VERSION ""

NS_ :

BS_:

BU_: Sound_A Ladegeraet_PAG_PF Motor_EDC17_Pirol PSM_Ant_Derivate GW_Routing_Derivate GW_Applikation_Derivate BMS_Hybrid Getriebe_Derivate LEH_Hybrid Motor_MED17_Hybrid Sound_I Tool Airbag Waehlhebel

BO_ 157 Motor_Hybrid_01: 8 Motor_MED17_Hybrid
 SG_ MO_HYB_EMode_Info : 14|2@1+ (1,0) [0|3] ""  Getriebe_Derivate
 SG_ Motor_Hybrid_01_CHK : 0|8@1+ (1,0) [0|255] ""  Getriebe_Derivate
 SG_ Motor_Hybrid_01_BZ : 8|4@1+ (1,0) [0|15] ""  BMS_Hybrid,Getriebe_Derivate
 SG_ MO_HYB_IstStatusK0 : 12|2@1+ (1,0) [0|3] ""  Getriebe_Derivate
 SG_ MO_HYB_max_ind_VM_Mom : 16|10@1+ (1,0) [0|1021] "Unit_NewtoMeter"  Getriebe_Derivate
 SG_ MO_HYB_Zielzustand : 26|3@1+ (1,0) [0|7] ""  BMS_Hybrid,Getriebe_Derivate
 SG_ MO_HYB_Startmodus : 29|3@1+ (1,0) [0|7] ""  Getriebe_Derivate
 SG_ MO_HYB_Startmodus_PQ3x : 32|1@1+ (1,0) [0|1] "" Vector__XXX
 SG_ MO_HYB_Stoppmodus : 33|1@1+ (1,0) [0|1] "" Vector__XXX
 SG_ MO_HYB_VM_Mom_oE : 40|10@1+ (1,-100) [-100|922] "Unit_NewtoMeter"  Getriebe_Derivate
 SG_ MO_HYB_VM_aktiv : 50|1@1+ (1,0) [0|1] ""  BMS_Hybrid,Getriebe_Derivate,GW_Routing_Derivate
 SG_ MO_HYB_Schaltverhinderung : 51|1@1+ (1,0) [0|1] ""  Getriebe_Derivate
 SG_ MO_HYB_Selektor_Momverlauf_EM M : 53|3@1+ (1,0) [0|7] ""  Getriebe_Derivate
 SG_ MO_HYB_Momverlauf_Rek m1 : 56|8@1+ (2,0) [0|510] "Unit_NewtoMeter"  Getriebe_Derivate
 SG_ MO_HYB_KnickDZ_Rek m2 : 56|8@1+ (12.5,0) [0|3150] "Unit_MinutInver"  Getriebe_Derivate
 SG_ MO_HYB_Momverlauf_EM m3 : 56|8@1+ (2,0) [0|510] "Unit_NewtoMeter"  Getriebe_Derivate
 SG_ MO_HYB_KnickDZ_EM m4 : 56|8@1+ (12.5,0) [0|3150] "Unit_MinutInver"  Getriebe_Derivate

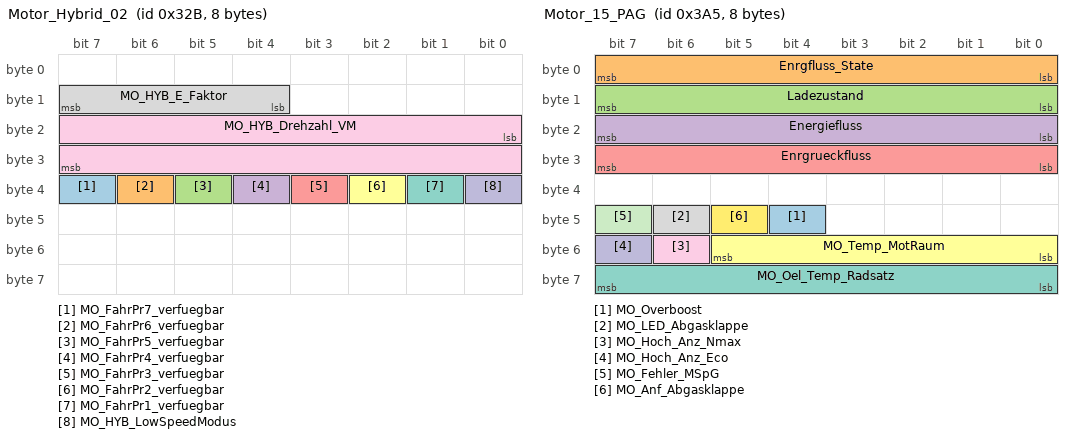
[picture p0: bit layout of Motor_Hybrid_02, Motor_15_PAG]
BO_ 811 Motor_Hybrid_02: 8 Motor_MED17_Hybrid
 SG_ MO_FahrPr7_verfuegbar : 39|1@1+ (1,0) [0|1] ""  GW_Routing_Derivate
 SG_ MO_FahrPr6_verfuegbar : 38|1@1+ (1,0) [0|1] ""  GW_Routing_Derivate
 SG_ MO_FahrPr5_verfuegbar : 37|1@1+ (1,0) [0|1] ""  GW_Routing_Derivate
 SG_ MO_FahrPr4_verfuegbar : 36|1@1+ (1,0) [0|1] ""  GW_Routing_Derivate
 SG_ MO_FahrPr3_verfuegbar : 35|1@1+ (1,0) [0|1] ""  GW_Routing_Derivate
 SG_ MO_FahrPr2_verfuegbar : 34|1@1+ (1,0) [0|1] ""  GW_Routing_Derivate
 SG_ MO_FahrPr1_verfuegbar : 33|1@1+ (1,0) [0|1] ""  GW_Routing_Derivate
 SG_ MO_HYB_E_Faktor : 12|4@1+ (1,0) [0|15] ""  Getriebe_Derivate,GW_Routing_Derivate
 SG_ MO_HYB_Drehzahl_VM : 16|16@1+ (0.25,0) [0|16256] "Unit_MinutInver"  Getriebe_Derivate,GW_Routing_Derivate,BMS_Hybrid
 SG_ MO_HYB_LowSpeedModus : 32|1@1+ (1,0) [0|1] ""  Getriebe_Derivate,GW_Routing_Derivate

BO_ 933 Motor_15_PAG: 8 Motor_MED17_Hybrid
 SG_ MO_Overboost : 44|1@1+ (1,0) [0|1] ""  GW_Routing_Derivate
 SG_ Enrgfluss_State : 0|8@1+ (1,0) [0|255] ""  GW_Routing_Derivate
 SG_ Ladezustand : 8|8@1+ (1,0) [0|100] "Unit_PerCent"  GW_Routing_Derivate
 SG_ Energiefluss : 16|8@1+ (1,-128) [-100|100] "Unit_PerCent"  GW_Routing_Derivate
 SG_ Enrgrueckfluss : 24|8@1+ (0.2,0) [0|50.8] ""  GW_Routing_Derivate
 SG_ MO_Temp_MotRaum : 48|6@1+ (3,-48) [-48|141] "Unit_DegreCelsi"  GW_Routing_Derivate
 SG_ MO_Oel_Temp_Radsatz : 56|8@1+ (1,-60) [-60|193] "Unit_DegreCelsi"  GW_Routing_Derivate
 SG_ MO_LED_Abgasklappe : 46|1@1+ (1,0) [0|1] ""  GW_Routing_Derivate
 SG_ MO_Hoch_Anz_Nmax : 54|1@1+ (1,0) [0|1] ""  GW_Routing_Derivate
 SG_ MO_Hoch_Anz_Eco : 55|1@1+ (1,0) [0|1] ""  GW_Routing_Derivate
 SG_ MO_Fehler_MSpG : 47|1@1+ (1,0) [0|1] ""  GW_Routing_Derivate
 SG_ MO_Anf_Abgasklappe : 45|1@1+ (1,0) [0|1] ""  GW_Routing_Derivate

BO_ 1730 NMH_Getriebe: 7 Getriebe_Derivate
 SG_ NMH_GE_N_Haltephase : 19|1@1+ (1,0) [0|1] "" Vector__XXX
 SG_ NMH_GE_Start_1 : 0|1@1+ (1,0) [0|1] ""  Motor_EDC17_Pirol,BMS_Hybrid,LEH_Hybrid,Ladegeraet_PAG_PF,GW_Applikation_Derivate,Motor_MED17_Hybrid
 SG_ NMH_GE_Start_2 : 1|1@1+ (1,0) [0|1] ""  GW_Applikation_Derivate
 SG_ NMH_GE_Normal_Mode_1 : 2|1@1+ (1,0) [0|1] ""  GW_Applikation_Derivate
 SG_ NMH_GE_Normal_Mode_2 : 3|1@1+ (1,0) [0|1] ""  GW_Applikation_Derivate
 SG_ NMH_GE_Car_WakeUp : 6|1@1+ (1,0) [0|1] "" Vector__XXX
 SG_ NMH_GE_Per_WakeUp : 8|5@1+ (1,0) [0|31] "" Vector__XXX
 SG_ NMH_GE_Fkt_WakeUp : 13|3@1+ (1,0) [0|7] "" Vector__XXX
 SG_ NMH_GE_NM_aktiv_Klemme_15 : 16|1@1+ (1,0) [0|1] "" Vector__XXX
 SG_ NMH_GE_NM_aktiv_Diagnose : 17|1@1+ (1,0) [0|1] "" Vector__XXX
 SG_ NMH_GE_NM_aktiv_Start : 18|1@1+ (1,0) [0|1] "" Vector__XXX
 SG_ NMH_GE_kein_NL : 24|1@1+ (1,0) [0|1] "" Vector__XXX
 SG_ NMH_GE_NL_Daten_EEPROM : 25|1@1+ (1,0) [0|1] "" Vector__XXX
 SG_ NMH_GE_NL_Drucksens : 26|1@1+ (1,0) [0|1] "" Vector__XXX
 SG_ NMH_GE_NL_Abtrieb : 27|1@1+ (1,0) [0|1] "" Vector__XXX
 SG_ NMH_GE_NL_Waehlhebel : 28|1@1+ (1,0) [0|1] "" Vector__XXX
 SG_ NMH_GE_NL_Wegfahrsperre : 29|1@1+ (1,0) [0|1] "" Vector__XXX
 SG_ NM_GE_Signalfehler : 32|1@1+ (1,0) [0|1] "" Vector__XXX
 SG_ NMH_GE_TimeOut_Fehler : 33|1@1+ (1,0) [0|1] "" Vector__XXX
 SG_ NMH_GE_CAN_Diag_deaktiv : 34|1@1+ (1,0) [0|1] "" Vector__XXX
 SG_ NMH_GE_KompSchutz : 35|1@1+ (1,0) [0|1] "" Vector__XXX
 SG_ NMH_GE_Mute_Mode : 36|1@1+ (1,0) [0|1] "" Vector__XXX
 SG_ NMH_GE_Transport_Mode : 37|1@1+ (1,0) [0|1] "" Vector__XXX
 SG_ NMH_GE_Abschaltstufe_aktiv : 38|1@1+ (1,0) [0|1] "" Vector__XXX
 SG_ NMH_GE_Eindraht_Fehler : 39|1@1+ (1,0) [0|1] "" Vector__XXX
 SG_ NMH_GE_Lokalaktiv : 48|1@1+ (1,0) [0|1] "" Vector__XXX
 SG_ NMH_GE_Subsystemaktiv : 49|1@1+ (1,0) [0|1] "" Vector__XXX
 SG_ NMH_GSG_Subbusaktiv : 50|1@1+ (1,0) [0|1] "" Vector__XXX

BO_ 1729 NMH_Motor: 7 Motor_MED17_Hybrid
 SG_ NMH_MO_Start_1 : 0|1@1+ (1,0) [0|1] ""  BMS_Hybrid,LEH_Hybrid,Ladegeraet_PAG_PF,GW_Applikation_Derivate,Getriebe_Derivate
 SG_ NMH_MO_Start_2 : 1|1@1+ (1,0) [0|1] ""  GW_Applikation_Derivate
 SG_ NMH_MO_Normal_Mode_1 : 2|1@1+ (1,0) [0|1] ""  GW_Applikation_Derivate
 SG_ NMH_MO_NM_aktiv_HV_Abschaltung : 21|1@1+ (1,0) [0|1] "" Vector__XXX
 SG_ NMH_MO_Normal_Mode_2 : 3|1@1+ (1,0) [0|1] ""  GW_Applikation_Derivate
 SG_ NMH_MO_Car_WakeUp : 6|1@1+ (1,0) [0|1] "" Vector__XXX
 SG_ NMH_MO_Per_WakeUp : 8|5@1+ (1,0) [0|31] "" Vector__XXX
 SG_ NMH_MO_Fkt_WakeUp : 13|3@1+ (1,0) [0|7] "" Vector__XXX
 SG_ NMH_MO_NM_aktiv_Klemme_15 : 16|1@1+ (1,0) [0|1] "" Vector__XXX
 SG_ NMH_MO_NM_aktiv_Diagnose : 17|1@1+ (1,0) [0|1] "" Vector__XXX
 SG_ NMH_MO_NM_aktiv_Start : 18|1@1+ (1,0) [0|1] "" Vector__XXX
 SG_ NMH_MO_NM_aktiv_EKP_Vorlauf : 19|1@1+ (1,0) [0|1] "" Vector__XXX
 SG_ NMH_MO_NM_aktiv_STH_Betrieb : 20|1@1+ (1,0) [0|1] "" Vector__XXX
 SG_ NMH_MO_kein_NL : 24|1@1+ (1,0) [0|1] "" Vector__XXX
 SG_ NMH_MO_NL_Kuehlerluefter : 25|1@1+ (1,0) [0|1] "" Vector__XXX
 SG_ NMH_MO_NL_Diagnose : 26|1@1+ (1,0) [0|1] "" Vector__XXX
 SG_ NMH_MO_NL_WFS : 27|1@1+ (1,0) [0|1] "" Vector__XXX
 SG_ NMH_MO_NL_EEPROM : 28|1@1+ (1,0) [0|1] "" Vector__XXX
 SG_ NMH_MO_NL_Sonstige : 29|1@1+ (1,0) [0|1] "" Vector__XXX
 SG_ NM_MO_Signalfehler : 32|1@1+ (1,0) [0|1] "" Vector__XXX
 SG_ NMH_MO_TimeOut_Fehler : 33|1@1+ (1,0) [0|1] "" Vector__XXX
 SG_ NMH_MO_CAN_Diag_deaktiv : 34|1@1+ (1,0) [0|1] "" Vector__XXX
 SG_ NMH_MO_KompSchutz : 35|1@1+ (1,0) [0|1] "" Vector__XXX
 SG_ NMH_MO_Mute_Mode : 36|1@1+ (1,0) [0|1] "" Vector__XXX
 SG_ NMH_MO_Transport_Mode : 37|1@1+ (1,0) [0|1] "" Vector__XXX
 SG_ NMH_MO_Abschaltstufe_aktiv : 38|1@1+ (1,0) [0|1] "" Vector__XXX
 SG_ NMH_MO_Eindraht_Fehler : 39|1@1+ (1,0) [0|1] "" Vector__XXX
 SG_ NMH_MO_Lokalaktiv : 48|1@1+ (1,0) [0|1] "" Vector__XXX
 SG_ NMH_MO_Subsystemaktiv : 49|1@1+ (1,0) [0|1] "" Vector__XXX

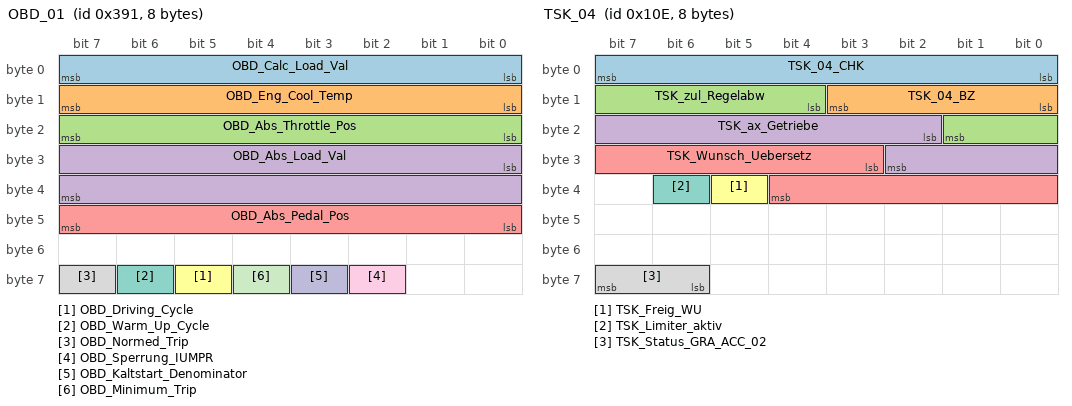
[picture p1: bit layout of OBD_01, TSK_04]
BO_ 913 OBD_01: 8 Motor_MED17_Hybrid
 SG_ OBD_Calc_Load_Val : 0|8@1+ (0.39215686275,0) [0|100] "Unit_PerCent"  BMS_Hybrid,Getriebe_Derivate,LEH_Hybrid
 SG_ OBD_Eng_Cool_Temp : 8|8@1+ (1,-40) [-40|215] "Unit_DegreCelsi"  BMS_Hybrid,Getriebe_Derivate,LEH_Hybrid
 SG_ OBD_Abs_Throttle_Pos : 16|8@1+ (0.39215686275,0) [0|100] "Unit_PerCent"  BMS_Hybrid,Getriebe_Derivate,LEH_Hybrid
 SG_ OBD_Abs_Load_Val : 24|16@1+ (0.39215686275,0) [0|25700] "Unit_PerCent"  BMS_Hybrid,Getriebe_Derivate,LEH_Hybrid
 SG_ OBD_Abs_Pedal_Pos : 40|8@1+ (0.39215686275,0) [0|100] "Unit_PerCent"  BMS_Hybrid,Getriebe_Derivate,LEH_Hybrid
 SG_ OBD_Driving_Cycle : 61|1@1+ (1,0) [0|1] ""  BMS_Hybrid,Getriebe_Derivate,LEH_Hybrid
 SG_ OBD_Warm_Up_Cycle : 62|1@1+ (1,0) [0|1] ""  BMS_Hybrid,Getriebe_Derivate,LEH_Hybrid,GW_Applikation_Derivate
 SG_ OBD_Normed_Trip : 63|1@1+ (1,0) [0|1] ""  LEH_Hybrid,BMS_Hybrid,Getriebe_Derivate
 SG_ OBD_Sperrung_IUMPR : 58|1@1+ (1,0) [0|1] ""  BMS_Hybrid
 SG_ OBD_Kaltstart_Denominator : 59|1@1+ (1,0) [0|1] ""  LEH_Hybrid,BMS_Hybrid
 SG_ OBD_Minimum_Trip : 60|1@1+ (1,0) [0|1] ""  LEH_Hybrid,Getriebe_Derivate,BMS_Hybrid

BO_ 270 TSK_04: 8 Motor_MED17_Hybrid
 SG_ TSK_04_CHK : 0|8@1+ (1,0) [0|255] ""  Getriebe_Derivate
 SG_ TSK_04_BZ : 8|4@1+ (1,0) [0|15] ""  Getriebe_Derivate
 SG_ TSK_zul_Regelabw : 12|6@1+ (0.024,0) [0|1.512] "Unit_MeterPerSeconSquar"  Getriebe_Derivate
 SG_ TSK_ax_Getriebe : 18|9@1+ (0.024,-2.016) [-2.016|10.224] "Unit_MeterPerSeconSquar"  Getriebe_Derivate
 SG_ TSK_Wunsch_Uebersetz : 27|10@1+ (0.0245,0) [0.0245|25.0635] "" Vector__XXX
 SG_ TSK_Freig_WU : 37|1@1+ (1,0) [0|1] "" Vector__XXX
 SG_ TSK_Limiter_aktiv : 38|1@1+ (1,0) [0|1] ""  Getriebe_Derivate
 SG_ TSK_Status_GRA_ACC_02 : 62|2@1+ (1,0) [0|3] ""  Getriebe_Derivate

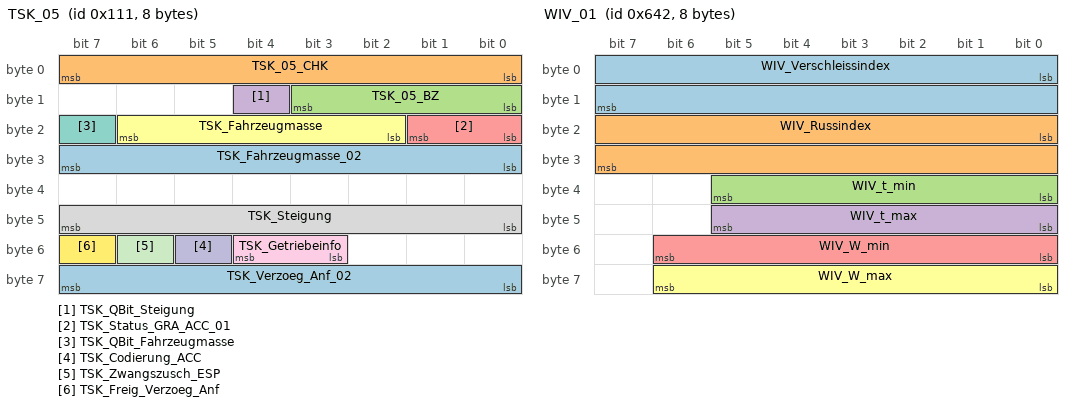
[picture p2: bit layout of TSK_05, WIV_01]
BO_ 273 TSK_05: 8 Motor_MED17_Hybrid
 SG_ TSK_Fahrzeugmasse_02 : 24|8@1+ (32,0) [0|8128] "Unit_KiloGram"  GW_Routing_Derivate
 SG_ TSK_05_CHK : 0|8@1+ (1,0) [0|255] ""  PSM_Ant_Derivate,GW_Routing_Derivate,Getriebe_Derivate
 SG_ TSK_05_BZ : 8|4@1+ (1,0) [0|15] ""  PSM_Ant_Derivate,GW_Routing_Derivate,Getriebe_Derivate
 SG_ TSK_QBit_Steigung : 12|1@1+ (1,0) [0|1] ""  GW_Routing_Derivate
 SG_ TSK_Status_GRA_ACC_01 : 16|2@1+ (1,0) [0|3] ""  PSM_Ant_Derivate,GW_Routing_Derivate
 SG_ TSK_Fahrzeugmasse : 18|5@1+ (200,500) [500|6500] "Unit_KiloGram"  Getriebe_Derivate,GW_Routing_Derivate
 SG_ TSK_QBit_Fahrzeugmasse : 23|1@1+ (1,0) [0|1] ""  GW_Routing_Derivate
 SG_ TSK_Steigung : 40|8@1+ (0.8,-101.6) [-101.6|101.6] "Unit_PerCent"  GW_Routing_Derivate
 SG_ TSK_Getriebeinfo : 51|2@1+ (1,0) [0|3] ""  GW_Routing_Derivate
 SG_ TSK_Codierung_ACC : 53|1@1+ (1,0) [0|1] ""  GW_Routing_Derivate
 SG_ TSK_Zwangszusch_ESP : 54|1@1+ (1,0) [0|1] ""  GW_Routing_Derivate
 SG_ TSK_Freig_Verzoeg_Anf : 55|1@1+ (1,0) [0|1] ""  GW_Routing_Derivate
 SG_ TSK_Verzoeg_Anf_02 : 56|8@1+ (0.024,-3.984) [-3.984|2.136] "Unit_MeterPerSeconSquar"  GW_Routing_Derivate

BO_ 915 WBA_02: 8 Getriebe_Derivate
 SG_ GE_Tipschaltempf_verfuegbar m0 : 43|1@1+ (1,0) [0|1] ""  GW_Routing_Derivate
 SG_ GE_Sollgang m0 : 44|4@1+ (1,0) [0|15] ""  GW_Routing_Derivate
 SG_ WBA_GE_Zusatzwarnungen m0 : 39|3@1+ (1,0) [0|7] ""  GW_Routing_Derivate
 SG_ WBA_Effizienzmodus : 14|1@1+ (1,0) [0|1] ""  GW_Routing_Derivate
 SG_ WBA_Sollgang m1 : 28|4@1+ (1,0) [0|15] ""  GW_Routing_Derivate
 SG_ WBA_02_BZ : 8|4@1+ (1,0) [0|15] ""  GW_Routing_Derivate
 SG_ WBA_Senderkennung M : 12|1@1+ (1,0) [0|1] ""  GW_Routing_Derivate
 SG_ WBA_Lampe_Shift_Lock m0 : 13|1@1+ (1,0) [0|1] ""  GW_Routing_Derivate
 SG_ WBA_Blinken m0 : 16|1@1+ (1,0) [0|1] ""  GW_Routing_Derivate
 SG_ WBA_Getriebevariante m0 : 17|4@1+ (1,0) [0|15] ""  GW_Routing_Derivate
 SG_ WBA_GE_Warnung : 21|3@1+ (1,0) [0|7] ""  GW_Routing_Derivate
 SG_ WBA_Fahrstufe m0 : 24|4@1+ (1,0) [0|15] ""  GW_Routing_Derivate
 SG_ WBA_Schaltempf_verfbar m1 : 13|1@1+ (1,0) [0|1] ""  GW_Routing_Derivate
 SG_ WBA_eing_Gang m0 : 28|4@1+ (1,0) [0|15] ""  GW_Routing_Derivate
 SG_ WBA_Istgang m1 : 24|4@1+ (1,0) [0|15] ""  GW_Routing_Derivate
 SG_ WBA_GE_Texte m0 : 32|3@1+ (1,0) [0|7] ""  GW_Routing_Derivate
 SG_ WBA_Schaltschema_Aktiv m0 : 35|1@1+ (1,0) [0|1] ""  GW_Routing_Derivate
 SG_ WH_Warnung m0 : 36|3@1+ (1,0) [0|7] ""  GW_Routing_Derivate
 SG_ WBA_02_CHK : 0|8@1+ (1,0) [0|255] ""  GW_Routing_Derivate

BO_ 1602 WIV_01: 8 Motor_MED17_Hybrid
 SG_ WIV_Verschleissindex : 0|16@1+ (2E-008,0) [0|0.00131068] ""  GW_Routing_Derivate
 SG_ WIV_Russindex : 16|16@1+ (2E-008,0) [0|0.00131068] ""  GW_Routing_Derivate
 SG_ WIV_t_min : 32|6@1+ (1,0) [0|63] "Unit_Month"  GW_Routing_Derivate
 SG_ WIV_t_max : 40|6@1+ (1,0) [0|63] "Unit_Month"  GW_Routing_Derivate
 SG_ WIV_W_min : 48|7@1+ (1000,0) [0|127000] "Unit_KiloMeter"  GW_Routing_Derivate
 SG_ WIV_W_max : 56|7@1+ (1000,0) [0|127000] "Unit_KiloMeter"  GW_Routing_Derivate

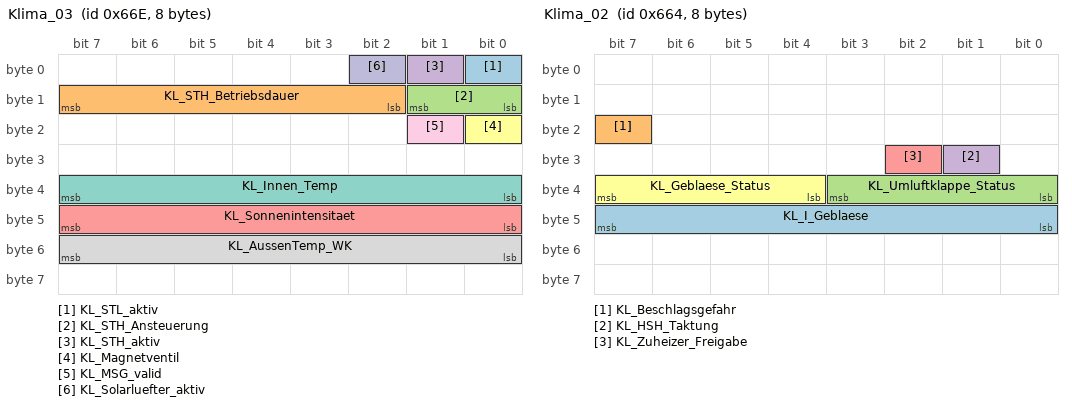
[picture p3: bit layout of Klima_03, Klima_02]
BO_ 1646 Klima_03: 8 GW_Routing_Derivate
 SG_ KL_STL_aktiv : 0|1@1+ (1,0) [0|1] "" Vector__XXX
 SG_ KL_STH_Betriebsdauer : 10|6@1+ (1,0) [0|60] "min" Vector__XXX
 SG_ KL_STH_Ansteuerung : 8|2@1+ (1,0) [0|3] "" Vector__XXX
 SG_ KL_STH_aktiv : 1|1@1+ (1,0) [0|1] "" Vector__XXX
 SG_ KL_Sonnenintensitaet : 40|8@1+ (10,0) [0|1000] "W/qm" Vector__XXX
 SG_ KL_Magnetventil : 16|1@1+ (1,0) [0|1] "" Vector__XXX
 SG_ KL_Innen_Temp : 32|8@1+ (0.5,-50) [-50|77.5] "°C"  BMS_Hybrid
 SG_ KL_AussenTemp_WK : 48|8@1+ (0.5,-50) [-50|76] "°C"  BMS_Hybrid
 SG_ KL_MSG_valid : 17|1@1+ (1,0) [0|1] "" Vector__XXX
 SG_ KL_Solarluefter_aktiv : 2|1@1+ (1,0) [0|1] "" Vector__XXX

BO_ 1636 Klima_02: 8 GW_Routing_Derivate
 SG_ KL_I_Geblaese : 40|8@1+ (0.25,0) [0|63.5] "Unit_Amper" Vector__XXX
 SG_ KL_Beschlagsgefahr : 23|1@1+ (1,0) [0|1] "" Vector__XXX
 SG_ KL_Umluftklappe_Status : 32|4@1+ (1,0) [0|15] ""  BMS_Hybrid
 SG_ KL_HSH_Taktung : 25|1@1+ (1,0) [0|1] "" Vector__XXX
 SG_ KL_Zuheizer_Freigabe : 26|1@1+ (1,0) [0|1] "" Vector__XXX
 SG_ KL_Geblaese_Status : 36|4@1+ (1,0) [0|15] ""  BMS_Hybrid

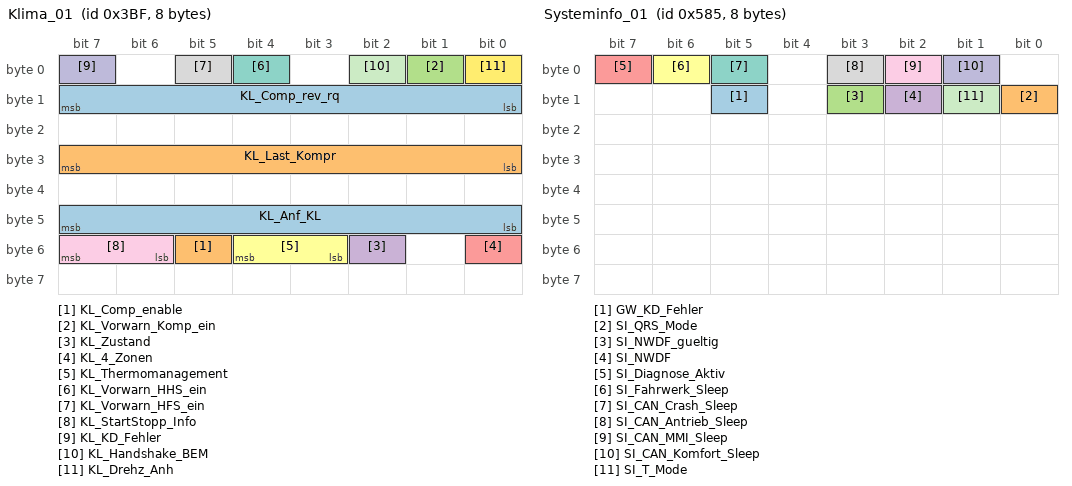
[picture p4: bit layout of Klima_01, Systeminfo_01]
BO_ 959 Klima_01: 8 GW_Routing_Derivate
 SG_ KL_Comp_rev_rq : 8|8@1+ (50,0) [0|8600] "Unit_MinutInver" Vector__XXX
 SG_ KL_Comp_enable : 53|1@1+ (1,0) [0|1] "" Vector__XXX
 SG_ KL_Vorwarn_Komp_ein : 1|1@1+ (1,0) [0|1] ""  Motor_EDC17_Pirol,Motor_MED17_Hybrid
 SG_ KL_Zustand : 50|1@1+ (1,0) [0|1] ""  BMS_Hybrid,Motor_EDC17_Pirol,Motor_MED17_Hybrid
 SG_ KL_4_Zonen : 48|1@1+ (1,0) [0|1] ""  Motor_EDC17_Pirol,Motor_MED17_Hybrid
 SG_ KL_Thermomanagement : 51|2@1+ (1,0) [0|3] ""  Motor_EDC17_Pirol,Motor_MED17_Hybrid
 SG_ KL_Vorwarn_HHS_ein : 4|1@1+ (1,0) [0|1] ""  Motor_EDC17_Pirol,Motor_MED17_Hybrid
 SG_ KL_Vorwarn_HFS_ein : 5|1@1+ (1,0) [0|1] ""  Motor_EDC17_Pirol,Motor_MED17_Hybrid
 SG_ KL_StartStopp_Info : 54|2@1+ (1,0) [0|3] ""  Motor_EDC17_Pirol,Motor_MED17_Hybrid
 SG_ KL_KD_Fehler : 7|1@1+ (1,0) [0|1] "" Vector__XXX
 SG_ KL_Handshake_BEM : 2|1@1+ (1,0) [0|1] "" Vector__XXX
 SG_ KL_Drehz_Anh : 0|1@1+ (1,0) [0|1] ""  Motor_EDC17_Pirol,Motor_MED17_Hybrid
 SG_ KL_Anf_KL : 40|8@1+ (0.4,0) [0|100] "%"  Motor_EDC17_Pirol,Motor_MED17_Hybrid
 SG_ KL_Last_Kompr : 24|8@1+ (0.25,0) [0|63.5] "Nm"  Motor_EDC17_Pirol

BO_ 2041 Response_Airbag_Deployment: 8 Airbag
 SG_ Response_Airbag_Deployment : 0|64@1+ (1,0) [0|4294967295] ""  GW_Routing_Derivate

BO_ 2033 Request_Airbag_Deployment: 8 GW_Routing_Derivate
 SG_ Request_Airbag_Deployment : 0|64@1+ (1,0) [0|4294967295] ""  Airbag

BO_ 1413 Systeminfo_01: 8 GW_Applikation_Derivate
 SG_ GW_KD_Fehler : 13|1@1+ (1,0) [0|1] "" Vector__XXX
 SG_ SI_QRS_Mode : 8|1@1+ (1,0) [0|1] ""  Motor_MED17_Hybrid,Motor_EDC17_Pirol
 SG_ SI_NWDF_gueltig : 11|1@1+ (1,0) [0|1] "" Vector__XXX
 SG_ SI_NWDF : 10|1@1+ (1,0) [0|1] "" Vector__XXX
 SG_ SI_Diagnose_Aktiv : 7|1@1+ (1,0) [0|1] "" Vector__XXX
 SG_ SI_Fahrwerk_Sleep : 6|1@1+ (1,0) [0|1] "" Vector__XXX
 SG_ SI_CAN_Crash_Sleep : 5|1@1+ (1,0) [0|1] "" Vector__XXX
 SG_ SI_CAN_Antrieb_Sleep : 3|1@1+ (1,0) [0|1] "" Vector__XXX
 SG_ SI_CAN_MMI_Sleep : 2|1@1+ (1,0) [0|1] "" Vector__XXX
 SG_ SI_CAN_Komfort_Sleep : 1|1@1+ (1,0) [0|1] "" Vector__XXX
 SG_ SI_T_Mode : 9|1@1+ (1,0) [0|1] ""  Motor_EDC17_Pirol,Motor_MED17_Hybrid,Airbag

BO_ 2616986624 CCP_MO_CRO_02: 8 Tool
 SG_ CCP_MO_CRO_02_Data : 0|64@1+ (1,0) [0|1] ""  Motor_MED17_Hybrid,Motor_EDC17_Pirol

BO_ 480 CCP_MO_CRO_01: 8 Tool
 SG_ CCP_MO_CRO_01_Data : 0|64@1+ (1,0) [0|1] ""  Motor_MED17_Hybrid,Motor_EDC17_Pirol

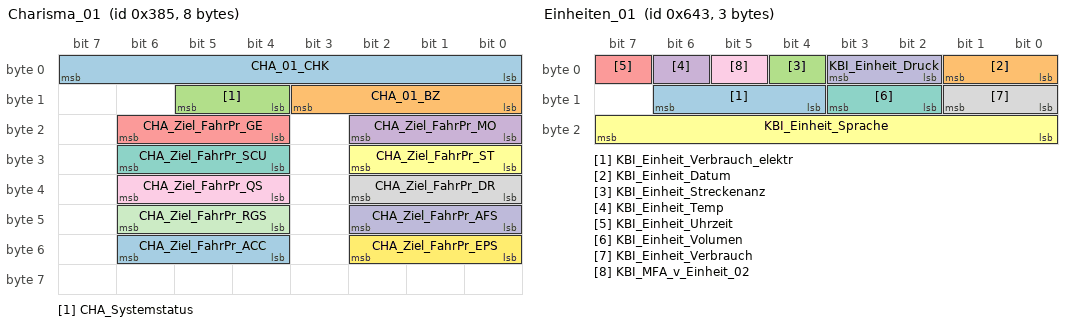
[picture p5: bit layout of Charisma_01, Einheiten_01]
BO_ 901 Charisma_01: 8 GW_Routing_Derivate
 SG_ CHA_01_CHK : 0|8@1+ (1,0) [0|255] ""  Motor_EDC17_Pirol,Motor_MED17_Hybrid
 SG_ CHA_01_BZ : 8|4@1+ (1,0) [0|15] ""  Motor_EDC17_Pirol,Motor_MED17_Hybrid
 SG_ CHA_Systemstatus : 12|2@1+ (1,0) [0|3] ""  Motor_EDC17_Pirol,Motor_MED17_Hybrid
 SG_ CHA_Ziel_FahrPr_MO : 16|3@1+ (1,0) [0|7] ""  Motor_EDC17_Pirol,Motor_MED17_Hybrid
 SG_ CHA_Ziel_FahrPr_GE : 20|3@1+ (1,0) [0|7] ""  Getriebe_Derivate
 SG_ CHA_Ziel_FahrPr_ST : 24|3@1+ (1,0) [0|7] "" Vector__XXX
 SG_ CHA_Ziel_FahrPr_SCU : 28|3@1+ (1,0) [0|7] "" Vector__XXX
 SG_ CHA_Ziel_FahrPr_DR : 32|3@1+ (1,0) [0|7] "" Vector__XXX
 SG_ CHA_Ziel_FahrPr_QS : 36|3@1+ (1,0) [0|7] "" Vector__XXX
 SG_ CHA_Ziel_FahrPr_AFS : 40|3@1+ (1,0) [0|7] "" Vector__XXX
 SG_ CHA_Ziel_FahrPr_RGS : 44|3@1+ (1,0) [0|7] "" Vector__XXX
 SG_ CHA_Ziel_FahrPr_EPS : 48|3@1+ (1,0) [0|7] "" Vector__XXX
 SG_ CHA_Ziel_FahrPr_ACC : 52|3@1+ (1,0) [0|7] "" Vector__XXX

BO_ 24 WFS_MSG4_IMS: 8 LEH_Hybrid
 SG_ WFS_MSG4_IMS : 0|64@1+ (1,0) [0|1.84467440737096E+019] ""  GW_Routing_Derivate

BO_ 25 WFS_IMS_MSG4: 8 GW_Routing_Derivate
 SG_ WFS_IMS_MSG4 : 0|64@1+ (1,0) [0|1.84467440737096E+019] ""  LEH_Hybrid

BO_ 1603 Einheiten_01: 3 GW_Routing_Derivate
 SG_ KBI_Einheit_Verbrauch_elektr : 12|3@1+ (1,0) [0|7] "" Vector__XXX
 SG_ KBI_Einheit_Datum : 0|2@1+ (1,0) [0|3] "" Vector__XXX
 SG_ KBI_Einheit_Streckenanz : 4|1@1+ (1,0) [0|1] ""  Motor_EDC17_Pirol
 SG_ KBI_Einheit_Temp : 6|1@1+ (1,0) [0|1] "" Vector__XXX
 SG_ KBI_Einheit_Uhrzeit : 7|1@1+ (1,0) [0|1] "" Vector__XXX
 SG_ KBI_Einheit_Sprache : 16|8@1+ (1,0) [0|255] "" Vector__XXX
 SG_ KBI_Einheit_Volumen : 10|2@1+ (1,0) [0|3] "" Vector__XXX
 SG_ KBI_Einheit_Verbrauch : 8|2@1+ (1,0) [0|3] "" Vector__XXX
 SG_ KBI_MFA_v_Einheit_02 : 5|1@1+ (1,0) [0|1] "" Vector__XXX
 SG_ KBI_Einheit_Druck : 2|2@1+ (1,0) [0|3] "" Vector__XXX

BO_ 267 LS_01_Derivate: 4 GW_Routing_Derivate
 SG_ MFL_Tip_Up : 23|1@1+ (1,0) [0|1] ""  Getriebe_Derivate
 SG_ MFL_Tip_Down : 22|1@1+ (1,0) [0|1] ""  Getriebe_Derivate
 SG_ LS_Verstellung_Zeitluecke : 20|2@1+ (1,0) [0|3] "" Vector__XXX
 SG_ LS_Typ_Hauptschalter : 14|1@1+ (1,0) [0|1] ""  Motor_EDC17_Pirol,Motor_MED17_Hybrid
 SG_ LS_Tiptronic_Fehler : 24|1@1+ (1,0) [0|1] ""  Getriebe_Derivate
 SG_ LS_Tip_Wiederaufnahme : 19|1@1+ (1,0) [0|1] ""  Motor_EDC17_Pirol,Motor_MED17_Hybrid
 SG_ LS_Tip_Setzen : 16|1@1+ (1,0) [0|1] ""  Motor_EDC17_Pirol,Motor_MED17_Hybrid
 SG_ LS_Tip_Runter : 18|1@1+ (1,0) [0|1] ""  Motor_EDC17_Pirol,Motor_MED17_Hybrid
 SG_ LS_Tip_Hoch : 17|1@1+ (1,0) [0|1] ""  Motor_EDC17_Pirol,Motor_MED17_Hybrid
 SG_ LS_Limiter : 15|1@1+ (1,0) [0|1] ""  Motor_EDC17_Pirol,Motor_MED17_Hybrid
 SG_ LS_Hauptschalter : 12|1@1+ (1,0) [0|1] ""  Motor_EDC17_Pirol,Motor_MED17_Hybrid
 SG_ LS_Fehler : 25|1@1+ (1,0) [0|1] ""  Motor_EDC17_Pirol,Motor_MED17_Hybrid
 SG_ LS_Codierung : 26|3@1+ (1,0) [0|7] ""  Motor_EDC17_Pirol,Motor_MED17_Hybrid
 SG_ LS_Abbrechen : 13|1@1+ (1,0) [0|1] ""  Motor_EDC17_Pirol,Motor_MED17_Hybrid
 SG_ LS_01_CHK : 0|8@1+ (1,0) [0|255] ""  Motor_EDC17_Pirol,Motor_MED17_Hybrid,Getriebe_Derivate
 SG_ LS_01_BZ : 8|4@1+ (1,0) [0|15] ""  Motor_EDC17_Pirol,Motor_MED17_Hybrid,Getriebe_Derivate
 SG_ MFL_M_Taste : 31|1@1+ (1,0) [0|1] ""  Getriebe_Derivate
 SG_ LS_Tip_Stufe_2 : 29|1@1+ (1,0) [0|1] ""  Motor_EDC17_Pirol,Motor_MED17_Hybrid
 SG_ LS_GRA_ACC_2stufig : 30|1@1+ (1,0) [0|1] ""  Motor_EDC17_Pirol,Motor_MED17_Hybrid

BO_ 260 EPB_01: 8 GW_Routing_Derivate
 SG_ EPB_Konsistenz_ACC : 55|1@1+ (1,0) [0|1] "" Vector__XXX
 SG_ EPB_Anfahrwunsch_erkannt : 48|1@1+ (1,0) [0|1] "" Vector__XXX
 SG_ EPB_Pedalweg_Kuppl : 32|8@1+ (0.4,0) [8|92] "%"  Motor_EDC17_Pirol,Motor_MED17_Hybrid
 SG_ EPB_Fehlerstatus : 50|2@1+ (1,0) [0|3] ""  Motor_MED17_Hybrid
 SG_ EPB_Schalterposition : 52|2@1+ (1,0) [0|3] ""  Motor_EDC17_Pirol,Motor_MED17_Hybrid
 SG_ EPB_QBit_Schalterpos : 54|1@1+ (1,0) [0|1] ""  Motor_EDC17_Pirol,Motor_MED17_Hybrid
 SG_ EPB_Spannkraft : 56|5@1+ (1,0) [0|29] "kN" Vector__XXX
 SG_ EPB_Status : 61|2@1+ (1,0) [0|3] ""  Motor_EDC17_Pirol,Getriebe_Derivate,Motor_MED17_Hybrid
 SG_ EPB_KD_Fehler : 63|1@1+ (1,0) [0|1] "" Vector__XXX
 SG_ EPB_01_CHK : 0|8@1+ (1,0) [0|255] ""  Getriebe_Derivate,Motor_EDC17_Pirol,Motor_MED17_Hybrid
 SG_ EPB_01_BZ : 8|4@1+ (1,0) [0|15] ""  Getriebe_Derivate,Motor_EDC17_Pirol,Motor_MED17_Hybrid
 SG_ EPB_QBit_Laengsbeschleunigung : 12|1@1+ (1,0) [0|1] "" Vector__XXX
 SG_ EPB_QBit_Pedalweg_Kuppl : 13|1@1+ (1,0) [0|1] ""  Motor_EDC17_Pirol,Motor_MED17_Hybrid
 SG_ EPB_BCM2_Motor_Wakeup : 14|1@1+ (1,0) [0|1] "" Vector__XXX
 SG_ EPB_Freig_Verzoeg_Anf : 15|1@1+ (1,0) [0|1] ""  Motor_EDC17_Pirol,Motor_MED17_Hybrid
 SG_ EPB_Verzoeg_Anf : 16|8@1+ (0.048,-7.968) [-7.968|4.224] "m/s2" Vector__XXX
 SG_ EPB_Laengsbeschleunigung : 24|8@1+ (1,-128) [-128|126] "%g" Vector__XXX

BO_ 64 Airbag_01: 8 Airbag
 SG_ AB_Deaktivierung_HV : 42|3@1+ (1,0) [0|7] ""  GW_Routing_Derivate
 SG_ AB_RGS_Anst : 12|4@1+ (1,0) [0|15] ""  GW_Routing_Derivate
 SG_ AB_Texte_AKS : 36|2@1+ (1,0) [0|3] ""  GW_Routing_Derivate
 SG_ Airbag_01_CHK : 0|8@1+ (1,0) [0|255] ""  GW_Routing_Derivate,Motor_EDC17_Pirol,Getriebe_Derivate,Motor_MED17_Hybrid,LEH_Hybrid,BMS_Hybrid
 SG_ Airbag_01_BZ : 8|4@1+ (1,0) [0|15] ""  GW_Routing_Derivate,Motor_EDC17_Pirol,Getriebe_Derivate,Motor_MED17_Hybrid,LEH_Hybrid,BMS_Hybrid
 SG_ AB_Front_Crash : 16|1@1+ (1,0) [0|1] ""  GW_Routing_Derivate,GW_Applikation_Derivate
 SG_ AB_Heck_Crash : 17|1@1+ (1,0) [0|1] ""  GW_Routing_Derivate,GW_Applikation_Derivate
 SG_ AB_SF_Crash : 18|1@1+ (1,0) [0|1] ""  GW_Routing_Derivate,GW_Applikation_Derivate
 SG_ AB_SB_Crash : 19|1@1+ (1,0) [0|1] ""  GW_Routing_Derivate,GW_Applikation_Derivate
 SG_ AB_Rollover_Crash : 20|1@1+ (1,0) [0|1] ""  GW_Routing_Derivate,GW_Applikation_Derivate
 SG_ AB_Crash_Int : 21|3@1+ (1,0) [0|7] ""  GW_Routing_Derivate,Motor_EDC17_Pirol,Getriebe_Derivate,Motor_MED17_Hybrid,LEH_Hybrid,BMS_Hybrid
 SG_ AB_Lampe : 24|1@1+ (1,0) [0|1] ""  GW_Routing_Derivate
 SG_ AB_Deaktiviert : 25|1@1+ (1,0) [0|1] ""  GW_Routing_Derivate
 SG_ AB_VB_deaktiviert : 26|1@1+ (1,0) [0|1] ""  GW_Routing_Derivate
 SG_ AB_Systemfehler : 27|1@1+ (1,0) [0|1] ""  GW_Routing_Derivate,LEH_Hybrid,BMS_Hybrid
 SG_ AB_Diagnose : 28|1@1+ (1,0) [0|1] ""  GW_Routing_Derivate
 SG_ AB_Stellgliedtest : 29|1@1+ (1,0) [0|1] ""  LEH_Hybrid,GW_Routing_Derivate,Motor_EDC17_Pirol,BMS_Hybrid,Motor_MED17_Hybrid
 SG_ AB_Erh_Auf_VB : 30|2@1+ (1,0) [0|3] ""  GW_Routing_Derivate
 SG_ AB_Gurtwarn_VF : 32|1@1+ (1,0) [0|1] ""  GW_Routing_Derivate
 SG_ AB_Gurtwarn_VB : 33|1@1+ (1,0) [0|1] ""  GW_Routing_Derivate
 SG_ AB_Anzeige_Fussg : 34|2@1+ (1,0) [0|3] ""  GW_Routing_Derivate
 SG_ AB_PAO_Leuchte_Anf : 38|1@1+ (1,0) [0|1] ""  GW_Routing_Derivate
 SG_ void_Byte_02 : 48|8@1+ (1,0) [0|255] ""  GW_Routing_Derivate
 SG_ void_Byte_03 : 56|7@1+ (1,0) [0|127] ""  GW_Routing_Derivate
 SG_ AB_KD_Fehler : 63|1@1+ (1,0) [0|1] ""  GW_Routing_Derivate,GW_Applikation_Derivate

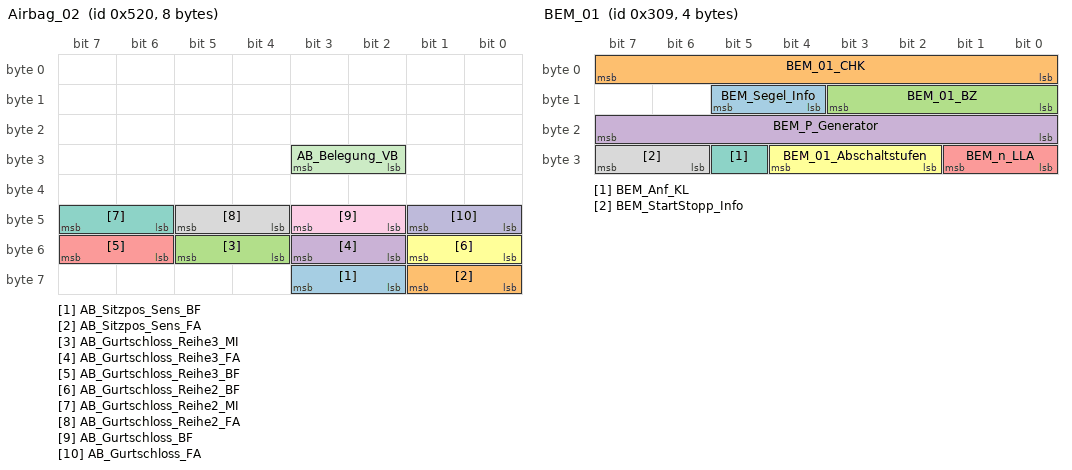
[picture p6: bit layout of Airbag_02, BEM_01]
BO_ 1312 Airbag_02: 8 Airbag
 SG_ AB_Sitzpos_Sens_BF : 58|2@1+ (1,0) [0|3] "" Vector__XXX
 SG_ AB_Sitzpos_Sens_FA : 56|2@1+ (1,0) [0|3] "" Vector__XXX
 SG_ AB_Gurtschloss_Reihe3_MI : 52|2@1+ (1,0) [0|3] "" Vector__XXX
 SG_ AB_Gurtschloss_Reihe3_FA : 50|2@1+ (1,0) [0|3] "" Vector__XXX
 SG_ AB_Gurtschloss_Reihe3_BF : 54|2@1+ (1,0) [0|3] "" Vector__XXX
 SG_ AB_Gurtschloss_Reihe2_BF : 48|2@1+ (1,0) [0|3] "" Vector__XXX
 SG_ AB_Gurtschloss_Reihe2_MI : 46|2@1+ (1,0) [0|3] "" Vector__XXX
 SG_ AB_Gurtschloss_Reihe2_FA : 44|2@1+ (1,0) [0|3] "" Vector__XXX
 SG_ AB_Gurtschloss_BF : 42|2@1+ (1,0) [0|3] "" Vector__XXX
 SG_ AB_Gurtschloss_FA : 40|2@1+ (1,0) [0|3] ""  GW_Routing_Derivate,Motor_EDC17_Pirol,Motor_MED17_Hybrid
 SG_ AB_Belegung_VB : 26|2@1+ (1,0) [0|3] "" Vector__XXX

BO_ 777 BEM_01: 4 GW_Applikation_Derivate
 SG_ BEM_Segel_Info : 12|2@1+ (1,0) [0|3] "" Vector__XXX
 SG_ BEM_01_CHK : 0|8@1+ (1,0) [0|255] ""  Motor_EDC17_Pirol,Motor_MED17_Hybrid
 SG_ BEM_01_BZ : 8|4@1+ (1,0) [0|15] ""  Motor_EDC17_Pirol,Motor_MED17_Hybrid
 SG_ BEM_P_Generator : 16|8@1+ (50,0) [0|12750] "W"  Motor_EDC17_Pirol
 SG_ BEM_n_LLA : 24|2@1+ (1,0) [0|3] ""  Motor_EDC17_Pirol
 SG_ BEM_01_Abschaltstufen : 26|3@1+ (1,0) [0|7] "" Vector__XXX
 SG_ BEM_Anf_KL : 29|1@1+ (1,0) [0|1] ""  Motor_EDC17_Pirol,Motor_MED17_Hybrid
 SG_ BEM_StartStopp_Info : 30|2@1+ (1,0) [0|3] ""  Motor_EDC17_Pirol,Motor_MED17_Hybrid

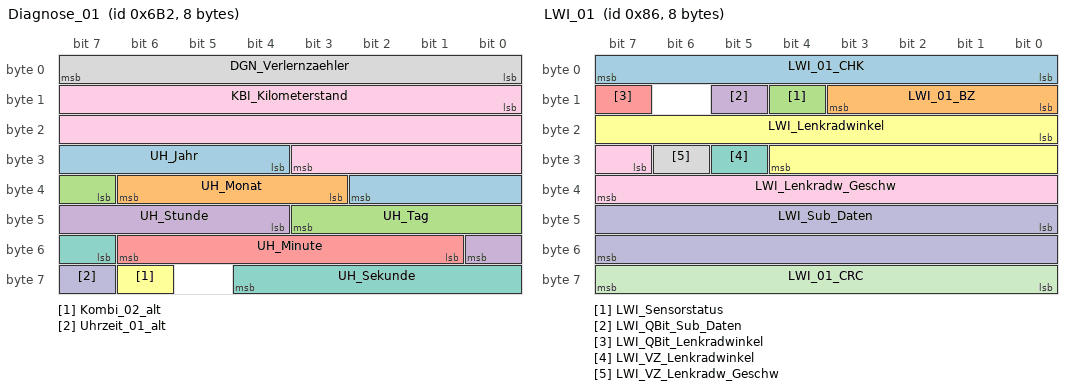
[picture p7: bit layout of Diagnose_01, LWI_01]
BO_ 1714 Diagnose_01: 8 GW_Applikation_Derivate
 SG_ UH_Jahr : 28|7@1+ (1,2000) [2000|2127] "Jahr"  Ladegeraet_PAG_PF,Motor_EDC17_Pirol,PSM_Ant_Derivate,Waehlhebel,Motor_MED17_Hybrid,LEH_Hybrid,Getriebe_Derivate,BMS_Hybrid,Airbag
 SG_ UH_Monat : 35|4@1+ (1,0) [1|12] "Monat"  Ladegeraet_PAG_PF,Motor_EDC17_Pirol,PSM_Ant_Derivate,Waehlhebel,Getriebe_Derivate,Motor_MED17_Hybrid,LEH_Hybrid,BMS_Hybrid,Airbag
 SG_ UH_Tag : 39|5@1+ (1,0) [1|31] "Tag"  Ladegeraet_PAG_PF,Motor_EDC17_Pirol,PSM_Ant_Derivate,Waehlhebel,Getriebe_Derivate,Motor_MED17_Hybrid,LEH_Hybrid,BMS_Hybrid,Airbag
 SG_ UH_Stunde : 44|5@1+ (1,0) [0|23] "h"  Ladegeraet_PAG_PF,Motor_EDC17_Pirol,PSM_Ant_Derivate,Waehlhebel,Getriebe_Derivate,Motor_MED17_Hybrid,LEH_Hybrid,BMS_Hybrid,Airbag
 SG_ UH_Minute : 49|6@1+ (1,0) [0|59] "min"  Ladegeraet_PAG_PF,Motor_EDC17_Pirol,PSM_Ant_Derivate,Waehlhebel,Getriebe_Derivate,Motor_MED17_Hybrid,LEH_Hybrid,BMS_Hybrid,Airbag
 SG_ Kombi_02_alt : 62|1@1+ (1,0) [0|1] ""  Airbag,BMS_Hybrid,LEH_Hybrid,Waehlhebel
 SG_ UH_Sekunde : 55|6@1+ (1,0) [0|59] "s"  Ladegeraet_PAG_PF,Motor_EDC17_Pirol,PSM_Ant_Derivate,Waehlhebel,Getriebe_Derivate,Motor_MED17_Hybrid,LEH_Hybrid,BMS_Hybrid,Airbag
 SG_ DGN_Verlernzaehler : 0|8@1+ (1,0) [0|254] ""  Ladegeraet_PAG_PF,Waehlhebel,LEH_Hybrid,BMS_Hybrid,Airbag
 SG_ KBI_Kilometerstand : 8|20@1+ (1,0) [0|1048573] "km"  Ladegeraet_PAG_PF,Motor_EDC17_Pirol,PSM_Ant_Derivate,Waehlhebel,Motor_MED17_Hybrid,LEH_Hybrid,BMS_Hybrid,Getriebe_Derivate,Airbag
 SG_ Uhrzeit_01_alt : 63|1@1+ (1,0) [0|1] ""  PSM_Ant_Derivate,Airbag,BMS_Hybrid,LEH_Hybrid,Waehlhebel,Ladegeraet_PAG_PF

BO_ 1313 STH_01: 8 GW_Routing_Derivate
 SG_ STH_Funk_ein : 0|1@1+ (1,0) [0|1] "" Vector__XXX
 SG_ STH_Funk_aus : 1|1@1+ (1,0) [0|1] "" Vector__XXX
 SG_ STH_Zusatzheizung : 2|1@1+ (1,0) [0|1] "" Vector__XXX
 SG_ STH_LED : 3|1@1+ (1,0) [0|1] ""  Motor_EDC17_Pirol
 SG_ STH_Pumpe_ein : 4|1@1+ (1,0) [0|1] "" Vector__XXX
 SG_ STH_Geblaese : 5|1@1+ (1,0) [0|1] "" Vector__XXX
 SG_ STH_EKP_Anst : 6|1@1+ (1,0) [0|1] ""  Motor_EDC17_Pirol
 SG_ STH_Ventiloeffnungszeit : 8|6@1+ (1,0) [0|63] "min" Vector__XXX
 SG_ STH_Waermeeintrag : 16|6@1+ (1,0) [0|63] "" Vector__XXX
 SG_ STH_KVS : 24|13@1+ (1,0) [0|8191] "ml" Vector__XXX
 SG_ STH_Fehlerstatus : 37|3@1+ (1,0) [0|7] "" Vector__XXX
 SG_ STH_Heizleistung : 40|8@1+ (1,0) [0|255] "" Vector__XXX
 SG_ STH_Wassertemp : 48|8@1+ (0.75,-40) [-40|142.5] "°C" Vector__XXX
 SG_ STH_Motorvorwaermung : 59|1@1+ (1,0) [0|1] ""  Motor_EDC17_Pirol
 SG_ STH_Servicemode : 60|1@1+ (1,0) [0|1] "" Vector__XXX
 SG_ STH_war_aktiv : 61|1@1+ (1,0) [0|1] ""  Motor_EDC17_Pirol
 SG_ STH_KVS_Ueberlauf : 62|1@1+ (1,0) [0|1] "" Vector__XXX
 SG_ STH_Start_folgt : 7|1@1+ (1,0) [0|1] "" Vector__XXX
 SG_ STH_KD_Fehler : 63|1@1+ (1,0) [0|1] "" Vector__XXX

BO_ 134 LWI_01: 8 GW_Routing_Derivate
 SG_ LWI_01_CHK : 0|8@1+ (1,0) [0|255] ""  Motor_EDC17_Pirol,Motor_MED17_Hybrid
 SG_ LWI_01_BZ : 8|4@1+ (1,0) [0|15] ""  Motor_EDC17_Pirol,Motor_MED17_Hybrid
 SG_ LWI_Sensorstatus : 12|1@1+ (1,0) [0|1] ""  Motor_EDC17_Pirol,Motor_MED17_Hybrid
 SG_ LWI_QBit_Sub_Daten : 13|1@1+ (1,0) [0|1] "" Vector__XXX
 SG_ LWI_QBit_Lenkradwinkel : 15|1@1+ (1,0) [0|1] ""  Motor_EDC17_Pirol,Motor_MED17_Hybrid
 SG_ LWI_Lenkradwinkel : 16|13@1+ (0.1,0) [0|818.8] "Grad"  Motor_EDC17_Pirol,Motor_MED17_Hybrid
 SG_ LWI_VZ_Lenkradwinkel : 29|1@1+ (1,0) [0|1] ""  Motor_EDC17_Pirol,Motor_MED17_Hybrid
 SG_ LWI_VZ_Lenkradw_Geschw : 30|1@1+ (1,0) [0|1] "" Vector__XXX
 SG_ LWI_Lenkradw_Geschw : 31|9@1+ (5,0) [0|2555] "Grad/s" Vector__XXX
 SG_ LWI_Sub_Daten : 40|16@1+ (1,0) [0|65535] "" Vector__XXX
 SG_ LWI_01_CRC : 56|8@1+ (1,0) [0|255] "" Vector__XXX

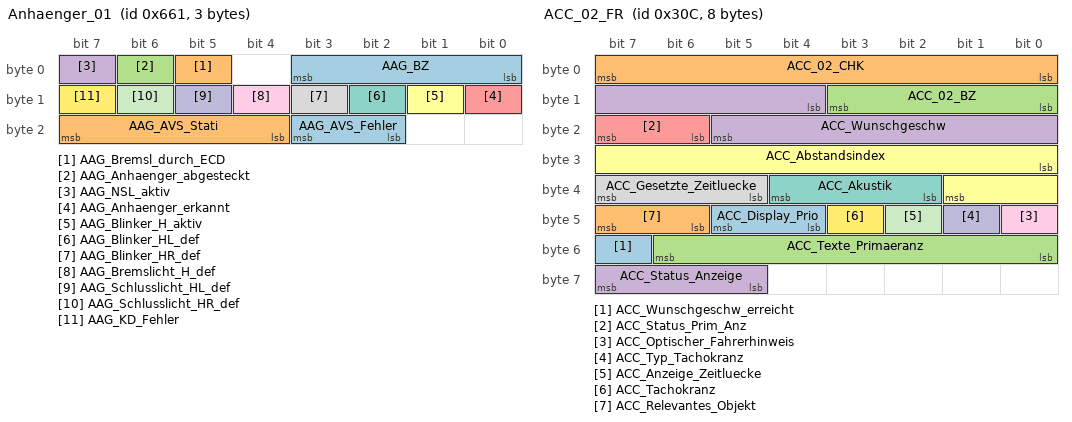
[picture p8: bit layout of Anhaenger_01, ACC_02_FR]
BO_ 1633 Anhaenger_01: 3 GW_Routing_Derivate
 SG_ AAG_BZ : 0|4@1+ (1,0) [0|15] ""  Motor_EDC17_Pirol,Motor_MED17_Hybrid
 SG_ AAG_Bremsl_durch_ECD : 5|1@1+ (1,0) [0|1] ""  Motor_EDC17_Pirol,Motor_MED17_Hybrid
 SG_ AAG_Anhaenger_abgesteckt : 6|1@1+ (1,0) [0|1] "" Vector__XXX
 SG_ AAG_NSL_aktiv : 7|1@1+ (1,0) [0|1] "" Vector__XXX
 SG_ AAG_Anhaenger_erkannt : 8|1@1+ (1,0) [0|1] ""  Motor_EDC17_Pirol,Motor_MED17_Hybrid
 SG_ AAG_Blinker_H_aktiv : 9|1@1+ (1,0) [0|1] "" Vector__XXX
 SG_ AAG_Blinker_HL_def : 10|1@1+ (1,0) [0|1] "" Vector__XXX
 SG_ AAG_Blinker_HR_def : 11|1@1+ (1,0) [0|1] "" Vector__XXX
 SG_ AAG_Bremslicht_H_def : 12|1@1+ (1,0) [0|1] ""  Motor_EDC17_Pirol,Motor_MED17_Hybrid
 SG_ AAG_Schlusslicht_HL_def : 13|1@1+ (1,0) [0|1] "" Vector__XXX
 SG_ AAG_Schlusslicht_HR_def : 14|1@1+ (1,0) [0|1] "" Vector__XXX
 SG_ AAG_KD_Fehler : 15|1@1+ (1,0) [0|1] "" Vector__XXX
 SG_ AAG_AVS_Fehler : 18|2@1+ (1,0) [0|3] "" Vector__XXX
 SG_ AAG_AVS_Stati : 20|4@1+ (1,0) [0|15] "" Vector__XXX

BO_ 780 ACC_02_FR: 8 GW_Routing_Derivate
 SG_ ACC_Wunschgeschw_erreicht : 55|1@1+ (1,0) [0|1] "" Vector__XXX
 SG_ ACC_02_CHK : 0|8@1+ (1,0) [0|255] ""  Getriebe_Derivate
 SG_ ACC_02_BZ : 8|4@1+ (1,0) [0|15] ""  Getriebe_Derivate
 SG_ ACC_Wunschgeschw : 12|10@1+ (0.32,0) [0|326.72] "km/h"  Getriebe_Derivate
 SG_ ACC_Status_Prim_Anz : 22|2@1+ (1,0) [0|3] "" Vector__XXX
 SG_ ACC_Abstandsindex : 24|10@1+ (1,0) [1|1021] "" Vector__XXX
 SG_ ACC_Akustik : 34|3@1+ (1,0) [0|7] "" Vector__XXX
 SG_ ACC_Gesetzte_Zeitluecke : 37|3@1+ (1,0) [0|7] "" Vector__XXX
 SG_ ACC_Optischer_Fahrerhinweis : 40|1@1+ (1,0) [0|1] "" Vector__XXX
 SG_ ACC_Typ_Tachokranz : 41|1@1+ (1,0) [0|1] "" Vector__XXX
 SG_ ACC_Anzeige_Zeitluecke : 42|1@1+ (1,0) [0|1] "" Vector__XXX
 SG_ ACC_Tachokranz : 43|1@1+ (1,0) [0|1] "" Vector__XXX
 SG_ ACC_Display_Prio : 44|2@1+ (1,0) [0|3] "" Vector__XXX
 SG_ ACC_Relevantes_Objekt : 46|2@1+ (1,0) [0|3] "" Vector__XXX
 SG_ ACC_Texte_Primaeranz : 48|7@1+ (1,0) [0|127] "" Vector__XXX
 SG_ ACC_Status_Anzeige : 61|3@1+ (1,0) [0|7] "" Vector__XXX

BO_ 1743 NMH_EM: 7 LEH_Hybrid
 SG_ NMH_EM_keine_HV_Entl : 19|1@1+ (1,0) [0|1] "" Vector__XXX
 SG_ NMH_EM_Start_1 : 0|1@1+ (1,0) [0|1] ""  Getriebe_Derivate,BMS_Hybrid,Motor_MED17_Hybrid,Ladegeraet_PAG_PF
 SG_ NMH_EM_Start_2 : 1|1@1+ (1,0) [0|1] "" Vector__XXX
 SG_ NMH_EM_Normal_Mode_1 : 2|1@1+ (1,0) [0|1] "" Vector__XXX
 SG_ NMH_EM_Normal_Mode_2 : 3|1@1+ (1,0) [0|1] "" Vector__XXX
 SG_ NMH_EM_Car_WakeUp : 6|1@1+ (1,0) [0|1] "" Vector__XXX
 SG_ NMH_EM_Per_WakeUp : 8|5@1+ (1,0) [0|31] "" Vector__XXX
 SG_ NMH_EM_Fkt_WakeUp : 13|3@1+ (1,0) [0|7] "" Vector__XXX
 SG_ NMH_EM_Klemme_15 : 16|1@1+ (1,0) [0|1] "" Vector__XXX
 SG_ NMH_EM_Diagnose : 17|1@1+ (1,0) [0|1] "" Vector__XXX
 SG_ NMH_EM_MindestAktivZeit : 18|1@1+ (1,0) [0|1] "" Vector__XXX
 SG_ NMH_EM_NL_Datem_EEPROM : 24|1@1+ (1,0) [0|1] "" Vector__XXX
 SG_ NMH_EM_Signalfehler : 32|1@1+ (1,0) [0|1] "" Vector__XXX
 SG_ NMH_EM_TimeOut_Fehler : 33|1@1+ (1,0) [0|1] "" Vector__XXX
 SG_ NMH_EM_CAN_Diag_deaktiv : 34|1@1+ (1,0) [0|1] "" Vector__XXX
 SG_ NMH_EM_KompSchutz : 35|1@1+ (1,0) [0|1] "" Vector__XXX
 SG_ NMH_EM_Mute_Mode : 36|1@1+ (1,0) [0|1] "" Vector__XXX
 SG_ NMH_EM_Transport_Mode : 37|1@1+ (1,0) [0|1] "" Vector__XXX
 SG_ NMH_EM_Abschaltstufe_aktiv : 38|1@1+ (1,0) [0|1] "" Vector__XXX
 SG_ NMH_EM_Busfehler : 39|1@1+ (1,0) [0|1] "" Vector__XXX
 SG_ NMH_EM_Lokalaktiv : 48|1@1+ (1,0) [0|1] "" Vector__XXX
 SG_ NMH_EM_Subsystemaktiv : 49|1@1+ (1,0) [0|1] "" Vector__XXX

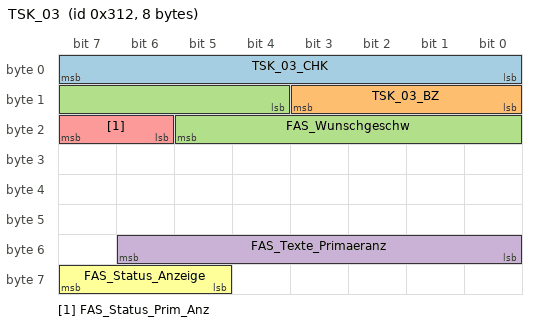
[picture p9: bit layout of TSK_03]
BO_ 786 TSK_03: 8 Motor_MED17_Hybrid
 SG_ TSK_03_CHK : 0|8@1+ (1,0) [0|255] ""  GW_Routing_Derivate,Getriebe_Derivate
 SG_ TSK_03_BZ : 8|4@1+ (1,0) [0|15] ""  GW_Routing_Derivate,Getriebe_Derivate
 SG_ FAS_Wunschgeschw : 12|10@1+ (0.32,0) [0|326.72] "Unit_KiloMeterPerHour"  GW_Routing_Derivate,Getriebe_Derivate
 SG_ FAS_Texte_Primaeranz : 48|7@1+ (1,0) [0|127] ""  GW_Routing_Derivate
 SG_ FAS_Status_Prim_Anz : 22|2@1+ (1,0) [0|3] ""  GW_Routing_Derivate
 SG_ FAS_Status_Anzeige : 61|3@1+ (1,0) [0|7] ""  GW_Routing_Derivate

BO_ 16 WFS_MSG1_IMS: 8 Motor_MED17_Hybrid
 SG_ WFS_MSG1_IMS : 0|64@1+ (1,0) [0|1.84467440737096E+019] ""  GW_Routing_Derivate

BO_ 17 WFS_IMS_MSG1: 8 GW_Routing_Derivate
 SG_ WFS_IMS_MSG1 : 0|64@1+ (1,0) [0|1.84467440737096E+019] ""  Motor_EDC17_Pirol,Motor_MED17_Hybrid

BO_TX_BU_ 933 : Motor_EDC17_Pirol,Motor_MED17_Hybrid;
BO_TX_BU_ 1729 : Motor_EDC17_Pirol,Motor_MED17_Hybrid;
BO_TX_BU_ 913 : Motor_EDC17_Pirol,Motor_MED17_Hybrid;
BO_TX_BU_ 270 : Motor_EDC17_Pirol,Motor_MED17_Hybrid;
BO_TX_BU_ 273 : Motor_EDC17_Pirol,Motor_MED17_Hybrid;
BO_TX_BU_ 1602 : Motor_EDC17_Pirol,Motor_MED17_Hybrid;
BO_TX_BU_ 786 : Motor_EDC17_Pirol,Motor_MED17_Hybrid;
BO_TX_BU_ 16 : Motor_EDC17_Pirol,Motor_MED17_Hybrid;
CM_ BO_ 157 "Motor - Getriebe - Schnittstelle auf CAN-Antrieb (PL72H)";
CM_ SG_ 157 MO_HYB_EMode_Info "Hybrid-Mode der Motorsteuerung zur Beeinflussung der Schaltkennfelder im Getriebe. Nicht-Hybridfahrzeuge senden den Initwert.
Signal wird nur von Porsche genutzt.";
CM_ SG_ 157 Motor_Hybrid_01_CHK "Berechnung siehe Lastenheft 'Kommunikationsabsicherung für FlexRay und CAN'
Endwerte siehe 'Kommunikationsabsicherung für FlexRay und CAN / Anhang C: Tabelle S-PDU Kennungen'


";
CM_ SG_ 157 Motor_Hybrid_01_BZ "überlaufender 4bit Botschaftszaehler; wird in jeder Sendebotschaft inkrementiert";
CM_ SG_ 157 MO_HYB_IstStatusK0 "Status 'offen' muss eine voll geöffnete Kupplung sicherstellen.";
CM_ SG_ 157 MO_HYB_max_ind_VM_Mom "inneres maximal mögliches VM-Moment bei einer Drehzahl (z.B. Rauchbegrenzung oder Fehlerfall).";
CM_ SG_ 157 MO_HYB_Startmodus "Hybridsteuerung zeigt an, auf welche Weise gestartet werden soll.";
CM_ SG_ 157 MO_HYB_Startmodus_PQ3x "Hybridsteuerung (MSG) zeigt an, auf welche Weise gestartet werden soll. (Nur PQ3x Hybrid)";
CM_ SG_ 157 MO_HYB_Stoppmodus "Hybridsteuerung zeigt an, auf welche Weise gestoppt werden soll.";
CM_ SG_ 157 MO_HYB_VM_Mom_oE "Verbrenner-Fahrmoment abzüglich Verbrenner-Verlustmoment. Vorzeichenbehaftet. Für Benutzung in Getriebe-Schaltstrategie";
CM_ SG_ 157 MO_HYB_VM_aktiv "0 = VMotor wird nicht aktiv gehalten (nVM < n_min und keine LL-Regelung aktiv)
1 = VMotor aktiv (ab der ersten Einspritzung; gilt auch für Schubbetrieb, wenn VMotor spätestens durch LLRegelung befeuert würde)
Verwendet zur Bestimmung des Ist-Zustandes";
CM_ SG_ 157 MO_HYB_Schaltverhinderung "Schaltungen werden an den DZ-Grenzen (Nullgas-Schaltdrehzahl und Kickdown-Schaltdrehzahl) ausgeführt.";
CM_ SG_ 157 MO_HYB_Selektor_Momverlauf_EM "Selektor welche Größe des Momentenverlauf aktuell übertragen wird
000b = 0 :  keine Werte(GRA/ACC nicht aktiv)
001b = 1 : max. umsetzbares langfristiges Rekup.-Moment
010b = 2 : Knickdrehzahl d. langfr. Rekup-Kurve
011b = 3 : max. verfügbares langfr. ";
CM_ SG_ 157 MO_HYB_Momverlauf_Rek "Momentenverlaufs-information bei aktiver GRA/ACC
max. umsetzbares langfristiges Rekup.-Moment";
CM_ SG_ 157 MO_HYB_KnickDZ_Rek "Momentenverlaufs-information bei aktiver GRA/ACC
Knickdrehzahl d. langfr. Rekup-Kurve";
CM_ SG_ 157 MO_HYB_Momverlauf_EM "Momentenverlaufs-information bei aktiver GRA/ACC
max. umsetzbares langfristiges Rekup.-Moment";
CM_ SG_ 157 MO_HYB_KnickDZ_EM "Momentenverlaufs-information bei aktiver GRA/ACC
Knickdrehzahl d. langfr. pos. EM-Kurve";
CM_ BO_ 811 "Motor - Getriebe - Schnittstelle auf CAN-Antrieb (PL72H)";
CM_ SG_ 811 MO_FahrPr7_verfuegbar "Verfügbarkeitsanzeige des Fahrprogramm 7";
CM_ SG_ 811 MO_FahrPr6_verfuegbar "Verfügbarkeitsanzeige des Fahrprogramm 6";
CM_ SG_ 811 MO_FahrPr5_verfuegbar "Verfügbarkeitsanzeige des Fahrprogramm 5";
CM_ SG_ 811 MO_FahrPr4_verfuegbar "Verfügbarkeitsanzeige des Fahrprogramm 4";
CM_ SG_ 811 MO_FahrPr3_verfuegbar "Verfügbarkeitsanzeige des Fahrprogramm 3";
CM_ SG_ 811 MO_FahrPr2_verfuegbar "Verfügbarkeitsanzeige des Fahrprogramm 2";
CM_ SG_ 811 MO_FahrPr1_verfuegbar "Verfügbarkeitsanzeige des Fahrprogramm 1";
CM_ SG_ 811 MO_HYB_E_Faktor "Signed Nibble, verwendet vom GSG zur Interpolation zwischen VMKennfeld und dem Rekuperations-Grenzkennfeld (negative Werte des E-Faktors) bzw. dem Boost-Grenzkennfeld (positive Werte des E-Faktors).
0000 = VM-Kennfeld (keine Interpolation)
0001..0111 = ";
CM_ SG_ 811 MO_HYB_Drehzahl_VM "für OBD freeze frame";
CM_ SG_ 811 MO_HYB_LowSpeedModus "MSG legt fest:
0 = klassisches Ausrollen/Anfahren mit N_mot >= N_Leerlauf_VM
1 = elektr. Ausrollen/Anfahren mit geschl. Triebstrang mit N_mot < N_Leerlauf_VM";
CM_ SG_ 933 MO_Overboost "Nur Turbo. Anzeige eines Overboostpfeils im Kombi während Overboostzustand der Ladedruckregelung.";
CM_ SG_ 933 Enrgfluss_State "Energiefluss zwischen den Achsen, Batterie, Elektromotor und Verbrennungsmotor";
CM_ SG_ 933 Ladezustand "Ladezustand der Batterie
";
CM_ SG_ 933 Energiefluss "Die %-Werte ergeben sich aus dem momentanen Moment der E-Maschine bezogen auf das im aktuellen Arbeitspunkt maximal mögliche Moment der E-Maschine (generatorisch = negativ / motorisch = positiv )
(Signal wird nur im Panamera Hybrid bedient)";
CM_ SG_ 933 Enrgrueckfluss "Frei laufender Zähler für die rückgewonnene Energie
(Signal wird nur im Panamera Hybrid bedient)";
CM_ SG_ 933 MO_Temp_MotRaum "Der Motor sendet dem BCM2 die Temperatur im Motorraum in °C.
(Signal wird nicht im Panamera bedient)";
CM_ SG_ 933 MO_Oel_Temp_Radsatz "Öltemperatur in PDK Radsatz
(Signal wird im Panamera nicht bedient)";
CM_ SG_ 933 MO_LED_Abgasklappe "Status der Abgasklappe
Signal zur Ansteuerung der Funktionsleuchte im Abgasklappentaster in der BKE";
CM_ SG_ 933 MO_Hoch_Anz_Nmax "Hochschaltempfehlung der Motorsteuerung vor Erreichen der Abstellerdrehzahl, gangabhängig. Hochschaltpfeil im Kombi, oder Schaltblitz, auch mit Automat.
Keine Befüllung des Signals im G1";
CM_ SG_ 933 MO_Hoch_Anz_Eco "Hochschaltempfehlung der Motorsteuerung für günstigen Kraftstoffverbrauch. Hochschaltpfeil im Kombi. Auch mit Automat.
Keine Befüllung des Signals im G1";
CM_ SG_ 933 MO_Fehler_MSpG "Wenn das Motorraumspülgebläse defekt ist, oder die Motorraumtemperatur zu hoch sendet die DME Info ans Kombiinstrument. Dieses gibt Textmeldung aus. Und blinkende Heissleuchte.
(Signal wird im Panamera nicht bedient)";
CM_ SG_ 933 MO_Anf_Abgasklappe "Motorsteuergeraet sendet Anforderung zur Aktivierung der Abgasklappe";
CM_ BO_ 1730 "200ms ab D4";
CM_ SG_ 1730 NMH_GE_N_Haltephase "Falls Wefgahrsperre Nachlauf vor CAN-Wakeup aktiv (Nur AL-Getriebe)";
CM_ SG_ 1730 NMH_GE_Start_1 "Zustand Start (<--Sleep)";
CM_ SG_ 1730 NMH_GE_Start_2 "Zustand Start (<--Prepare to Sleep)";
CM_ SG_ 1730 NMH_GE_Normal_Mode_1 "Zustand Normal Mode (<-- Start)";
CM_ SG_ 1730 NMH_GE_Normal_Mode_2 "Zustand Normal Mode (<-- Ready to Sleep)";
CM_ SG_ 1730 NMH_GE_Car_WakeUp "Car WakeUp (optional), wird vom Getriebe nicht gesendet";
CM_ SG_ 1730 NMH_GE_Per_WakeUp "Weckurasche Peripherie
";
CM_ SG_ 1730 NMH_GE_Fkt_WakeUp "Weckursache Funktion

";
CM_ SG_ 1730 NMH_GE_NM_aktiv_Klemme_15 "Klemme 15 ein (NM-Nachlaufursache, nicht 'Ready To Sleep')
";
CM_ SG_ 1730 NMH_GE_NM_aktiv_Diagnose "Diagnose bei Kl 15 aus (Nachlaufursache, nicht 'Ready To Sleep')";
CM_ SG_ 1730 NMH_GE_NM_aktiv_Start "Mindestaktivzeit Zustand 'Start' (Nachlaufursache, nicht 'Ready To Sleep')";
CM_ SG_ 1730 NMH_GE_kein_NL "kein lokaler / SG interner Nachlauf vor Wakeup";
CM_ SG_ 1730 NMH_GE_NL_Daten_EEPROM "EEPROM Datenspeicherung (lokaler / SG interner Nachlauf vor Wakeup)";
CM_ SG_ 1730 NMH_GE_NL_Drucksens "lokaler / SG interner Nachlauf: Wird gesetzt falls Druck auf einer der beiden Drucksensoren über applizierbarer Schwelle (bedeutet Motor läuft) vor CAN-Wakeup - nur VL Getriebe";
CM_ SG_ 1730 NMH_GE_NL_Abtrieb "lokaler / SG interner Nachlauf: Wird gesetzt falls Abtriebsdrehzahl größer applizierbarer Schwelle (bedeutet Fahrzeug bewegt sich) vor CAN-Wakeup - nicht DL Getriebe";
CM_ SG_ 1730 NMH_GE_NL_Waehlhebel "lokaler / SG interner Nachlauf: Wird gesetzt falls Wählhebel nicht in P oder N vor CAN-Wakeup - nur AL Getriebe";
CM_ SG_ 1730 NMH_GE_NL_Wegfahrsperre "lokaler / SG interner Nachlauf: Wird gesetzt falls Wegfahrsperre Nachlauf vor CAN-Wakeup aktiv - nur AL Getriebe";
CM_ SG_ 1730 NM_GE_Signalfehler "Bei der Speicherung eines CAN-Signalfehlers muss dieser mindestens einmal in der NM-Botschaft angezeigt werden.";
CM_ SG_ 1730 NMH_GE_TimeOut_Fehler "Aktiver Timeout Fehlerspeichereintrag  ";
CM_ SG_ 1730 NMH_GE_CAN_Diag_deaktiv "CAN Bus bezogene Eigendiagnose deaktiviert (Überspannung, Unterspannung, Hochlaufphase, ...) ";
CM_ SG_ 1730 NMH_GE_KompSchutz "Funktionseinschränung aufgrund Komponentenschutz aktiv";
CM_ SG_ 1730 NMH_GE_Mute_Mode "Funktionseinschränung aufgrund Mute Mode aktiv, nur VW";
CM_ SG_ 1730 NMH_GE_Transport_Mode "Funktionseinschränung aufgrund Transport Mode aktiv";
CM_ SG_ 1730 NMH_GE_Abschaltstufe_aktiv "Funktionsabschaltung wegen Abschaltschaltstufe";
CM_ SG_ 1730 NMH_GE_Eindraht_Fehler "Erkennung Eindrahtfehler";
CM_ SG_ 1730 NMH_GE_Lokalaktiv "Zeigt an ob das SG nach Klemme15 AUS und nach entsprechender MAX Aktivzeit noch aktiv war";
CM_ SG_ 1730 NMH_GE_Subsystemaktiv "Zeigt an ob ein Subsystem des SGs nach Klemme15 AUS und nach entsprechender MAX Aktivzeit noch aktiv war";
CM_ SG_ 1730 NMH_GSG_Subbusaktiv "Zeigt an ob der Subbus aktiv oder inaktiv ist";
CM_ BO_ 1729 "200ms ab D4";
CM_ SG_ 1729 NMH_MO_Start_1 "Zustand Start (<--Sleep)";
CM_ SG_ 1729 NMH_MO_Start_2 "Zustand Start (<--Prepare to Sleep)";
CM_ SG_ 1729 NMH_MO_Normal_Mode_1 "Zustand Normal Mode (<-- Start)";
CM_ SG_ 1729 NMH_MO_NM_aktiv_HV_Abschaltung "Hybrid-Manager deaktiviert alle Hochvolt-Verbraucher für stromloses Öffnen der Batterieschütze
(Nachlaufursache, nicht 'Ready To Sleep')";
CM_ SG_ 1729 NMH_MO_Normal_Mode_2 "Zustand Normal Mode (<-- Ready to Sleep)";
CM_ SG_ 1729 NMH_MO_Car_WakeUp "Car WakeUp (optional), wird vom Motor nicht gesendet";
CM_ SG_ 1729 NMH_MO_Per_WakeUp "Weckursache Peripherie
";
CM_ SG_ 1729 NMH_MO_Fkt_WakeUp "Weckursache Funktion
";
CM_ SG_ 1729 NMH_MO_NM_aktiv_Klemme_15 "Klemme 15 ein (NM-Nachlaufursache, nicht 'Ready To Sleep')";
CM_ SG_ 1729 NMH_MO_NM_aktiv_Diagnose "Diagnose bei Kl 15 aus (NM-Nachlaufursache, nicht 'Ready To Sleep')
";
CM_ SG_ 1729 NMH_MO_NM_aktiv_Start "Mindestaktivzeit Zustand 'Start' (NM-Nachlaufursache, nicht 'Ready To Sleep')";
CM_ SG_ 1729 NMH_MO_NM_aktiv_EKP_Vorlauf "EKP-Vorlauf (z. Zt. nicht bei Diesel)
(NM-Nachlaufursache, nicht 'Ready To Sleep')
";
CM_ SG_ 1729 NMH_MO_NM_aktiv_STH_Betrieb "STH-Betrieb (NM-Nachlaufursache, nicht 'Ready To Sleep')
";
CM_ SG_ 1729 NMH_MO_kein_NL "kein lokaler / SG interner Nachlauf vor Wakeup";
CM_ SG_ 1729 NMH_MO_NL_Kuehlerluefter "Kühlerlüfter Steuerung / Zusatzwasserpumpe (lokaler / SG interner Nachlauf vor Wakeup)";
CM_ SG_ 1729 NMH_MO_NL_Diagnose "Diagnosefunktionen (lokaler / SG interner Nachlauf vor Wakeup)";
CM_ SG_ 1729 NMH_MO_NL_WFS "Wegfahrsperre (lokaler / SG interner Nachlauf vor Wakeup)";
CM_ SG_ 1729 NMH_MO_NL_EEPROM "EEPROM Zugriffe RAM/ROM Tests (lokaler / SG interner Nachlauf vor Wakeup)";
CM_ SG_ 1729 NMH_MO_NL_Sonstige "Sonstige lokale / SG interne Nachläufe vor Wakeup";
CM_ SG_ 1729 NM_MO_Signalfehler "Bei der Speicherung eines CAN-Signalfehlers muss dieser mindestens einmal in der NM-Botschaft angezeigt werden.";
CM_ SG_ 1729 NMH_MO_TimeOut_Fehler "Aktiver Timeout Fehlerspeichereintrag  ";
CM_ SG_ 1729 NMH_MO_CAN_Diag_deaktiv "CAN Bus bezogene Eigendiagnose deaktiviert (Überspannung, Unterspannung, Hochlaufphase, ...) ";
CM_ SG_ 1729 NMH_MO_KompSchutz "Funktionseinschränung aufgrund Komponentenschutz aktiv";
CM_ SG_ 1729 NMH_MO_Mute_Mode "Funktionseinschränung aufgrund Mute Mode aktiv, nur VW";
CM_ SG_ 1729 NMH_MO_Transport_Mode "1 = Funktionseinschränung aufgrund Transport Mode aktiv";
CM_ SG_ 1729 NMH_MO_Abschaltstufe_aktiv "Funktionsabschaltung wegen Abschaltschaltstufe";
CM_ SG_ 1729 NMH_MO_Eindraht_Fehler "Erkennung Eindrahtfehler";
CM_ SG_ 1729 NMH_MO_Lokalaktiv "Zeigt an ob das SG nach Klemme15 AUS und nach entsprechender MAX Aktivzeit noch aktiv war";
CM_ SG_ 1729 NMH_MO_Subsystemaktiv "Zeigt an ob ein Subsystem des SGs nach Klemme15 AUS und nach entsprechender MAX Aktivzeit noch aktiv war";
CM_ SG_ 913 OBD_Calc_Load_Val "Calculated Load Value

Übertragung von Meßgrößen an das Getriebesteuergerät für Freeze Frame Abspeicherung bei Getriebefehlern

PID $04 Calculated Load Value; 0 .. 100% mit 100/255 % per bit
";
CM_ SG_ 913 OBD_Eng_Cool_Temp "Engine Coolant Temperature

Übertragung von Meßgrößen an das Getriebesteuergerät für Freeze Frame Abspeicherung bei Getriebefehlern

PID $05 Engine Coolant Temperature; -40 .. +215°C mit 1°C/bit und 40°C Offset";
CM_ SG_ 913 OBD_Abs_Throttle_Pos "Absolute Throttle Position

Übertragung von Meßgrößen an das Getriebesteuergerät für Freeze Frame Abspeicherung bei Getriebefehlern

PID $11 Absolute Throttle Position; 0 .. 100% mit 100/255 %/bit";
CM_ SG_ 913 OBD_Abs_Load_Val "Absolute Load Value

Übertragung von Meßgrößen an das Getriebesteuergerät für Freeze Frame Abspeicherung bei Getriebefehlern

PID $43 Absolute Load Value; 0 .. 25700%  mit 100/255 %/bit";
CM_ SG_ 913 OBD_Abs_Pedal_Pos "Absolute Pedal Position

Übertragung von Meßgrößen an das Getriebesteuergerät für Freeze Frame Abspeicherung bei Getriebefehlern

PID $49 Accelerator Pedal Position D; 0 .. 100% mit 100/255 %/bit";
CM_ SG_ 913 OBD_Warm_Up_Cycle "Mit dem Warm-Up-Cycle wird der zentrale Verlernzähler vom Gateway inkrementiert";
CM_ SG_ 913 OBD_Normed_Trip "Gesetzlich definierte 'Normed Condition' erfüllt, 'General Denominator' darf erhöht werden";
CM_ SG_ 913 OBD_Sperrung_IUMPR "Wenn der General Denominator auf Grund eines Fehlers in den Eingangsgrößen gesperrt wird, wird diese Information über Bussystem als OBD-Statusinformation OBD_Sperrung_IUMPR für andere OBD-Steuergeräte bereitgestellt. 

Das MSG (MIL-Master) setzt dieses ";
CM_ SG_ 913 OBD_Kaltstart_Denominator "Bestimmte Diagnosen werden nur unter Kaltstartbedingungen durchgeführt, der entsprechende Denominator bei IUMPR-pflichtigen Systemen wird anhand dieses vom MSG gebildeten Signals inkr...
(Signal wird nur im Panamera Hybrid bedient)";
CM_ SG_ 913 OBD_Minimum_Trip "Grundlage OBD-Gesetz CCR 1968.2 (d)(4.3) Denominator Specifications
Bildung des General Denominator 'Normed Trip':
¿ 600 sec. (kumulativ) Zeit nach Motorstart
¿ 300 sec. (kumulativ) mit Fahrzeuggeschwindigkeit > 25 mph (40 km/h)
¿ 30 sec. (kontinuierl";
CM_ SG_ 270 TSK_04_CHK "Berechnung siehe Lastenheft 'Kommunikationsabsicherung für FlexRay und CAN'
Endwerte siehe 'Kommunikationsabsicherung für FlexRay und CAN / Anhang C: Tabelle S-PDU Kennungen'";
CM_ SG_ 270 TSK_zul_Regelabw "Anforderung der zulässigen Regelabweichung vom Triebstrangkoordinator. Zulässiger Betrag der Abweichung zwischen angeforderter 'TSK_Sollbeschleunigung_Getriebe' und umzusetzender Sollbeschleunigung  im Getriebe. Im TSK wird, abhängig vom Arbeitspunkt die ";
CM_ SG_ 270 TSK_ax_Getriebe "Beschleunigungsanforderung des Beschleunigungsreglers (u. a. für ACC, GRA, Speed Limiter). Das Signal wird vom Getriebe benutzt, um die von GRA/ACC geforderte Sollbeschleunigung in dem verbrauchsgünstigsten Gang einzustellen.";
CM_ SG_ 270 TSK_Wunsch_Uebersetz "Bei ACC/GRA Betrieb bergab teilt der TSK dem Getriebe mit, dass eine Drehzahlerhöhung erwünscht ist, um mehr Schleppmoment und damit verbunden die nötige Verzögerung zu erzeugen, um die Geschwindigkeit konstant zu halten. 

Nutzung im VL: das Getriebe v";
CM_ SG_ 270 TSK_Freig_WU "Freigabe des TSK_Übersetzungswunsches bei ACC/GRA Betrieb bergab für die Verstellung nach kurz bzw. Rückschaltung im Getriebe.";
CM_ SG_ 270 TSK_Limiter_aktiv "Information, ob der Höchstgeschwindigkeitsbegrenzer aktiv ist. Beim gesetzten Bit kann das Getriebe hochschalten, unabhängig vom Fahrpedal";
CM_ SG_ 270 TSK_Status_GRA_ACC_02 "Signal redundant zu 'TSK_Status_GRA_ACC_01' in TSK_02, um für das Getriebe die einzulesenden Botschaften zu definieren.  

Die Zustände 0x1 und 0x2 werden vom Motor auch bei ACC gesetzt, wegen Umsetzung des Triebsstrangkoordinators im Motor. ";
CM_ SG_ 273 TSK_Fahrzeugmasse_02 "Neue Definition ab D4
Fahrzeugmasse in kg. Das Signal dient der Anpassung der Sollbeschleunigung vom ACC";
CM_ SG_ 273 TSK_05_CHK "Berechnung siehe Lastenheft 'Kommunikationsabsicherung für FlexRay und CAN'
Endwerte siehe 'Kommunikationsabsicherung für FlexRay und CAN / Anhang C: Tabelle S-PDU Kennungen'";
CM_ SG_ 273 TSK_Status_GRA_ACC_01 "Die Zustände 0x1 und 0x2 werden vom Motor auch bei ACC gesetzt, wegen Umsetzung des Triebsstrangkoordinators im Motor. ";
CM_ SG_ 273 TSK_Fahrzeugmasse "Fahrzeugmasse in kg. Das Signal dient der Anpassung der Sollbeschleunigung vom ACC
Init (entspricht phys. 500kg)
(Signal wird im Panamera nicht bedient)
";
CM_ SG_ 273 TSK_Steigung "Steigung in % Berg. Das Signal dient der Anpassung der Sollbeschleunigung vom ACC

Positive Werte > bergauf; 
Negative Werte < bergab

Fehler: Die Steigung aufgrund eines Fehlers (mit KD-Fehlereintrag) nicht mehr berechnet werden";
CM_ SG_ 273 TSK_Codierung_ACC "Information über den plausibilisierten Codierungszustand des Triebstrangskoordinators auf ACC.
Nutzung im ESP: Aktivierung der Timeout Überwachung auf ACC_01-Botschaft und Überwachung der zusätzlichen Drucksensoren bei gesetztem Bit.";
CM_ SG_ 273 TSK_Zwangszusch_ESP "Mit diesem Bit wird das ESP/ASR zwangsweise aktiviert. Bei gesetztem Bit ist ein ausgetastetes ESP (oder ASR) wieder aktiviert bzw. wird die Austastung verhindert.";
CM_ SG_ 273 TSK_Freig_Verzoeg_Anf "Freigabe der Verzögerungsanforderung der ACC oder ggf. GRA+ Funktion für ECD Regelung im ESP";
CM_ SG_ 273 TSK_Verzoeg_Anf_02 "Verzögerungsanforderung der ACC oder ggf. GRA+ Funktion für ECD Regelung im ESP";
CM_ SG_ 915 GE_Tipschaltempf_verfuegbar "Signalisierung, ob eine Hochschaltempfehlung im Tipmodus verfügbar ist oder nicht.";
CM_ SG_ 915 GE_Sollgang "Signalisiert den Sollgang, in den getippt werden soll. Abhängig vom Signal 'WBA_eing_Gang_02' und dem Sollgang kann dann das Kombi die Hochschaltempfehlung in Tip darstellen.";
CM_ SG_ 915 WBA_GE_Zusatzwarnungen "Prioritaetswarnungen Getriebe an Kombi
aktuell nur im Audi MLB genutzt";
CM_ SG_ 915 WBA_Effizienzmodus "Bei Handschaltern wird  das Fahrprogramm Effizienz signalisiert. 
Bei Automatikgetrieben wird das Fahrprogramm 'D' durch 'E' ersetzt.";
CM_ SG_ 915 WBA_Sollgang "Motor sendet den Sollgang in den der Fahrer schalten soll. Wird im Kombi als Hochschaltempfehlung hervorgehoben. Nur falls WBA_Senderkennung = 01 (MSG)
(Signal wird im Panamera nicht bedient)";
CM_ SG_ 915 WBA_Senderkennung "Die Botschaft WBA_02 wird vom Automatgetriebe gesendet, bei Handschaltern alternativ vom Motor. Das Getriebe stellt damit die Wählbereichsanzeige dar, der Motor beim Handschalter die Hochschaltaufforderung für den Fahrer im Kombi. Zur Unterscheidung des S";
CM_ SG_ 915 WBA_Lampe_Shift_Lock "Im Kombi wird Anzeige im Mitteldisplay geschaltet: 'Zum Einlegen einer Fahrstufe bitte Bremse betätigen' - nur falls WBA_Senderkennung = 00 (GSG)

";
CM_ SG_ 915 WBA_Blinken "Dieses Bit steuert die Fehlerlampe an oder wird zum Blinken der WBA-Anzeige genutzt - nur falls WBA_Senderkennung = 00 (GSG)
";
CM_ SG_ 915 WBA_Getriebevariante "Verwendete Getriebe-Variante im Fahrzeug, Kombi stellt entsprechende WBA dar (bspw. PRNDS). Nur falls WBA_Senderkennung = 00 (GSG).
";
CM_ SG_ 915 WBA_GE_Warnung "Prioritaetswarnungen Getriebe mit Shift by wire";
CM_ SG_ 915 WBA_Fahrstufe "Bei Automatgetrieben wird in diesem Signal die aktuelle Fahrstufe (=Wählhebelposition) ausgegeben. Nur falls WBA_Senderkennung = 00 (GSG):

Im Automatik-Betrieb:

0x0 = Zwischenstellung, keine Position  (Normaldarstellung aller Fahrstufen)
0x1 = Getr";
CM_ SG_ 915 WBA_Schaltempf_verfbar "Info, ob Schaltempfehlung im Fzg. verfügbar. Statischer Wert, ändert sich für ein Fzg nicht - nur falls WBA_Senderkennung = 01 (MSG)";
CM_ SG_ 915 WBA_eing_Gang "Das Automatgetriebe gibt den aktuell eingelegten Gang aus. Nur falls WBA_Senderkennung = 00 (GSG)

0xB - 0xF = tbd.";
CM_ SG_ 915 WBA_Istgang "Wenn Motor die WBA-Botschaft sendet wird in diesem Signal der aktuelle Gang ausgegeben (= Istgang des Schaltgetriebes). Nur falls WBA_Senderkennung = 01 (MSG).
(Signal wird im Panamera nicht bedient)";
CM_ SG_ 915 WBA_GE_Texte "Fahrerhinweise für das Kombi";
CM_ SG_ 915 WBA_Schaltschema_Aktiv "Anforderung Getriebe zur Anzeige des Schaltschemas im Kombi";
CM_ SG_ 915 WH_Warnung "Warntexte vom Waehlhebel";
CM_ SG_ 915 WBA_02_CHK "Berechnung siehe Lastenheft 'Kommunikationsabsicherung für FlexRay und CAN'
Endwerte siehe 'Kommunikationsabsicherung für FlexRay und CAN / Anhang C: Tabelle S-PDU Kennungen'";
CM_ SG_ 1602 WIV_Verschleissindex "Bei Otto Verbrauch, bei Diesel Verschleiss";
CM_ SG_ 1602 WIV_Russindex "Nur für Diesel, Rußwert, bei Otto Wert = 0";
CM_ SG_ 1602 WIV_t_min "Minimales Wartungsintervall für WIV in Monaten";
CM_ SG_ 1602 WIV_t_max "Maximales Wartungsintervall für WIV in Monaten";
CM_ SG_ 1602 WIV_W_min "Minimales Wartungsintervall für WIV in km";
CM_ SG_ 1602 WIV_W_max "Maximales Wartungsintervall für WIV in km";
CM_ BO_ 1646 "Botschaft analog Konzernmatrix Audi/VW";
CM_ SG_ 1646 KL_STL_aktiv "Betriebsstatus Standlueftung";
CM_ SG_ 1646 KL_STH_Betriebsdauer "Signal aus B8: im D3 derzeit nur 15, 30, 45, 60 Min
";
CM_ SG_ 1646 KL_STH_Ansteuerung "Ansteuerung Standheizung";
CM_ SG_ 1646 KL_STH_aktiv "Standheizung aktiv";
CM_ SG_ 1646 KL_Sonnenintensitaet "Sonnenintensitaet Klimaanlage";
CM_ SG_ 1646 KL_Magnetventil "Wasserventil zum Waermetauscher geoeffnet/geschlossen";
CM_ SG_ 1646 KL_Innen_Temp "Innentemperatur
";
CM_ SG_ 1646 KL_AussenTemp_WK "Aussentemperatur";
CM_ SG_ 1646 KL_MSG_valid "Signal zeigt an, ob alle Daten in der Botschaft gültig und plausibilisiert sind";
CM_ SG_ 1646 KL_Solarluefter_aktiv "Betriebsstatus Solarluefter";
CM_ BO_ 1636 "Botschaft analog Konzernmatrix Audi/VW";
CM_ SG_ 1636 KL_I_Geblaese "Stromaufnahme Gebläse";
CM_ SG_ 1636 KL_Beschlagsgefahr "Beschlagsgefahr auf der Frontscheibe im Bereich des Spiegelfusses. Dient zur präventiven Ansteuerung der  Kamera-Scheibenheizung, um Kamera-Blindheit zu vermeiden
PHEV: volle Leistungsfreigabe HV Heizer und HV EKK bei Scheibenbeschlag ";
CM_ SG_ 1636 KL_Umluftklappe_Status "Status Umluftklappe

";
CM_ SG_ 1636 KL_HSH_Taktung "Status Heckscheibenheizung
alter Signalname in Matrix 3.0 vor Angleichung an Konzernmatrix VW/Audi:
KL_St_HsHzg";
CM_ SG_ 1636 KL_Zuheizer_Freigabe "Freigabe Zuheizer";
CM_ SG_ 1636 KL_Geblaese_Status "Status Geblaese
Hinweis: Zur Matrix 5 gibt es eine abgestimmte Änderung der Wertetabelle (von Stufen nach prozentual) sowie der Signallänge (3 Bit --> 4 Bit)";
CM_ BO_ 959 "Botschaft analog Konzernmatrix Audi/VW";
CM_ SG_ 959 KL_Comp_rev_rq "Requested compressor revolution
over 8600 rpm = compressor stop";
CM_ SG_ 959 KL_Comp_enable "Enable to start for compressor
After 1 second when High-voltage becomes available, turn on '1'";
CM_ SG_ 959 KL_Vorwarn_Komp_ein "Vorwarnung Kompressor ein; 140ms vorher; Information für Motor zum Aufbau Momentenreserve";
CM_ SG_ 959 KL_Zustand "Betrieb Klimaanlage
";
CM_ SG_ 959 KL_4_Zonen "Vorhalt für D4: Information, ob 4-Zonen-Klimaanlage verbaut
Gilt nicht für PAG Panamera. Wird konstant mit '0' gesendet.

";
CM_ SG_ 959 KL_Thermomanagement "Stufen des Thermomanagements";
CM_ SG_ 959 KL_Vorwarn_HHS_ein "Vorwarnung Heckscheibenheizung ein; Information für Motor zum Aufbau Momentenreserve";
CM_ SG_ 959 KL_Vorwarn_HFS_ein "Vorwarnung Frontscheibenheizung ein (Info für Motor zum Aufbau Momentenreserve), aktuell keine HFS für B8 geplant
";
CM_ SG_ 959 KL_StartStopp_Info "Start/Stop-Info, Veto";
CM_ SG_ 959 KL_KD_Fehler "Status Kundendienstfehlerspeichereinträge";
CM_ SG_ 959 KL_Handshake_BEM "Handshake Klima / BEM (Heizleistungsänderung)";
CM_ SG_ 959 KL_Drehz_Anh "Anhebung der Leerlaufdrehzahl
alter Signalname in Matrix 3.0 vor Angleichung an Konzernmatrix VW/Audi:
KL_N_Anheb
";
CM_ SG_ 959 KL_Anf_KL "Ansteuerung Kuehlerluefter";
CM_ SG_ 959 KL_Last_Kompr "Kompressorlast
alter Signalname in Matrix 3.0 vor Angleichung an Konzernmatrix VW/Audi:
KL_Komp_Last";
CM_ BO_ 2041 "Diagnosebotschaft Response zwischen Airbag SG und Entsorgungsgerät (Tool).";
CM_ SG_ 2041 Response_Airbag_Deployment "Response_Airbag_Deployment";
CM_ BO_ 2033 "Diagnosebotschaft Request zwischen Entsorgungsgerät (Tool) und Airbag SG.";
CM_ SG_ 2033 Request_Airbag_Deployment "Request_Airbag_Deployment";
CM_ SG_ 1413 GW_KD_Fehler "Status Kundendienstfehlerspeichereinträge";
CM_ SG_ 1413 SI_QRS_Mode "Quickruhestrom
(wird vom GW nur im G1 Hybrid / Pirol bedient)";
CM_ SG_ 1413 SI_NWDF_gueltig "Gültigkeitsbit für Netzwerkdiagnosefreigabe-Signal
(Signal wird im Panamera nicht bedient)";
CM_ SG_ 1413 SI_NWDF "Netzwerk-Diagnose Freigebe zur zentralen Aktivierung der Netzwerkdiagnose.
(Signal wird im Panamera nicht bedient)";
CM_ SG_ 1413 SI_Diagnose_Aktiv "Gibt an ob Diagnose-Botschaften empfangen werden und somit eine Diagnose aktiv ist
(Signal wir im Panamera nicht bedient)";
CM_ SG_ 1413 SI_Fahrwerk_Sleep "CAN Fahrwerk schläft (Status des NM)";
CM_ SG_ 1413 SI_CAN_Crash_Sleep "CAN Crash-Gefahren schläft (Status des NM)";
CM_ SG_ 1413 SI_CAN_Antrieb_Sleep "CAN Antrieb schläft (Status des NM)";
CM_ SG_ 1413 SI_CAN_MMI_Sleep "CAN MMI schläft (Status des NM)";
CM_ SG_ 1413 SI_CAN_Komfort_Sleep "CAN Komfort schläft (Status des NM)";
CM_ SG_ 1413 SI_T_Mode "Transportmodus";
CM_ BO_ 480 "CCP in Serie mit 11Bit - Empfangskanal";
CM_ SG_ 901 CHA_01_CHK "Berechnung siehe Lastenheft 'Kommunikationsabsicherung für FlexRay und CAN'
Endwerte siehe 'Kommunikationsabsicherung für FlexRay und CAN / Anhang C: Tabelle S-PDU Kennungen'";
CM_ SG_ 901 CHA_01_BZ "Botschaftszähler konstant zu senden mit 0x00
Die Auswertung dieses BZ der Botschaft Charisma_01 ist durch den Empfänger nicht zulässig.";
CM_ SG_ 901 CHA_Systemstatus "Konstant zu senden mit 0x00 für in Ordnung";
CM_ SG_ 901 CHA_Ziel_FahrPr_MO "Anforderung Ziel-Fahrprogramm Motor

Änderung der Beschriftung des 'Audi drive select'
   alt: 'SPORT'           ->     neu: 'DYNAMIC'
   alt: 'DYNAMIC'       ->     neu: 'AUTO'
";
CM_ SG_ 901 CHA_Ziel_FahrPr_GE "Anforderung Ziel-Fahrprogramm Getriebe

Änderung der Beschriftung des 'Audi drive select'
   alt: 'SPORT'           ->     neu: 'DYNAMIC'
   alt: 'DYNAMIC'       ->     neu: 'AUTO'";
CM_ SG_ 901 CHA_Ziel_FahrPr_ST "Anforderung Ziel-Fahrprogramm

Änderung der Beschriftung des 'Audi drive select'
   alt: 'SPORT'           ->     neu: 'DYNAMIC'
   alt: 'DYNAMIC'       ->     neu: 'AUTO'";
CM_ SG_ 901 CHA_Ziel_FahrPr_SCU "Anforderung Ziel-Fahrprogramm SCU

Änderung der Beschriftung des 'Audi drive select'
   alt: 'SPORT'           ->     neu: 'DYNAMIC'
   alt: 'DYNAMIC'       ->     neu: 'AUTO'";
CM_ SG_ 901 CHA_Ziel_FahrPr_DR "Anforderung Ziel-Fahrprogramm Dämpfer

Änderung der Beschriftung des 'Audi drive select'
   alt: 'SPORT'           ->     neu: 'DYNAMIC'
   alt: 'DYNAMIC'       ->     neu: 'AUTO'";
CM_ SG_ 901 CHA_Ziel_FahrPr_QS "Anforderung Ziel-Fahrprogramm Quattro Sport

Änderung der Beschriftung des 'Audi drive select'
   alt: 'SPORT'           ->     neu: 'DYNAMIC'
   alt: 'DYNAMIC'       ->     neu: 'AUTO'";
CM_ SG_ 901 CHA_Ziel_FahrPr_AFS "Anforderung Ziel-Fahrprogramm AFS

Änderung der Beschriftung des 'Audi drive select'
   alt: 'SPORT'           ->     neu: 'DYNAMIC'
   alt: 'DYNAMIC'       ->     neu: 'AUTO'";
CM_ SG_ 901 CHA_Ziel_FahrPr_RGS "Anforderung Ziel-Fahrprogramm Reversibler Gurtstraffer

Änderung der Beschriftung des 'Audi drive select'
   alt: 'SPORT'           ->     neu: 'DYNAMIC'
   alt: 'DYNAMIC'       ->     neu: 'AUTO'";
CM_ SG_ 901 CHA_Ziel_FahrPr_EPS "Anforderung Ziel-Fahrprogramm Elekronische Lenkung

Änderung der Beschriftung des 'Audi drive select'
   alt: 'SPORT'           ->     neu: 'DYNAMIC'
   alt: 'DYNAMIC'       ->     neu: 'AUTO'";
CM_ SG_ 901 CHA_Ziel_FahrPr_ACC "Anforderung Ziel-Fahrprogramm ACC";
CM_ BO_ 24 "Wegfahrsperrenbotschaft";
CM_ SG_ 24 WFS_MSG4_IMS "Wegfahrsperre";
CM_ BO_ 25 "Wegfahrsperrenbotschaft";
CM_ SG_ 25 WFS_IMS_MSG4 "Wegfahrsperre (Vorhalt Hybrid)";
CM_ BO_ 1603 "Einheitenbotschaft";
CM_ SG_ 1603 KBI_Einheit_Verbrauch_elektr "Einheit elektrischer Verbrauch";
CM_ SG_ 1603 KBI_Einheit_Datum "Anzeigevariante des Datums";
CM_ SG_ 1603 KBI_Einheit_Streckenanz "Einheit der Streckenanzeige";
CM_ SG_ 1603 KBI_Einheit_Temp "Einheit der Temperatur";
CM_ SG_ 1603 KBI_Einheit_Uhrzeit "Anzeigevariante der Uhrzeit
";
CM_ SG_ 1603 KBI_Einheit_Sprache "Einheit Sprache";
CM_ SG_ 1603 KBI_Einheit_Volumen "Einheit des Volumens";
CM_ SG_ 1603 KBI_Einheit_Verbrauch "Einheit der Verbrauchs";
CM_ SG_ 1603 KBI_MFA_v_Einheit_02 "Einheit der Geschwindigkeit, die vom Fahrer im Car-Menü gewählt wurde. Veränderliche Grösse, im Gegensatz zur Einheit des Tachokranzes.
Redundant in der Einheiten_01 Botschaft definiert, um Konsistenz zur BAP-Festlegung zu haben.";
CM_ SG_ 1603 KBI_Einheit_Druck "Einheit des Druckes";
CM_ BO_ 267 "Botschaft vom Lenkstockschalter, enthält Information zur Bedienung der GRA und ACC, sowie MFL-Tasten zum Getriebe für TipTronic.
Unterschied zu Ursprungs-Botschaft: Signalpos. 28+29 (LS_Tip_Stufe_2, LS_GRA_ACC_2stufig)";
CM_ SG_ 267 MFL_Tip_Up "Tiptronic Tasten vom MFL für Getriebe
    0x0 = kein Tip_Up
    0x1 = Tip_Up";
CM_ SG_ 267 MFL_Tip_Down "Tiptronic Tasten vom MFL für Getriebe
    0x0 = kein Tip_Down
    0x1 = Tip_Down";
CM_ SG_ 267 LS_Verstellung_Zeitluecke "Verstellung der Zeitlücke für ACC

0x0 = Taste nicht betaetigt
0x1 = Dist -1
0x2 = Dist +1
0x3 = nicht belegt

DIST -1 = Zeitluecke um 1 Stufe kleiner
DIST +1 = Zeitluecke um 1 Stufe groeßer";
CM_ SG_ 267 LS_Typ_Hauptschalter "Typ Hauptschalter";
CM_ SG_ 267 LS_Tiptronic_Fehler "Tiptronic Fehler";
CM_ SG_ 267 LS_Tip_Wiederaufnahme "ACC : Tippschalter Wiederaufnahme";
CM_ SG_ 267 LS_Tip_Setzen "ACC : Tippschalter Set";
CM_ SG_ 267 LS_Tip_Runter "GRA : Tip Down 
ACC : Tip Down";
CM_ SG_ 267 LS_Tip_Hoch "GRA : Tip Up 
ACC : Tip Up";
CM_ SG_ 267 LS_Limiter "Limiter setzen";
CM_ SG_ 267 LS_Hauptschalter "Tempomat aktiviert/deaktiviert";
CM_ SG_ 267 LS_Fehler "0 = in Ordnung
1 = Fehler Bedienteil";
CM_ SG_ 267 LS_Abbrechen "GRA : aus mit speichern
ACC : Soft aus";
CM_ SG_ 267 LS_01_CHK "Bildung der Checksumme
Checksumme = Byte2 XOR Byte 3 ... XOR Byte n  XOR CHK-Endwert
Wobei 'CHK-Endwert' abhängig ist vom CAN-ID: CHK-Endwert = MSB XOR LSB
MSB: High-Byte des Identifiers der CAN-Botschaft LSB: Low-Byte des Identifiers der CAN-Botschaft";
CM_ SG_ 267 LS_01_BZ "4bit Botschaftszähler, wird in jeder Sendebotschaft inkrementiert";
CM_ SG_ 267 MFL_M_Taste "Gilt nicht für PAG Panamera.
Taster für Umschaltung Automatik/manuelles Schalten (Tiptronic)

";
CM_ SG_ 267 LS_Tip_Stufe_2 "Signal zeigt an, dass der zweistufige GRA/ACC-Hebel in der 2. Tip-Stufe betätigt wird. Das Signal wird nur gleichzeitig mit dem Signal LS_Tip_Hoch oder LS_Tip_Runter gesetzt, wobei die Bits LS_Tip_Hoch bzw. LS_Tip_Runter die Richtung der Hebelbetätigung a";
CM_ SG_ 267 LS_GRA_ACC_2stufig "Verbau-Information zum zweistufigen GRA/ACC-Hebel; 
Übergangslösung für MLB1, soll ab MQB durch ein Signal ersetzt werden, dass weitere Bedienteilvarianten (z.B. 4-Positions-Hebel) kennzeichnen kann.";
CM_ BO_ 260 "EPB-Botschaft (Status, Beschl., Pedalweg, etc.) wie Audi B8";
CM_ SG_ 260 EPB_Konsistenz_ACC "Signal wird im Panamera nicht unterstützt. Es wird konstant '1' (Fehler erkannt) gesendet.
Signalanforderung aus ColNF.";
CM_ SG_ 260 EPB_Anfahrwunsch_erkannt "Anfahrwunsch erkannt
Aktuell kein Empfänger. Vorhalt für E2.";
CM_ SG_ 260 EPB_Pedalweg_Kuppl "Signal entspricht Tastverhältnis des PWM. Gesamtweg Kupplungspedal 10% bis 90%, damit zu erwartende Werte 25 bis 225. 25 bei Kupplungspedal nicht getreten, 225 bei Kupplungspedal voll durchgetreten.
2% Toleranz wird im Wertebereich ermöglicht (8%-92%).
";
CM_ SG_ 260 EPB_Fehlerstatus "EPB Fehlerstatus";
CM_ SG_ 260 EPB_Schalterposition "Spiegelt die Schalterstellung wieder.

";
CM_ SG_ 260 EPB_QBit_Schalterpos "QBit für Signal 'EPB_Schalterposition'";
CM_ SG_ 260 EPB_Spannkraft "Erzeugte Spannkraft. Bezieht sich auf die Aktuatoren.

0x1F = Fehler
0x1E = Init";
CM_ SG_ 260 EPB_Status "Gibt den Zustand der EPB-Aktuatoren an.";
CM_ SG_ 260 EPB_KD_Fehler "Kundedienstfehler";
CM_ SG_ 260 EPB_01_CHK "Bildung der Checksumme
Checksumme = Byte2 XOR Byte 3 ... XOR Byte n  XOR CHK-Endwert
Wobei 'CHK-Endwert' abhängig ist vom CAN-ID: CHK-Endwert = MSB XOR LSB
MSB: High-Byte des Identifiers der CAN-Botschaft LSB: Low-Byte des Identifiers der CAN-Botschaft";
CM_ SG_ 260 EPB_01_BZ "Überlaufender Botschaftszähler zur Erkennung von fehlenden oder alten Botschaften.";
CM_ SG_ 260 EPB_QBit_Laengsbeschleunigung "Mitteilung z.Zt. für ACC, um unter bestimmten Umständen mitzuteilen, daß Längsbeschleunigung temporär ungültig ist. Bsp.Selbsttest Längsbeschleunigungssensor.";
CM_ SG_ 260 EPB_QBit_Pedalweg_Kuppl "QBit für Signal 'EPB_Pedalweg_Kuppl'";
CM_ SG_ 260 EPB_BCM2_Motor_Wakeup "EPB setzt dieses Bit, wenn EPB ein Nachwecken des ACAN fordert.
Die Wakeup-Ursache des CAR-Wakeup wird im NMH von den SG nicht ausgewertet,
weswegen die Car-Wakeup-Information in einer konventionellen Applikationsbotschaft zum BCM2 gesendet werden.";
CM_ SG_ 260 EPB_Freig_Verzoeg_Anf "Freigabe Verzögerungsanforderung";
CM_ SG_ 260 EPB_Verzoeg_Anf "Steuerungsanforderung an andere Systeme (z.B. ESP), um während der Fahrt, durch den Handbremsschalter ausgelöst, zu bremsen (ECD-Funktion)";
CM_ SG_ 260 EPB_Laengsbeschleunigung "Längsbeschleunigungssignal.
Achtung! Misst auch die Erdbeschleunigung (steht am Hang Wert != 0)

Entspricht bei kleinen Winkeln dem Neigungswinkelsignal (<30%).

0x00 = Init
0xFF = Fehler";
CM_ BO_ 64 "Airbagbotschaft (CrashInt, Front-, Heck-, Rollovercrash, Gurte)";
CM_ SG_ 64 AB_Deaktivierung_HV "Deaktivierung der HV-Teilnehmer im Hybrid nach Crash
(Signal wird im Panamera nicht bedient!)";
CM_ SG_ 64 AB_RGS_Anst "PreCrash-Ansteuerung reversibler Gurtstraffer (Aktivierung und Kraftniveau)
Gilt nicht fuer PAG Panamera.";
CM_ SG_ 64 AB_Texte_AKS "Textanzeige für pyrotechnische Auslösung der aktiven Kopfstütze (AKS).
Gilt nicht für PAG Panamera.";
CM_ SG_ 64 Airbag_01_CHK "Bildung der Checksumme
Checksumme = Byte2 XOR Byte 3 ... XOR Byte n  XOR CHK-Endwert
Wobei 'CHK-Endwert' abhängig ist vom CAN-ID: CHK-Endwert = MSB XOR LSB
MSB: High-Byte des Identifiers der CAN-Botschaft LSB: Low-Byte des Identifiers der CAN-Botschaft";
CM_ SG_ 64 Airbag_01_BZ "Botschaftszähler";
CM_ SG_ 64 AB_Front_Crash "Bit wird bei Überschreitung der Gurtstraffer-, US- und RdW-Schwelle gesetzt";
CM_ SG_ 64 AB_Heck_Crash "Heck-Crash";
CM_ SG_ 64 AB_SF_Crash "Z.Zt. nur in Verbindung mit Crash-Intensität >= 100b (Kraftstoffpumpenabschaltung) verwendet.";
CM_ SG_ 64 AB_SB_Crash "Z.Zt. nur in Verbindung mit Crash-Intensität >= 100b (Kraftstoffpumpenabschaltung) verwendet.";
CM_ SG_ 64 AB_Rollover_Crash "Rollover Crash";
CM_ SG_ 64 AB_Crash_Int "Crash-Intensität";
CM_ SG_ 64 AB_Lampe "Sicherheitswarnlampe im Kombi wird vom Airbag-SG angesteuert; Zustand der Lampe wird auf dem CAN-Bus ausgegeben (auch Blinkinformation).";
CM_ SG_ 64 AB_Deaktiviert "Airbag oder Gurtstraffer wurden per Anpassung deaktiviert: Aktualisierung erst nach Selbsttest
Bei Porsche konstant '0'";
CM_ SG_ 64 AB_VB_deaktiviert "Als Option vorgehalten, Beifahrerairbag wurden per Schlüsselschalter oder Insassenerkennung deaktiviert
Auswertung bei Porsche:
0x0: Airbag BF aktiv, PAO-Leuchte aus
0x1: Airbag BF deaktiviert, PAO-Leuchte ein";
CM_ SG_ 64 AB_Systemfehler "Ggf. wird Warnlampe dauernd eingeschaltet.";
CM_ SG_ 64 AB_Diagnose "Airbag in Diagnose";
CM_ SG_ 64 AB_Stellgliedtest "Information, ob Airbag im Stellgliedtest ist, um eine Notrufauflösung beim Stellgliedtest zu verhindern";
CM_ SG_ 64 AB_Erh_Auf_VB "Der Fahrer soll bei einem Statuswechsel des Beifahrerairbags (ausgelöst durch die Beifahrerinsassenerk. oder den Schlüsselschloßschalter) aufmerksam gemacht werden durch eine Anz. im Kombi. 
Wird bei Porsche nicht genutzt.Es wird konstant 0x3 gesendet.";
CM_ SG_ 64 AB_Gurtwarn_VF "Fahrer hat Gurt nicht gesteckt, Anzeige im Kombi";
CM_ SG_ 64 AB_Gurtwarn_VB "Beifahrer hat Gurt nicht gesteckt, Anzeige im Kombi";
CM_ SG_ 64 AB_Anzeige_Fussg "Anzeige für den Kunden, ob Reversierung der Motorhaube erfolgt ist";
CM_ SG_ 64 AB_PAO_Leuchte_Anf "Anforderung an die PAO-Leuchte in der Dachkonsole an/aus";
CM_ SG_ 64 AB_KD_Fehler "Status Kundendienstfehlerspeichereinträge
";
CM_ BO_ 1312 "Airbagbotschaft (Belegungserkennung)";
CM_ SG_ 1312 AB_Sitzpos_Sens_BF "Ausgabe Sitzposition Beifahrer";
CM_ SG_ 1312 AB_Sitzpos_Sens_FA "Ausgabe Sitzposition Fahrer";
CM_ SG_ 1312 AB_Gurtschloss_Reihe3_MI "Gurtschlossstatus 3. Reihe Mitte";
CM_ SG_ 1312 AB_Gurtschloss_Reihe3_FA "Gurtschlossstatus 3. Reihe Fahrerseite";
CM_ SG_ 1312 AB_Gurtschloss_Reihe3_BF "Gurtschlossstatus 3. Reihe Beifahrerseite";
CM_ SG_ 1312 AB_Gurtschloss_Reihe2_BF "Gurtschlossstatus 2. Reihe Beifahrerseite";
CM_ SG_ 1312 AB_Gurtschloss_Reihe2_MI "Gurtschlossstatus 2. Reihe Mitte";
CM_ SG_ 1312 AB_Gurtschloss_Reihe2_FA "Gurtschlossstatus 2. Reihe Fahrerseite";
CM_ SG_ 1312 AB_Gurtschloss_BF "Gurtschlossstatus Beifahrerseite";
CM_ SG_ 1312 AB_Gurtschloss_FA "Gurtschlosstatatus Fahrerseite";
CM_ SG_ 1312 AB_Belegung_VB "AB Belegung VB
Wird bei Porsche nicht genutzt.Es wird konstant 0x0 gesendet.";
CM_ BO_ 777 "Batterie Energie Management";
CM_ SG_ 777 BEM_Segel_Info "0: keine Anforderung 
(Segeln ist ohne Einschänkung erlaubt)
1: Mindestdrehzahl 1 
(Segeln ist mit Einschänkung erlaubt)
2: Mindestdrehzahl 2
(Segeln ist mit Einschänkung erlaubt)
3: Segelveto
(Segeln ist nicht  erlaubt)";
CM_ SG_ 777 BEM_01_CHK "Bildung der CHK:

XOR Byte2 XOR Byte 3 ... XOR Byte n  XOR CHK-Endwert  = CHK

Ab B8 ist CHK-Endwert abhängig vom CAN-ID: CHK-Endwert = MSB XOR LSB
MSB: High-Byte des Identifiers der CAN-Botschaft
LSB: Low-Byte des Identifiers der CAN-Botschaft";
CM_ SG_ 777 BEM_P_Generator "Es gilt: Signalspec BEM_P_Generator v1.0

Mechanische Generatorleistung dient dem Motorsteuergerät zur Berechnung der Motorlast; Genauigkeit ca. +/- (500W + 20% vom Messwert)";
CM_ SG_ 777 BEM_n_LLA "Es gilt: Signalspec BEM_n_LLA v1.0

Anforderung einer Leerlaufdrehzahlanhebung in drei Stufen. Die Höhe der jeweiligen LL-Drehzahlstufe ist im Motorsteuergerät appliziert.";
CM_ SG_ 777 BEM_01_Abschaltstufen "Signal inhaltlich identisch mit BEM_02_Abschaltstufen. Namentliche Umbenennung wegen Standard-SW im Gateway-BEM im B8 (Handling gleicher Signalnamen im Source-Code).";
CM_ SG_ 777 BEM_Anf_KL "Es gilt: Signalspec BEM_Anf_KL v1.1

Das BEM fordert über das MSG den Kühlerlüfter-Betrieb an; hierzu wird ein minimaler Leistungswert im MSG appliziert. 
Szenario: bei erkannter abgetrennten Batterie soll durch Ansteuerung des Kühlerlüfters das Energi";
CM_ SG_ 777 BEM_StartStopp_Info "Start/Stop-Info, Veto";
CM_ BO_ 1714 "Zentrale GW-Botschaft für Datum, Uhrzeit, etc.";
CM_ SG_ 1714 UH_Jahr "Jahr
Hinweis: keine Überwachung auf CAN-Signalfehler notwendig";
CM_ SG_ 1714 UH_Monat "Monat; Wertebereich 1-12, alle anderen Werte ungültig
Hinweis: Es ist ein CAN-Signalfehler 'Kombi' (nicht Gateway) einzutragen.";
CM_ SG_ 1714 UH_Tag "Monat; Wertebereich 1-31, alle anderen Werte ungültig
Hinweis: Es ist ein CAN-Signalfehler 'Kombi' (nicht Gateway) einzutragen.";
CM_ SG_ 1714 UH_Stunde "Stunde; Wertebereich 0-23, alle anderen Werte ungültig
Hinweis: Es ist ein CAN-Signalfehler 'Kombi' (nicht Gateway) einzutragen.";
CM_ SG_ 1714 UH_Minute "Minute; Wertebereich 0-59, alle anderen Werte ungültig
Hinweis: Es ist ein CAN-Signalfehler 'Kombi' (nicht Gateway) einzutragen.";
CM_ SG_ 1714 Kombi_02_alt "Veraltet-Bit für die Signale: KBI_Kilometerstand
Hinweis: bei gesetztem Bit ist ein CAN-Timeoutfehler 'Kombi' einzutragen.";
CM_ SG_ 1714 UH_Sekunde "Sekunde; Wertebereich 0-59, alle anderen Werte ungültig
Hinweis: Es ist ein CAN-Signalfehler 'Kombi' (nicht Gateway) einzutragen.";
CM_ SG_ 1714 DGN_Verlernzaehler "Binär, wrap around";
CM_ SG_ 1714 KBI_Kilometerstand "Fehler wird ausgegeben, falls Kilometerstand nicht restaurierbar
Hinweis. Bei Fehlerwert muss ein CAN-Signalfehler 'Kombi' eingetragen werden.";
CM_ SG_ 1714 Uhrzeit_01_alt "Veraltet-Bit wird vom GW nach einem Klemme 30-Reset gesetzt.
Über Uhrzeit_01-Botschaft vom Kombi wird im GW die Zeit neu gesetzt und das Veraltet-Bit zurückgenommen.
Hinweis: bei gesetztem Bit ist ein CAN-Timeoutfehler 'Kombi' einzutragen.
";
CM_ BO_ 1313 "Standheizung";
CM_ SG_ 1313 STH_Funk_ein "0x1 = Funkbefehl zum Einschalten erhalten";
CM_ SG_ 1313 STH_Funk_aus "0x1 = Funkbefehl zum Ausschalten erhalten";
CM_ SG_ 1313 STH_Zusatzheizung "Zusatzheizung";
CM_ SG_ 1313 STH_LED "Funktionslampe";
CM_ SG_ 1313 STH_Geblaese "0=kein Befehl an die Klimanlage; 1 = Befehl an die an Klimaanlage: Gebläse ein";
CM_ SG_ 1313 STH_EKP_Anst "STH sendet die Anforderung zur Ansteuerung der EKP an den Motor, um Kraftstoffbehälter der STH zu befüllen.";
CM_ SG_ 1313 STH_Ventiloeffnungszeit "Die Standheizung sendet an den Motor die Information darüber wie lange das Magnetventil die Wasserkreisläufe von 'klein' aus 'gross' geschaltet hat. ";
CM_ SG_ 1313 STH_Waermeeintrag "Signal enthält die Brenndauer in 1min-Schritten, über welche die Standheizung gelaufen ist";
CM_ SG_ 1313 STH_KVS "Kraftstoffverbrauch";
CM_ SG_ 1313 STH_Fehlerstatus "0 = kein Fehler;
1 = Batterie Low;
2 = Fuel Low;
3 = Hardware defekt;
4 = Heizgerät verriegelt:
5...7 = nicht definiert";
CM_ SG_ 1313 STH_Heizleistung "Heizleistung in %";
CM_ SG_ 1313 STH_Wassertemp "0xFE = Init
0xFF  = Fehler";
CM_ SG_ 1313 STH_Motorvorwaermung "Info an der Motor, dass der Aufheizvorgang mit Motorvorwärmung erfolgt ist

0x0 = keine Motorvorwärmung erfolgt
0x1 = Aufheizung mit Motorvorwärmung erfolgt";
CM_ SG_ 1313 STH_war_aktiv "Bit beeinhaltet die Info, dass die Standheizung während der letzten halbe Stunde aktiv war.

0x0 = war inaktiv
0x1 = Standheizung war letzte halbe Stunde aktiv";
CM_ SG_ 1313 STH_KVS_Ueberlauf "1 = Kraftstoffverbrauchssignal, mindestens ein Überlauf hat stattgefunden";
CM_ SG_ 1313 STH_Start_folgt "Thema Start/Stop: Im Stop-Modus muß das KBT einen Wiederstart anfordern, da ein STH-Start notwendig ist.";
CM_ BO_ 134 "Lenkwinkelsensor-Botschaft";
CM_ SG_ 134 LWI_01_CHK "Bildung der Checksumme
Checksumme = Byte2 XOR Byte 3 ... XOR Byte n  XOR CHK-Endwert
Wobei 'CHK-Endwert' abhängig ist vom CAN-ID: CHK-Endwert = MSB XOR LSB
MSB: High-Byte des Identifiers der CAN-Botschaft LSB: Low-Byte des Identifiers der CAN-Botschaft";
CM_ SG_ 134 LWI_Sensorstatus "0x0 = iO
0x1 = nicht kalibriert";
CM_ SG_ 134 LWI_QBit_Sub_Daten "0x0 = LWS-Subinfo 'real' (Lenkradwinkelinformation ADS-tauglich) 

0x1 = LWS-Subinfo 'simuliert' (Lenkradwinkelinformation nicht ADS-tauglich )

Im B8 gilt die Signalspezifikation: LAH 8K0953B";
CM_ SG_ 134 LWI_QBit_Lenkradwinkel "Ab B8 wird es möglich sein ungenaue Werte des Lenkradwinkels zu detektieren, und dem Empfänger mitzuteilen. Das QBit wird auch bei nicht abgeglichenem Lenkradwinkelsensor gesetzt

0x0 = gültiger Wert
0x1 = ausserhalb der Spezifikation";
CM_ SG_ 134 LWI_Lenkradwinkel "Wertebereich = +/- 800 Grad
Auflösung = 0,1 Grad
ACHTUNG: spezifizierte Interne Auflösung des Sensors beträgt aber nur Schrittweite 0,5 Grad!";
CM_ SG_ 134 LWI_VZ_Lenkradwinkel "Vorzeichen Lenkradwinkel gemäss DIN70000; 
Nullstellung = +0";
CM_ SG_ 134 LWI_VZ_Lenkradw_Geschw "Vorzeichen Lenkradwinkelgeschwindigkeit gemäss DIN70000; 

0x0 = positiv (links von der Nullstellung)
0x1 = negativ";
CM_ SG_ 134 LWI_Lenkradw_Geschw "Wertebereich = +/- 2500 Grad/s
Auflösung = 5 Grad/s

0x1FF = Fehler
0x1FE = Init

Im B8 gilt die Signalspezifikation: LAH 8K0953B ";
CM_ SG_ 134 LWI_Sub_Daten "Verschlüsseltes Datenpaket vom Sub-Rechner des LWS, Verwendung nur durch SCU und ESP_ADS
Verwendung gemäß 'Sicherheitsanforderungen an Empfängersteuergeräte'

Im B8 gilt die Signalspezifikation: LAH 8K0953B";
CM_ SG_ 134 LWI_01_CRC "CRC8 nach Polynom C2";
CM_ SG_ 1633 AAG_BZ "4bit-Botschaftszaehler, wird in jeder Sendebotschaft inkrementiert
";
CM_ SG_ 1633 AAG_Bremsl_durch_ECD "Bremslicht durch ECD aktiv";
CM_ SG_ 1633 AAG_Anhaenger_abgesteckt "Anhaenger wurde bei Kl. 15 aus abgesteckt";
CM_ SG_ 1633 AAG_NSL_aktiv "Anhaenger Nebelschlusslicht aktiv";
CM_ SG_ 1633 AAG_Anhaenger_erkannt "Erkennung Anhaenger";
CM_ SG_ 1633 AAG_Blinker_H_aktiv "Anhaenger Blinker aktiv";
CM_ SG_ 1633 AAG_Blinker_HL_def "Anhaenger Blinker links defekt";
CM_ SG_ 1633 AAG_Blinker_HR_def "Anhaenger Blinker rechts defekt";
CM_ SG_ 1633 AAG_Bremslicht_H_def "Anhaenger Bremslicht defekt";
CM_ SG_ 1633 AAG_Schlusslicht_HL_def "Anhaenger Schlußlicht links defekt";
CM_ SG_ 1633 AAG_Schlusslicht_HR_def "Anhaenger Schlußlicht rechts defekt";
CM_ SG_ 1633 AAG_KD_Fehler "Status Kundendienstfehlerspeichereinträge";
CM_ SG_ 1633 AAG_AVS_Fehler "Fehler AVS";
CM_ SG_ 1633 AAG_AVS_Stati "Status AVS (bei abnehmbarer oder mech.schwenkbarer Anhängerkupplung ist der Status immer 0)";
CM_ BO_ 780 "ACC-Botschaft";
CM_ SG_ 780 ACC_Wunschgeschw_erreicht "Signal for Bentley BY83x: ACC_set_speed_achieved

Mit diesem Signal wird im Kombi eine Anzeige angesteuert, wenn das Fahrzeug die gesetzte Wunschgeschwindigkeit erreicht hat.

This signal illuminates the set speed icon a different colour  in the Kombi";
CM_ SG_ 780 ACC_02_CHK "Bildung der Checksumme
Checksumme = Byte2 XOR Byte 3 ... XOR Byte n  XOR CHK-Endwert
Wobei 'CHK-Endwert' abhängig ist vom CAN-ID: CHK-Endwert = MSB XOR LSB
MSB: High-Byte des Identifiers der CAN-Botschaft LSB: Low-Byte des Identifiers der CAN-Botschaft";
CM_ SG_ 780 ACC_Wunschgeschw "Zur Anzeige der Wunschgeschwindigkeit im Kombiinstrument

0x3FE = keine Anzeige
0x3FF = nicht definiert";
CM_ SG_ 780 ACC_Status_Prim_Anz "Ansteuerung einer primären Statusanzeige für ACC/GRA in verschiedenen Farben

0x0 = Symbol nicht beleuchtet
0x1 = Farbe 1 (typisch 'grün')
0x2 = Farbe 2 (typisch 'rot')
0x3 = Farbe 3 (typisch 'gelb')";
CM_ SG_ 780 ACC_Abstandsindex "Für die optionale Anzeige einer einheitenlosen Abstandsreserve oder einer gemessenen Zeitlücke in der Zusatzanzeige";
CM_ SG_ 780 ACC_Akustik "Im Audi-ACC-Projekt:

Ansteuerung der zugehörigen Gongvariante im Kombiinstrument, solange die entsprechende Bitkombination gesetzt ist.

0x0 = keine Gongansteuerung
0x1 = Gong 1 laut
0x2 = Gong 2 laut
0x3 = Gong 1 mittel
0x4 = Gong 2 mittel
0x5 ";
CM_ SG_ 780 ACC_Gesetzte_Zeitluecke "Nur in ADR/ACC-Fahrzeugen: ACC Zusatzanzeige: 0 = aus / ungleich 0 = ein; angezeigte ADR-Zeitlücke wird auf 3 Bits begrenzt

0x0 = keine Anzeige
0x1 = Zeitlücke 1
...
0x7 = Zeitlücke 7
";
CM_ SG_ 780 ACC_Optischer_Fahrerhinweis "Fahrerübernahmeaufforderung; z.B. bei Erreichen der Systemgrenzen oder beim Auftreten von Fehlern in kritischen Situationen (VW).

0x0 = optischer Fahrerhinweis AUS
0x1 = optischer Fahrerhinweis EIN
";
CM_ SG_ 780 ACC_Typ_Tachokranz "Abhängig von der ACC-Codierung ¿Land¿ ist der Bereich der einstellbaren Wunschgeschwindigkeit und damit die Länge des schwach beleuchteten Tachokranzes begrenzt. Das Bit steuert im Kombi die Ausleuchtung des Tachokranzes an.
Der auszuleuchtende Bereich i";
CM_ SG_ 780 ACC_Anzeige_Zeitluecke "Anforderung zur Umschaltung zwischen dem Anzeigemodus 'Keine Änderung Zeitlücke' und 'Änderung Zeitlücke' (z.B. Pfeildarstellung in Zusatzanzeige)

0x0 = Anzeige Zeitlücke nicht angefordert
0x1 = Anzeige Zeitlücke angefordert
";
CM_ SG_ 780 ACC_Tachokranz "Für zusätzliche Status- und Einstellbereichsanzeige im Tacho. (z.B. Tachokranz)

0x0 = Tachokranz nicht beleuchtet
0x1 = Tachokranz beleuchtet
";
CM_ SG_ 780 ACC_Display_Prio "Zur situationsabhängigen Prioritätensteuerung von ACC Anzeigen im nicht permanenten Anzeigebereich. Im Kombiinstrument ist jeder Prioritätsstufe eine adäquate Prio-Definition zugeordnet.

0x0 = höchste Priorität
0x1 = mittlere Priorität
0x2 = geringe ";
CM_ SG_ 780 ACC_Relevantes_Objekt "Ansteuerung einer primären Anzeige 'Relevantes Objekt' für ACC in verschiedenen Farben.
";
CM_ SG_ 780 ACC_Texte_Primaeranz "Textdefinitionen im DBC-File!";
CM_ SG_ 780 ACC_Status_Anzeige "Status nur zur Defintion von Anzeige im Kombi. Hinweis: Wird für die spez. VW-Anzeige (überlappende Anzeigebereiche) verwendet. Vom AUDI-ACC im Rahmen der Modulstrategie zu bedienen.

0x0 = ACC/GRA Hauptschalter aus
0x1 = ACC in Init (nicht bei GRA)
0";
CM_ BO_ 1743 "Elektrischer Motor";
CM_ SG_ 1743 NMH_EM_keine_HV_Entl "HV-Entladung nicht möglich (NM-Nachlaufursache, nicht 'Ready To Sleep')";
CM_ SG_ 1743 NMH_EM_Start_1 "Transition in NMH-Statemachine: 'Bus-Sleep' ==> 'Start'
Das Bit wird von der Standard-SW bedient.";
CM_ SG_ 1743 NMH_EM_Start_2 "Transition in NMH-Statemachine: 'Prepare To Sleep' ==> 'Start'
Das Bit wird von der Standard-SW bedient.";
CM_ SG_ 1743 NMH_EM_Normal_Mode_1 "Transition in NMH-Statemachine: 'Start' ==> 'Normal Mode'
Das Bit wird von der Standard-SW bedient.";
CM_ SG_ 1743 NMH_EM_Normal_Mode_2 "Transition in NMH-Statemachine: 'Ready To Sleep' ==> 'Normal'
Das Bit wird von der Standard-SW bedient.";
CM_ SG_ 1743 NMH_EM_Car_WakeUp "Das Bit wird vom SG nicht bedient. Die Car Wakeup-Funktionalität ist im SG nicht umgesetzt.
";
CM_ SG_ 1743 NMH_EM_Per_WakeUp "Peripherie-Wakeup (Peripherie inkl. CAN hat geweckt):
1 = CAN

";
CM_ SG_ 1743 NMH_EM_Fkt_WakeUp "Funktions-Wakeup (Softwarefunktion hat geweckt):
0x0 Peripherie-Wakeup


";
CM_ SG_ 1743 NMH_EM_Klemme_15 "NM-Nachlaufursache: Das SG sendet noch NM-high Botschaften (befindet sich nicht im Zustand 'Ready To Sleep') aufgrund einer eingeschalteten Kl.15. In diesem Fall wird das Bit vom SG gesetzt.";
CM_ SG_ 1743 NMH_EM_Diagnose "NM-Nachlaufursache: Das SG sendet noch NM-high Botschaften (befindet sich nicht im Zustand 'Ready To Sleep') bei Kl.15 AUS und aktiver Diagnosesession. In diesem Fall wird das Bit vom SG gesetzt.";
CM_ SG_ 1743 NMH_EM_MindestAktivZeit "NM-Nachlaufursache: Das SG sendet noch NM-high Botschaften (befindet sich nicht im Zustand 'Ready To Sleep') aufgrund der Mindestaktivzeit von 4s. In diesem Fall wird das Bit vom SG gesetzt.";
CM_ SG_ 1743 NMH_EM_NL_Datem_EEPROM "EEPROM Datenspeicherung (lokaler / SG interner Nachlauf vor Wakeup)";
CM_ SG_ 1743 NMH_EM_Signalfehler "Bei der Speicherung eines CAN-Signalfehlers muss dieser mindestens einmal in der NM-Botschaft angezeigt werden.";
CM_ SG_ 1743 NMH_EM_TimeOut_Fehler "Das SG hat einen aktiven Timeout-Fehler zu einem anderen SG erkannt und setzt dieses Bit. Der FSP-Eintrag ist aktiv. Sobald wieder Botschaften des anderen Teilnehmers empfangen werden (FSP-Eintrag passiv), wird das Bit zurückgesetzt.";
CM_ SG_ 1743 NMH_EM_CAN_Diag_deaktiv "Das Bit wird vom SG in folgenden Fällen gesetzt (CAN-Diagnose ist deaktiv):
- Hochlauf des Steuergeräts nach CAN-Wakeup (t_diag_start ist noch nicht abgelaufen)
- Retriggerung von t_diag_start bei Kl.15 EIN
- Unterspannung (U < 9V)
- Überspannung (U >";
CM_ SG_ 1743 NMH_EM_KompSchutz "Das Bit wird vom SG immer mit 0 gesendet";
CM_ SG_ 1743 NMH_EM_Mute_Mode "Das Bit wird vom SG wie folgt bedient: wenn über den UDS-Service 'Communication Control' ein Abschalten der Applikationsbotschaften gefordert wird und gleichzeitig noch NWM-Botschaften gesendet werden dürfen, dann wird das Bit gesetzt
";
CM_ SG_ 1743 NMH_EM_Transport_Mode "Funktionseinschränkung aufgrund Transportmodus aktiv:
Das Bit wird vom SG gesetzt, wenn das Signal 'BEM_02_Abschaltstufen' in der Botschaft BEM_02 den Wert 4 
(= Transportmodus) annimmt. Die Ambientebeleuchtung wird vom SG abgeschaltet bzw. nicht einges";
CM_ SG_ 1743 NMH_EM_Abschaltstufe_aktiv "Funktionseinschränkung aufgrund Abschaltstufe aktiv:
Das Bit wird vom SG gesetzt, wenn das Signal 'BEM_02_Abschaltstufen' in der Botschaft BEM_02 den Wert 2 (= Stufe 2), den Wert 3 (= Stufe 3) oder den Wert 7 (= Ruhestrommessmodus) annimmt. Die Ambienteb";
CM_ SG_ 1743 NMH_EM_Busfehler "Das Bit wird vom SG gesetzt, wenn der ERROR-Pin des CAN-Transceivers dem µController einen Fehler signalisiert.";
CM_ SG_ 1743 NMH_EM_Lokalaktiv "Zeigt an ob Steuergerät lokal aktiv war";
CM_ SG_ 1743 NMH_EM_Subsystemaktiv "Zeigt an ob ein Subsystem des SGs nach Klemme15 AUS und nach entsprechender MAX Aktivzeit noch aktiv war";
CM_ BO_ 786 "Triebstrangkoordinator (TSK) Botschaft";
CM_ SG_ 786 TSK_03_CHK "Berechnung siehe Lastenheft 'Kommunikationsabsicherung für FlexRay und CAN'
Endwerte siehe 'Kommunikationsabsicherung für FlexRay und CAN / Anhang C: Tabelle S-PDU Kennungen'";
CM_ SG_ 786 TSK_03_BZ "Botschaftszähler";
CM_ SG_ 786 FAS_Wunschgeschw "Zur Anzeige der Wunschgeschwindigkeit im Kombiinstrument.";
CM_ SG_ 786 FAS_Texte_Primaeranz "0x43-7F = tbd.";
CM_ SG_ 786 FAS_Status_Prim_Anz "Ansteuerung einer primären Statusanzeige für ACC/GRA in verschiedenen Farben";
CM_ SG_ 786 FAS_Status_Anzeige "Analog zum Status nur zur Defintion von Anzeige im Kombi. Hinweis: Wird für die spez. VW-Anzeige (überlappende Anzeigebereiche) verwendet. Vom AUDI-ACC im Rahmen der Modulstrategie zu bedienen.";
CM_ BO_ 16 "Wegfahrsperrenbotschaft (entspricht der Botschaft 'MSG1_WFS_Anfrage' im MLB)";
CM_ SG_ 16 WFS_MSG1_IMS "Wegfahrsperre";
CM_ BO_ 17 "Wegfahrsperrenbotschaft";
CM_ SG_ 17 WFS_IMS_MSG1 "Wegfahrsperre";
BA_DEF_ SG_  "DERIVATE_Pruefung" ENUM  "offen","geprüft";
BA_DEF_ SG_  "HYB_Rx_Baureihe" ENUM  "G1+Derivate","nur G1","nur Derivate";
BA_DEF_ SG_  "HYB_Rx_Verwendung" ENUM  "DERIV_Rout","DERIV_Calc","DERIV_Rout+DERIV_Calc";
BA_DEF_ SG_  "GenSigSwitchedByIgnition" ENUM  "No","Yes";
BA_DEF_ SG_  "GenSigEnvVarType" ENUM  "int","float","undef";
BA_DEF_ SG_  "GenSigAutoGenSnd" ENUM  "No","Yes";
BA_DEF_ SG_  "GenSigAutoGenDsp" ENUM  "No","Yes";
BA_DEF_ SG_  "GenSigActiveRepetitions" INT -2147483648 2147483647;
BA_DEF_ SG_  "GenSigFuncType" ENUM  "NoFunction","MsgCounter","CRC-8","XOR","XOR-2","DatedBit","SW-Kl15","CHK","Constant","Protocol";
BA_DEF_ SG_  "Info_BCM_HutHut_Kommunikation" ENUM  "Nein","Ja";
BA_DEF_ SG_  "NWM-WakeupAllowed" ENUM  "No","Yes";
BA_DEF_ SG_  "GenSigInactiveValue" STRING ;
BA_DEF_ SG_  "GenSigMissingSourceValue" INT 0 2147483647;
BA_DEF_ SG_  "GenSigStartValue" INT 0 0;
BA_DEF_ SG_  "Fehlerwert" HEX 0 2147483647;
BA_DEF_ SG_  "Bemerkung" STRING ;
BA_DEF_ SG_  "GenSigSendType" ENUM  "Cyclic","OnWrite","OnWriteWithRepetition","OnChange","OnChangeWithRepetition","IfActive","IfActiveWithRepetition","NoSigSendType";
BA_DEF_ BO_  "NmMessage" ENUM  "No","Yes";
BA_DEF_ BO_  "GenMsgAutoGenSnd" ENUM  "No","Yes";
BA_DEF_ BO_  "GenMsgAutoGenDsp" ENUM  "No","Yes";
BA_DEF_ BO_  "MsgType" ENUM  "Broadcast","Event","NM ","NMH","TP2.0","ISO-TP ","BAP","EID";
BA_DEF_ BO_  "GenMsgChkConstant" HEX 0 4095;
BA_DEF_ BO_  "sim_GenMsgILSupport" ENUM  "No","Yes";
BA_DEF_ BO_  "NWM-Botschaft" ENUM  "No","Yes";
BA_DEF_ BO_  "VAGTP20_StatConnection" ENUM  "No","Yes";
BA_DEF_ BO_  "VAGTP20_DynSetup" ENUM  "No","Yes";
BA_DEF_ BO_  "VAGTP20_DynConnection" ENUM  "No","Yes";
BA_DEF_ BO_  "VAGTP20_API" HEX 0 255;
BA_DEF_ BO_  "Direkt_1zu1" ENUM  "Nein","Ja";
BA_DEF_ BO_  "GenMsgSendType" ENUM  "Cyclic","NotUsed","NotUsed","NotUsed","NotUsed","NotUsed","NotUsed","IfActive","NoMsgSendType","NotUsed";
BA_DEF_ BO_  "DiagResponse" ENUM  "No","Yes";
BA_DEF_ BO_  "DiagRequest" ENUM  "No","Yes";
BA_DEF_ BO_  "GenMsgDelayTime" INT 0 65535;
BA_DEF_ BO_  "GenMsgStartDelayTime" INT 0 65535;
BA_DEF_ BO_  "GenMsgILSupport" ENUM  "No","Yes";
BA_DEF_ BO_  "NmhMessage" ENUM  "No","Yes";
BA_DEF_ BO_  "GenMsgNrOfRepetition" INT 0 65535;
BA_DEF_ BO_  "GenMsgCycleTimeFast" INT 0 65535;
BA_DEF_ BO_  "DiagState" ENUM  "No","Yes";
BA_DEF_ BO_  "GenMsgCycleTime" INT 0 65535;
BA_DEF_REL_ BU_BO_REL_  "HYB_Tx_Verwendung" ENUM  "Rout","Calc";
BA_DEF_REL_ BU_BO_REL_  "HYB_Tx_Baureihe" ENUM  "G1+Derivate","G1","Derivate","vector_leerstring";
BA_DEF_REL_ BU_SG_REL_  "GenSigTimeoutTime" INT 0 65535;
BA_DEF_DEF_REL_ "HYB_Tx_Verwendung" "Rout";
BA_DEF_DEF_REL_ "HYB_Tx_Baureihe" "G1+Derivate";
BA_DEF_DEF_  "DERIVATE_Pruefung" "offen";
BA_DEF_DEF_  "HYB_Rx_Baureihe" "G1+Derivate";
BA_DEF_DEF_  "HYB_Rx_Verwendung" "DERIV_Rout";
BA_DEF_DEF_  "GenSigSwitchedByIgnition" "No";
BA_DEF_DEF_  "GenSigEnvVarType" "undef";
BA_DEF_DEF_  "GenSigAutoGenSnd" "No";
BA_DEF_DEF_  "GenSigAutoGenDsp" "No";
BA_DEF_DEF_  "GenSigActiveRepetitions" 0;
BA_DEF_DEF_  "GenSigFuncType" "NoFunction";
BA_DEF_DEF_  "Info_BCM_HutHut_Kommunikation" "Nein";
BA_DEF_DEF_  "NWM-WakeupAllowed" "Yes";
BA_DEF_DEF_  "GenSigInactiveValue" "0";
BA_DEF_DEF_  "GenSigMissingSourceValue" 0;
BA_DEF_DEF_  "GenSigStartValue" 0;
BA_DEF_DEF_  "Fehlerwert" 0;
BA_DEF_DEF_  "Bemerkung" "";
BA_DEF_DEF_  "GenSigSendType" "Cyclic";
BA_DEF_DEF_  "NmMessage" "No";
BA_DEF_DEF_  "GenMsgAutoGenSnd" "Yes";
BA_DEF_DEF_  "GenMsgAutoGenDsp" "Yes";
BA_DEF_DEF_  "MsgType" "Broadcast";
BA_DEF_DEF_  "GenMsgChkConstant" 0;
BA_DEF_DEF_  "sim_GenMsgILSupport" "No";
BA_DEF_DEF_  "NWM-Botschaft" "No";
BA_DEF_DEF_  "VAGTP20_StatConnection" "No";
BA_DEF_DEF_  "VAGTP20_DynSetup" "No";
BA_DEF_DEF_  "VAGTP20_DynConnection" "No";
BA_DEF_DEF_  "VAGTP20_API" 1;
BA_DEF_DEF_  "Direkt_1zu1" "Nein";
BA_DEF_DEF_  "GenMsgSendType" "Cyclic";
BA_DEF_DEF_  "DiagResponse" "No";
BA_DEF_DEF_  "DiagRequest" "No";
BA_DEF_DEF_  "GenMsgDelayTime" 0;
BA_DEF_DEF_  "GenMsgStartDelayTime" 0;
BA_DEF_DEF_  "GenMsgILSupport" "No";
BA_DEF_DEF_  "NmhMessage" "No";
BA_DEF_DEF_  "GenMsgNrOfRepetition" 0;
BA_DEF_DEF_  "GenMsgCycleTimeFast" 0;
BA_DEF_DEF_  "DiagState" "No";
BA_DEF_DEF_  "GenMsgCycleTime" 0;
BA_DEF_DEF_REL_ "GenSigTimeoutTime" 0;
BA_ "GenMsgChkConstant" BO_ 157 157;
BA_ "sim_GenMsgILSupport" BO_ 157 1;
BA_ "VAGTP20_API" BO_ 157 0;
BA_ "Direkt_1zu1" BO_ 157 1;
BA_ "GenMsgILSupport" BO_ 157 1;
BA_ "GenMsgCycleTime" BO_ 157 20;
BA_ "sim_GenMsgILSupport" BO_ 811 1;
BA_ "VAGTP20_API" BO_ 811 0;
BA_ "GenMsgILSupport" BO_ 811 1;
BA_ "GenMsgCycleTime" BO_ 811 50;
BA_ "sim_GenMsgILSupport" BO_ 933 1;
BA_ "VAGTP20_API" BO_ 933 0;
BA_ "GenMsgDelayTime" BO_ 933 50;
BA_ "GenMsgILSupport" BO_ 933 1;
BA_ "GenMsgCycleTime" BO_ 933 100;
BA_ "MsgType" BO_ 1730 3;
BA_ "VAGTP20_API" BO_ 1730 0;
BA_ "GenMsgSendType" BO_ 1730 8;
BA_ "NmhMessage" BO_ 1730 1;
BA_ "GenMsgCycleTime" BO_ 1730 200;
BA_ "MsgType" BO_ 1729 3;
BA_ "VAGTP20_API" BO_ 1729 0;
BA_ "GenMsgSendType" BO_ 1729 8;
BA_ "NmhMessage" BO_ 1729 1;
BA_ "GenMsgCycleTime" BO_ 1729 200;
BA_ "sim_GenMsgILSupport" BO_ 913 1;
BA_ "VAGTP20_API" BO_ 913 0;
BA_ "GenMsgILSupport" BO_ 913 1;
BA_ "GenMsgCycleTime" BO_ 913 100;
BA_ "GenMsgChkConstant" BO_ 270 15;
BA_ "sim_GenMsgILSupport" BO_ 270 1;
BA_ "VAGTP20_API" BO_ 270 0;
BA_ "Direkt_1zu1" BO_ 270 1;
BA_ "GenMsgILSupport" BO_ 270 1;
BA_ "GenMsgCycleTime" BO_ 270 20;
BA_ "GenMsgChkConstant" BO_ 273 16;
BA_ "sim_GenMsgILSupport" BO_ 273 1;
BA_ "VAGTP20_API" BO_ 273 0;
BA_ "Direkt_1zu1" BO_ 273 1;
BA_ "GenMsgILSupport" BO_ 273 1;
BA_ "GenMsgCycleTime" BO_ 273 20;
BA_ "GenMsgChkConstant" BO_ 915 144;
BA_ "sim_GenMsgILSupport" BO_ 915 1;
BA_ "VAGTP20_API" BO_ 915 0;
BA_ "Direkt_1zu1" BO_ 915 1;
BA_ "GenMsgDelayTime" BO_ 915 10;
BA_ "GenMsgILSupport" BO_ 915 1;
BA_ "GenMsgCycleTime" BO_ 915 80;
BA_ "sim_GenMsgILSupport" BO_ 1602 1;
BA_ "VAGTP20_API" BO_ 1602 0;
BA_ "GenMsgDelayTime" BO_ 1602 200;
BA_ "GenMsgILSupport" BO_ 1602 1;
BA_ "GenMsgCycleTime" BO_ 1602 2000;
BA_ "sim_GenMsgILSupport" BO_ 1646 1;
BA_ "GenMsgDelayTime" BO_ 1646 200;
BA_ "GenMsgILSupport" BO_ 1646 1;
BA_ "GenMsgCycleTime" BO_ 1646 2000;
BA_ "sim_GenMsgILSupport" BO_ 1636 1;
BA_ "GenMsgILSupport" BO_ 1636 1;
BA_ "GenMsgCycleTime" BO_ 1636 500;
BA_ "sim_GenMsgILSupport" BO_ 959 1;
BA_ "GenMsgILSupport" BO_ 959 1;
BA_ "GenMsgCycleTime" BO_ 959 100;
BA_ "MsgType" BO_ 2041 1;
BA_ "Direkt_1zu1" BO_ 2041 1;
BA_ "GenMsgSendType" BO_ 2041 8;
BA_ "MsgType" BO_ 2033 1;
BA_ "Direkt_1zu1" BO_ 2033 1;
BA_ "GenMsgSendType" BO_ 2033 8;
BA_ "sim_GenMsgILSupport" BO_ 1413 1;
BA_ "GenMsgDelayTime" BO_ 1413 10;
BA_ "GenMsgILSupport" BO_ 1413 1;
BA_ "GenMsgCycleTime" BO_ 1413 1000;
BA_ "MsgType" BO_ 2616986624 7;
BA_ "VAGTP20_API" BO_ 2616986624 0;
BA_ "GenMsgSendType" BO_ 2616986624 8;
BA_ "MsgType" BO_ 480 7;
BA_ "VAGTP20_API" BO_ 480 0;
BA_ "GenMsgSendType" BO_ 480 8;
BA_ "MsgType" BO_ 901 1;
BA_ "GenMsgChkConstant" BO_ 901 134;
BA_ "VAGTP20_API" BO_ 901 0;
BA_ "GenMsgILSupport" BO_ 901 1;
BA_ "GenMsgCycleTime" BO_ 901 100;
BA_ "MsgType" BO_ 24 1;
BA_ "sim_GenMsgILSupport" BO_ 24 1;
BA_ "VAGTP20_API" BO_ 24 0;
BA_ "Direkt_1zu1" BO_ 24 1;
BA_ "GenMsgSendType" BO_ 24 8;
BA_ "GenMsgILSupport" BO_ 24 1;
BA_ "MsgType" BO_ 25 1;
BA_ "VAGTP20_API" BO_ 25 0;
BA_ "Direkt_1zu1" BO_ 25 1;
BA_ "GenMsgSendType" BO_ 25 8;
BA_ "GenMsgILSupport" BO_ 25 1;
BA_ "sim_GenMsgILSupport" BO_ 1603 1;
BA_ "VAGTP20_API" BO_ 1603 0;
BA_ "GenMsgDelayTime" BO_ 1603 100;
BA_ "GenMsgILSupport" BO_ 1603 1;
BA_ "GenMsgCycleTime" BO_ 1603 1000;
BA_ "GenMsgChkConstant" BO_ 267 10;
BA_ "sim_GenMsgILSupport" BO_ 267 1;
BA_ "VAGTP20_API" BO_ 267 0;
BA_ "Direkt_1zu1" BO_ 267 1;
BA_ "GenMsgDelayTime" BO_ 267 20;
BA_ "GenMsgILSupport" BO_ 267 1;
BA_ "GenMsgNrOfRepetition" BO_ 267 1;
BA_ "GenMsgCycleTimeFast" BO_ 267 20;
BA_ "GenMsgCycleTime" BO_ 267 100;
BA_ "GenMsgChkConstant" BO_ 260 5;
BA_ "sim_GenMsgILSupport" BO_ 260 1;
BA_ "VAGTP20_API" BO_ 260 0;
BA_ "Direkt_1zu1" BO_ 260 1;
BA_ "GenMsgILSupport" BO_ 260 1;
BA_ "GenMsgCycleTime" BO_ 260 20;
BA_ "GenMsgChkConstant" BO_ 64 64;
BA_ "sim_GenMsgILSupport" BO_ 64 1;
BA_ "VAGTP20_API" BO_ 64 0;
BA_ "Direkt_1zu1" BO_ 64 1;
BA_ "GenMsgDelayTime" BO_ 64 10;
BA_ "GenMsgILSupport" BO_ 64 1;
BA_ "GenMsgCycleTime" BO_ 64 50;
BA_ "sim_GenMsgILSupport" BO_ 1312 1;
BA_ "VAGTP20_API" BO_ 1312 0;
BA_ "GenMsgILSupport" BO_ 1312 1;
BA_ "GenMsgCycleTime" BO_ 1312 200;
BA_ "GenMsgChkConstant" BO_ 777 10;
BA_ "sim_GenMsgILSupport" BO_ 777 1;
BA_ "VAGTP20_API" BO_ 777 0;
BA_ "GenMsgILSupport" BO_ 777 1;
BA_ "GenMsgCycleTime" BO_ 777 50;
BA_ "sim_GenMsgILSupport" BO_ 1714 1;
BA_ "VAGTP20_API" BO_ 1714 0;
BA_ "GenMsgILSupport" BO_ 1714 1;
BA_ "GenMsgCycleTime" BO_ 1714 1000;
BA_ "sim_GenMsgILSupport" BO_ 1313 1;
BA_ "VAGTP20_API" BO_ 1313 0;
BA_ "GenMsgILSupport" BO_ 1313 1;
BA_ "GenMsgCycleTime" BO_ 1313 200;
BA_ "GenMsgChkConstant" BO_ 134 134;
BA_ "sim_GenMsgILSupport" BO_ 134 1;
BA_ "VAGTP20_API" BO_ 134 0;
BA_ "Direkt_1zu1" BO_ 134 1;
BA_ "GenMsgILSupport" BO_ 134 1;
BA_ "GenMsgCycleTime" BO_ 134 10;
BA_ "sim_GenMsgILSupport" BO_ 1633 1;
BA_ "VAGTP20_API" BO_ 1633 0;
BA_ "Direkt_1zu1" BO_ 1633 1;
BA_ "GenMsgILSupport" BO_ 1633 1;
BA_ "GenMsgCycleTime" BO_ 1633 100;
BA_ "GenMsgChkConstant" BO_ 780 15;
BA_ "sim_GenMsgILSupport" BO_ 780 1;
BA_ "VAGTP20_API" BO_ 780 0;
BA_ "Direkt_1zu1" BO_ 780 1;
BA_ "GenMsgILSupport" BO_ 780 1;
BA_ "GenMsgCycleTime" BO_ 780 40;
BA_ "MsgType" BO_ 1743 3;
BA_ "VAGTP20_API" BO_ 1743 0;
BA_ "GenMsgSendType" BO_ 1743 8;
BA_ "NmhMessage" BO_ 1743 1;
BA_ "GenMsgCycleTime" BO_ 1743 200;
BA_ "GenMsgChkConstant" BO_ 786 17;
BA_ "sim_GenMsgILSupport" BO_ 786 1;
BA_ "Direkt_1zu1" BO_ 786 1;
BA_ "GenMsgDelayTime" BO_ 786 10;
BA_ "GenMsgILSupport" BO_ 786 1;
BA_ "GenMsgCycleTime" BO_ 786 50;
BA_ "MsgType" BO_ 16 1;
BA_ "sim_GenMsgILSupport" BO_ 16 1;
BA_ "VAGTP20_API" BO_ 16 0;
BA_ "Direkt_1zu1" BO_ 16 1;
BA_ "GenMsgSendType" BO_ 16 8;
BA_ "GenMsgILSupport" BO_ 16 1;
BA_ "MsgType" BO_ 17 1;
BA_ "sim_GenMsgILSupport" BO_ 17 1;
BA_ "VAGTP20_API" BO_ 17 0;
BA_ "Direkt_1zu1" BO_ 17 1;
BA_ "GenMsgSendType" BO_ 17 8;
BA_ "GenMsgILSupport" BO_ 17 1;
BA_ "GenSigAutoGenSnd" SG_ 157 MO_HYB_EMode_Info 1;
BA_ "GenSigAutoGenDsp" SG_ 157 MO_HYB_EMode_Info 1;
BA_ "NWM-WakeupAllowed" SG_ 157 MO_HYB_EMode_Info 0;
BA_ "GenSigFuncType" SG_ 157 Motor_Hybrid_01_CHK 4;
BA_ "GenSigFuncType" SG_ 157 Motor_Hybrid_01_BZ 1;
BA_ "Fehlerwert" SG_ 157 MO_HYB_IstStatusK0 3;
BA_ "GenSigStartValue" SG_ 157 MO_HYB_max_ind_VM_Mom 1022;
BA_ "Fehlerwert" SG_ 157 MO_HYB_max_ind_VM_Mom 1023;
BA_ "Fehlerwert" SG_ 157 MO_HYB_Zielzustand 7;
BA_ "GenSigStartValue" SG_ 157 MO_HYB_VM_Mom_oE 100;
BA_ "Fehlerwert" SG_ 157 MO_HYB_VM_Mom_oE 1023;
BA_ "NWM-WakeupAllowed" SG_ 811 MO_FahrPr7_verfuegbar 0;
BA_ "NWM-WakeupAllowed" SG_ 811 MO_FahrPr6_verfuegbar 0;
BA_ "NWM-WakeupAllowed" SG_ 811 MO_FahrPr5_verfuegbar 0;
BA_ "NWM-WakeupAllowed" SG_ 811 MO_FahrPr4_verfuegbar 0;
BA_ "NWM-WakeupAllowed" SG_ 811 MO_FahrPr3_verfuegbar 0;
BA_ "NWM-WakeupAllowed" SG_ 811 MO_FahrPr2_verfuegbar 0;
BA_ "NWM-WakeupAllowed" SG_ 811 MO_FahrPr1_verfuegbar 0;
BA_ "Fehlerwert" SG_ 811 MO_HYB_Drehzahl_VM 65280;
BA_ "NWM-WakeupAllowed" SG_ 933 Enrgfluss_State 0;
BA_ "Fehlerwert" SG_ 933 Enrgfluss_State 255;
BA_ "NWM-WakeupAllowed" SG_ 933 Ladezustand 0;
BA_ "Fehlerwert" SG_ 933 Ladezustand 255;
BA_ "GenSigStartValue" SG_ 933 Energiefluss 128;
BA_ "Fehlerwert" SG_ 933 Energiefluss 255;
BA_ "Fehlerwert" SG_ 933 Enrgrueckfluss 255;
BA_ "NWM-WakeupAllowed" SG_ 933 MO_Temp_MotRaum 0;
BA_ "GenSigStartValue" SG_ 933 MO_Temp_MotRaum 62;
BA_ "Fehlerwert" SG_ 933 MO_Temp_MotRaum 63;
BA_ "NWM-WakeupAllowed" SG_ 933 MO_Oel_Temp_Radsatz 0;
BA_ "GenSigStartValue" SG_ 933 MO_Oel_Temp_Radsatz 254;
BA_ "Fehlerwert" SG_ 933 MO_Oel_Temp_Radsatz 255;
BA_ "GenSigSendType" SG_ 933 MO_LED_Abgasklappe 3;
BA_ "GenSigSendType" SG_ 933 MO_Hoch_Anz_Nmax 3;
BA_ "NWM-WakeupAllowed" SG_ 933 MO_Hoch_Anz_Nmax 0;
BA_ "GenSigSendType" SG_ 933 MO_Hoch_Anz_Eco 3;
BA_ "NWM-WakeupAllowed" SG_ 933 MO_Hoch_Anz_Eco 0;
BA_ "NWM-WakeupAllowed" SG_ 933 MO_Fehler_MSpG 0;
BA_ "GenSigSendType" SG_ 933 MO_Anf_Abgasklappe 3;
BA_ "GenSigStartValue" SG_ 1730 NMH_GE_Start_1 1;
BA_ "GenSigStartValue" SG_ 1729 NMH_MO_Start_1 1;
BA_ "GenSigStartValue" SG_ 913 OBD_Calc_Load_Val 255;
BA_ "GenSigStartValue" SG_ 913 OBD_Eng_Cool_Temp 255;
BA_ "GenSigStartValue" SG_ 913 OBD_Abs_Throttle_Pos 255;
BA_ "GenSigStartValue" SG_ 913 OBD_Abs_Load_Val 65535;
BA_ "GenSigStartValue" SG_ 913 OBD_Abs_Pedal_Pos 255;
BA_ "NWM-WakeupAllowed" SG_ 913 OBD_Sperrung_IUMPR 0;
BA_ "NWM-WakeupAllowed" SG_ 913 OBD_Kaltstart_Denominator 0;
BA_ "NWM-WakeupAllowed" SG_ 913 OBD_Minimum_Trip 0;
BA_ "GenSigFuncType" SG_ 270 TSK_04_CHK 4;
BA_ "GenSigFuncType" SG_ 270 TSK_04_BZ 1;
BA_ "GenSigStartValue" SG_ 270 TSK_ax_Getriebe 84;
BA_ "Fehlerwert" SG_ 273 TSK_Fahrzeugmasse_02 255;
BA_ "GenSigFuncType" SG_ 273 TSK_05_CHK 4;
BA_ "GenSigFuncType" SG_ 273 TSK_05_BZ 1;
BA_ "GenSigStartValue" SG_ 273 TSK_QBit_Steigung 1;
BA_ "Fehlerwert" SG_ 273 TSK_Fahrzeugmasse 31;
BA_ "GenSigStartValue" SG_ 273 TSK_QBit_Fahrzeugmasse 1;
BA_ "Fehlerwert" SG_ 273 TSK_Steigung 255;
BA_ "GenSigStartValue" SG_ 273 TSK_Verzoeg_Anf_02 166;
BA_ "NWM-WakeupAllowed" SG_ 915 GE_Tipschaltempf_verfuegbar 0;
BA_ "NWM-WakeupAllowed" SG_ 915 GE_Sollgang 0;
BA_ "GenSigSendType" SG_ 915 WBA_GE_Zusatzwarnungen 3;
BA_ "NWM-WakeupAllowed" SG_ 915 WBA_GE_Zusatzwarnungen 0;
BA_ "NWM-WakeupAllowed" SG_ 915 WBA_Effizienzmodus 0;
BA_ "GenSigFuncType" SG_ 915 WBA_02_BZ 1;
BA_ "GenSigSendType" SG_ 915 WBA_Senderkennung 3;
BA_ "GenSigSendType" SG_ 915 WBA_Lampe_Shift_Lock 3;
BA_ "GenSigSendType" SG_ 915 WBA_Blinken 3;
BA_ "GenSigSendType" SG_ 915 WBA_Getriebevariante 3;
BA_ "GenSigSendType" SG_ 915 WBA_GE_Warnung 3;
BA_ "GenSigSendType" SG_ 915 WBA_Fahrstufe 3;
BA_ "NWM-WakeupAllowed" SG_ 915 WBA_Schaltempf_verfbar 0;
BA_ "GenSigSendType" SG_ 915 WBA_eing_Gang 3;
BA_ "GenSigStartValue" SG_ 915 WBA_eing_Gang 1;
BA_ "GenSigSendType" SG_ 915 WBA_GE_Texte 3;
BA_ "GenSigSendType" SG_ 915 WBA_Schaltschema_Aktiv 3;
BA_ "GenSigSendType" SG_ 915 WH_Warnung 3;
BA_ "GenSigFuncType" SG_ 915 WBA_02_CHK 4;
BA_ "Fehlerwert" SG_ 1602 WIV_Verschleissindex 65535;
BA_ "Fehlerwert" SG_ 1602 WIV_Russindex 65535;
BA_ "GenSigStartValue" SG_ 1602 WIV_t_min 12;
BA_ "GenSigStartValue" SG_ 1602 WIV_t_max 24;
BA_ "GenSigStartValue" SG_ 1602 WIV_W_min 17;
BA_ "GenSigStartValue" SG_ 1602 WIV_W_max 31;
BA_ "GenSigSendType" SG_ 1646 KL_STL_aktiv 3;
BA_ "GenSigSendType" SG_ 1646 KL_STH_Betriebsdauer 3;
BA_ "GenSigSendType" SG_ 1646 KL_STH_Ansteuerung 3;
BA_ "GenSigSendType" SG_ 1646 KL_STH_aktiv 3;
BA_ "GenSigMissingSourceValue" SG_ 1646 KL_Innen_Temp 255;
BA_ "GenSigMissingSourceValue" SG_ 1646 KL_AussenTemp_WK 255;
BA_ "GenSigStartValue" SG_ 1646 KL_AussenTemp_WK 254;
BA_ "Fehlerwert" SG_ 1646 KL_AussenTemp_WK 255;
BA_ "Fehlerwert" SG_ 1636 KL_I_Geblaese 255;
BA_ "NWM-WakeupAllowed" SG_ 1636 KL_Beschlagsgefahr 0;
BA_ "GenSigStartValue" SG_ 1636 KL_Umluftklappe_Status 14;
BA_ "Fehlerwert" SG_ 1636 KL_Umluftklappe_Status 15;
BA_ "GenSigMissingSourceValue" SG_ 1636 KL_Geblaese_Status 15;
BA_ "GenSigStartValue" SG_ 1636 KL_Geblaese_Status 14;
BA_ "Fehlerwert" SG_ 1636 KL_Geblaese_Status 15;
BA_ "Bemerkung" SG_ 959 KL_Drehz_Anh "0=keine Drehzahlanhebung; 1=Drehzahlanhebung";
BA_ "Bemerkung" SG_ 959 KL_Anf_KL "Ansteuerung des Kuehlerluefters in Prozent";
BA_ "Fehlerwert" SG_ 959 KL_Last_Kompr 255;
BA_ "GenSigSendType" SG_ 2041 Response_Airbag_Deployment 1;
BA_ "GenSigSendType" SG_ 2033 Request_Airbag_Deployment 1;
BA_ "GenSigSendType" SG_ 1413 SI_QRS_Mode 3;
BA_ "NWM-WakeupAllowed" SG_ 1413 SI_QRS_Mode 0;
BA_ "GenSigSendType" SG_ 1413 SI_NWDF_gueltig 3;
BA_ "GenSigSendType" SG_ 1413 SI_NWDF 3;
BA_ "GenSigSendType" SG_ 1413 SI_Diagnose_Aktiv 3;
BA_ "GenSigSendType" SG_ 1413 SI_Fahrwerk_Sleep 3;
BA_ "GenSigStartValue" SG_ 1413 SI_Fahrwerk_Sleep 1;
BA_ "GenSigSendType" SG_ 1413 SI_CAN_Crash_Sleep 3;
BA_ "GenSigStartValue" SG_ 1413 SI_CAN_Crash_Sleep 1;
BA_ "GenSigSendType" SG_ 1413 SI_CAN_Antrieb_Sleep 3;
BA_ "GenSigStartValue" SG_ 1413 SI_CAN_Antrieb_Sleep 1;
BA_ "GenSigSendType" SG_ 1413 SI_CAN_MMI_Sleep 3;
BA_ "GenSigStartValue" SG_ 1413 SI_CAN_MMI_Sleep 1;
BA_ "GenSigSendType" SG_ 1413 SI_CAN_Komfort_Sleep 3;
BA_ "GenSigStartValue" SG_ 1413 SI_CAN_Komfort_Sleep 1;
BA_ "GenSigSendType" SG_ 1413 SI_T_Mode 3;
BA_ "NWM-WakeupAllowed" SG_ 2616986624 CCP_MO_CRO_02_Data 0;
BA_ "NWM-WakeupAllowed" SG_ 480 CCP_MO_CRO_01_Data 0;
BA_ "GenSigFuncType" SG_ 901 CHA_01_CHK 3;
BA_ "NWM-WakeupAllowed" SG_ 901 CHA_01_CHK 0;
BA_ "GenSigFuncType" SG_ 901 CHA_01_BZ 1;
BA_ "NWM-WakeupAllowed" SG_ 901 CHA_01_BZ 0;
BA_ "NWM-WakeupAllowed" SG_ 901 CHA_Systemstatus 0;
BA_ "NWM-WakeupAllowed" SG_ 901 CHA_Ziel_FahrPr_MO 0;
BA_ "NWM-WakeupAllowed" SG_ 901 CHA_Ziel_FahrPr_GE 0;
BA_ "NWM-WakeupAllowed" SG_ 901 CHA_Ziel_FahrPr_ST 0;
BA_ "NWM-WakeupAllowed" SG_ 901 CHA_Ziel_FahrPr_SCU 0;
BA_ "NWM-WakeupAllowed" SG_ 901 CHA_Ziel_FahrPr_DR 0;
BA_ "NWM-WakeupAllowed" SG_ 901 CHA_Ziel_FahrPr_QS 0;
BA_ "NWM-WakeupAllowed" SG_ 901 CHA_Ziel_FahrPr_AFS 0;
BA_ "NWM-WakeupAllowed" SG_ 901 CHA_Ziel_FahrPr_RGS 0;
BA_ "NWM-WakeupAllowed" SG_ 901 CHA_Ziel_FahrPr_EPS 0;
BA_ "NWM-WakeupAllowed" SG_ 901 CHA_Ziel_FahrPr_ACC 0;
BA_ "GenSigSendType" SG_ 24 WFS_MSG4_IMS 3;
BA_ "GenSigSendType" SG_ 25 WFS_IMS_MSG4 3;
BA_ "GenSigSendType" SG_ 1603 KBI_Einheit_Verbrauch_elektr 3;
BA_ "NWM-WakeupAllowed" SG_ 1603 KBI_Einheit_Verbrauch_elektr 0;
BA_ "GenSigSendType" SG_ 1603 KBI_Einheit_Datum 3;
BA_ "GenSigSendType" SG_ 1603 KBI_Einheit_Streckenanz 3;
BA_ "GenSigSendType" SG_ 1603 KBI_Einheit_Temp 3;
BA_ "GenSigSendType" SG_ 1603 KBI_Einheit_Uhrzeit 3;
BA_ "Bemerkung" SG_ 1603 KBI_Einheit_Uhrzeit "Eingestelltes Zeitformat im Kombiinstrument.";
BA_ "GenSigSendType" SG_ 1603 KBI_Einheit_Sprache 3;
BA_ "Fehlerwert" SG_ 1603 KBI_Einheit_Sprache 255;
BA_ "GenSigSendType" SG_ 1603 KBI_Einheit_Volumen 3;
BA_ "GenSigSendType" SG_ 1603 KBI_Einheit_Verbrauch 3;
BA_ "GenSigSendType" SG_ 1603 KBI_MFA_v_Einheit_02 3;
BA_ "GenSigSendType" SG_ 1603 KBI_Einheit_Druck 3;
BA_ "NWM-WakeupAllowed" SG_ 267 LS_Fehler 0;
BA_ "GenSigFuncType" SG_ 267 LS_01_CHK 3;
BA_ "GenSigFuncType" SG_ 267 LS_01_BZ 1;
BA_ "NWM-WakeupAllowed" SG_ 267 LS_Tip_Stufe_2 0;
BA_ "NWM-WakeupAllowed" SG_ 267 LS_GRA_ACC_2stufig 0;
BA_ "Fehlerwert" SG_ 260 EPB_Pedalweg_Kuppl 255;
BA_ "GenSigStartValue" SG_ 260 EPB_QBit_Schalterpos 1;
BA_ "GenSigStartValue" SG_ 260 EPB_Spannkraft 30;
BA_ "Fehlerwert" SG_ 260 EPB_Spannkraft 31;
BA_ "GenSigFuncType" SG_ 260 EPB_01_CHK 3;
BA_ "GenSigFuncType" SG_ 260 EPB_01_BZ 1;
BA_ "GenSigStartValue" SG_ 260 EPB_QBit_Laengsbeschleunigung 1;
BA_ "Bemerkung" SG_ 260 EPB_QBit_Laengsbeschleunigung "Signal wird im Panamera nicht unterstützt. Es wird konstant '1' (Ersatz-, Init- oder Fehlerwert) gesendet.";
BA_ "GenSigStartValue" SG_ 260 EPB_QBit_Pedalweg_Kuppl 1;
BA_ "Bemerkung" SG_ 260 EPB_BCM2_Motor_Wakeup "Signal wird im Panamera nicht unterstützt und konstant 0 (kein Nachwecken) gesendet.";
BA_ "GenSigStartValue" SG_ 260 EPB_Verzoeg_Anf 166;
BA_ "Fehlerwert" SG_ 260 EPB_Laengsbeschleunigung 255;
BA_ "Bemerkung" SG_ 260 EPB_Laengsbeschleunigung "Signal wird im Panamera nicht unterstützt. Es wird konstant 255 (Fehlerwert) gesendet.";
BA_ "NWM-WakeupAllowed" SG_ 64 AB_Deaktivierung_HV 0;
BA_ "GenSigSendType" SG_ 64 AB_RGS_Anst 3;
BA_ "GenSigStartValue" SG_ 64 AB_RGS_Anst 8;
BA_ "GenSigFuncType" SG_ 64 Airbag_01_CHK 3;
BA_ "GenSigFuncType" SG_ 64 Airbag_01_BZ 1;
BA_ "GenSigSendType" SG_ 64 AB_Front_Crash 3;
BA_ "GenSigSendType" SG_ 64 AB_Heck_Crash 3;
BA_ "GenSigSendType" SG_ 64 AB_SF_Crash 3;
BA_ "GenSigSendType" SG_ 64 AB_SB_Crash 3;
BA_ "GenSigSendType" SG_ 64 AB_Rollover_Crash 3;
BA_ "GenSigSendType" SG_ 64 AB_Crash_Int 3;
BA_ "GenSigStartValue" SG_ 64 AB_Lampe 1;
BA_ "GenSigStartValue" SG_ 64 AB_PAO_Leuchte_Anf 1;
BA_ "GenSigSendType" SG_ 1312 AB_Gurtschloss_Reihe3_MI 3;
BA_ "GenSigStartValue" SG_ 1312 AB_Gurtschloss_Reihe3_MI 1;
BA_ "Bemerkung" SG_ 1312 AB_Gurtschloss_Reihe3_MI "Signal wird im Panamera nicht verwendet. Konstant mit '0' senden.";
BA_ "GenSigSendType" SG_ 1312 AB_Gurtschloss_Reihe3_FA 3;
BA_ "GenSigStartValue" SG_ 1312 AB_Gurtschloss_Reihe3_FA 1;
BA_ "Bemerkung" SG_ 1312 AB_Gurtschloss_Reihe3_FA "Signal wird im Panamera nicht verwendet. Konstant mit '0' senden.";
BA_ "GenSigSendType" SG_ 1312 AB_Gurtschloss_Reihe3_BF 3;
BA_ "GenSigStartValue" SG_ 1312 AB_Gurtschloss_Reihe3_BF 1;
BA_ "Bemerkung" SG_ 1312 AB_Gurtschloss_Reihe3_BF "Signal wird im Panamera nicht verwendet. Konstant mit '0' senden.";
BA_ "GenSigSendType" SG_ 1312 AB_Gurtschloss_Reihe2_BF 3;
BA_ "GenSigStartValue" SG_ 1312 AB_Gurtschloss_Reihe2_BF 1;
BA_ "GenSigSendType" SG_ 1312 AB_Gurtschloss_Reihe2_MI 3;
BA_ "GenSigStartValue" SG_ 1312 AB_Gurtschloss_Reihe2_MI 1;
BA_ "Bemerkung" SG_ 1312 AB_Gurtschloss_Reihe2_MI "Signal wird im Panamera nicht verwendet. Konstant mit '0' senden.";
BA_ "GenSigSendType" SG_ 1312 AB_Gurtschloss_Reihe2_FA 3;
BA_ "GenSigStartValue" SG_ 1312 AB_Gurtschloss_Reihe2_FA 1;
BA_ "GenSigSendType" SG_ 1312 AB_Gurtschloss_BF 3;
BA_ "GenSigStartValue" SG_ 1312 AB_Gurtschloss_BF 1;
BA_ "GenSigSendType" SG_ 1312 AB_Gurtschloss_FA 3;
BA_ "GenSigStartValue" SG_ 1312 AB_Gurtschloss_FA 1;
BA_ "NWM-WakeupAllowed" SG_ 777 BEM_Segel_Info 0;
BA_ "GenSigFuncType" SG_ 777 BEM_01_CHK 3;
BA_ "GenSigFuncType" SG_ 777 BEM_01_BZ 1;
BA_ "GenSigStartValue" SG_ 1714 UH_Monat 1;
BA_ "GenSigStartValue" SG_ 1714 UH_Tag 1;
BA_ "GenSigStartValue" SG_ 1714 Kombi_02_alt 1;
BA_ "Fehlerwert" SG_ 1714 DGN_Verlernzaehler 255;
BA_ "GenSigStartValue" SG_ 1714 KBI_Kilometerstand 1048574;
BA_ "Fehlerwert" SG_ 1714 KBI_Kilometerstand 1048575;
BA_ "GenSigStartValue" SG_ 1714 Uhrzeit_01_alt 1;
BA_ "Bemerkung" SG_ 1313 STH_LED "0=keine Rueckmeldung; 1=Rueckmeldung Standheizung in Betrieb";
BA_ "GenSigStartValue" SG_ 1313 STH_Wassertemp 254;
BA_ "Fehlerwert" SG_ 1313 STH_Wassertemp 255;
BA_ "GenSigFuncType" SG_ 134 LWI_01_CHK 3;
BA_ "GenSigFuncType" SG_ 134 LWI_01_BZ 1;
BA_ "GenSigStartValue" SG_ 134 LWI_QBit_Lenkradwinkel 1;
BA_ "GenSigStartValue" SG_ 134 LWI_Lenkradwinkel 8188;
BA_ "Fehlerwert" SG_ 134 LWI_Lenkradwinkel 8191;
BA_ "GenSigStartValue" SG_ 134 LWI_Lenkradw_Geschw 510;
BA_ "GenSigFuncType" SG_ 134 LWI_01_CRC 2;
BA_ "GenSigFuncType" SG_ 1633 AAG_BZ 1;
BA_ "NWM-WakeupAllowed" SG_ 780 ACC_Wunschgeschw_erreicht 0;
BA_ "GenSigFuncType" SG_ 780 ACC_02_CHK 3;
BA_ "GenSigFuncType" SG_ 780 ACC_02_BZ 1;
BA_ "NWM-WakeupAllowed" SG_ 1743 NMH_EM_keine_HV_Entl 0;
BA_ "GenSigSendType" SG_ 1743 NMH_EM_Start_1 7;
BA_ "NWM-WakeupAllowed" SG_ 1743 NMH_EM_Start_1 0;
BA_ "GenSigSendType" SG_ 1743 NMH_EM_Start_2 7;
BA_ "NWM-WakeupAllowed" SG_ 1743 NMH_EM_Start_2 0;
BA_ "GenSigSendType" SG_ 1743 NMH_EM_Normal_Mode_1 7;
BA_ "NWM-WakeupAllowed" SG_ 1743 NMH_EM_Normal_Mode_1 0;
BA_ "GenSigSendType" SG_ 1743 NMH_EM_Normal_Mode_2 7;
BA_ "NWM-WakeupAllowed" SG_ 1743 NMH_EM_Normal_Mode_2 0;
BA_ "GenSigSendType" SG_ 1743 NMH_EM_Car_WakeUp 7;
BA_ "NWM-WakeupAllowed" SG_ 1743 NMH_EM_Car_WakeUp 0;
BA_ "GenSigSendType" SG_ 1743 NMH_EM_Per_WakeUp 7;
BA_ "GenSigSendType" SG_ 1743 NMH_EM_Fkt_WakeUp 7;
BA_ "GenSigSendType" SG_ 1743 NMH_EM_Klemme_15 7;
BA_ "NWM-WakeupAllowed" SG_ 1743 NMH_EM_Klemme_15 0;
BA_ "GenSigSendType" SG_ 1743 NMH_EM_Diagnose 7;
BA_ "NWM-WakeupAllowed" SG_ 1743 NMH_EM_Diagnose 0;
BA_ "GenSigSendType" SG_ 1743 NMH_EM_MindestAktivZeit 7;
BA_ "NWM-WakeupAllowed" SG_ 1743 NMH_EM_MindestAktivZeit 0;
BA_ "GenSigSendType" SG_ 1743 NMH_EM_NL_Datem_EEPROM 7;
BA_ "NWM-WakeupAllowed" SG_ 1743 NMH_EM_NL_Datem_EEPROM 0;
BA_ "GenSigSendType" SG_ 1743 NMH_EM_Signalfehler 7;
BA_ "NWM-WakeupAllowed" SG_ 1743 NMH_EM_Signalfehler 0;
BA_ "GenSigSendType" SG_ 1743 NMH_EM_TimeOut_Fehler 7;
BA_ "NWM-WakeupAllowed" SG_ 1743 NMH_EM_TimeOut_Fehler 0;
BA_ "GenSigSendType" SG_ 1743 NMH_EM_CAN_Diag_deaktiv 7;
BA_ "NWM-WakeupAllowed" SG_ 1743 NMH_EM_CAN_Diag_deaktiv 0;
BA_ "GenSigSendType" SG_ 1743 NMH_EM_KompSchutz 7;
BA_ "NWM-WakeupAllowed" SG_ 1743 NMH_EM_KompSchutz 0;
BA_ "GenSigSendType" SG_ 1743 NMH_EM_Mute_Mode 7;
BA_ "NWM-WakeupAllowed" SG_ 1743 NMH_EM_Mute_Mode 0;
BA_ "GenSigSendType" SG_ 1743 NMH_EM_Transport_Mode 7;
BA_ "NWM-WakeupAllowed" SG_ 1743 NMH_EM_Transport_Mode 0;
BA_ "GenSigSendType" SG_ 1743 NMH_EM_Abschaltstufe_aktiv 7;
BA_ "NWM-WakeupAllowed" SG_ 1743 NMH_EM_Abschaltstufe_aktiv 0;
BA_ "GenSigSendType" SG_ 1743 NMH_EM_Busfehler 7;
BA_ "NWM-WakeupAllowed" SG_ 1743 NMH_EM_Busfehler 0;
BA_ "GenSigSendType" SG_ 1743 NMH_EM_Lokalaktiv 7;
BA_ "NWM-WakeupAllowed" SG_ 1743 NMH_EM_Lokalaktiv 0;
BA_ "GenSigSendType" SG_ 1743 NMH_EM_Subsystemaktiv 7;
BA_ "NWM-WakeupAllowed" SG_ 1743 NMH_EM_Subsystemaktiv 0;
BA_ "GenSigFuncType" SG_ 786 TSK_03_CHK 4;
BA_ "GenSigFuncType" SG_ 786 TSK_03_BZ 1;
BA_ "GenSigSendType" SG_ 16 WFS_MSG1_IMS 3;
BA_ "GenSigSendType" SG_ 17 WFS_IMS_MSG1 3;
BA_REL_ "GenSigTimeoutTime" BU_SG_REL_ Getriebe_Derivate SG_ 157 MO_HYB_EMode_Info 500;
BA_REL_ "GenSigTimeoutTime" BU_SG_REL_ Getriebe_Derivate SG_ 157 Motor_Hybrid_01_CHK 500;
BA_REL_ "GenSigTimeoutTime" BU_SG_REL_ BMS_Hybrid SG_ 157 Motor_Hybrid_01_BZ 500;
BA_REL_ "GenSigTimeoutTime" BU_SG_REL_ Getriebe_Derivate SG_ 157 Motor_Hybrid_01_BZ 500;
BA_REL_ "GenSigTimeoutTime" BU_SG_REL_ Getriebe_Derivate SG_ 157 MO_HYB_IstStatusK0 500;
BA_REL_ "GenSigTimeoutTime" BU_SG_REL_ Getriebe_Derivate SG_ 157 MO_HYB_max_ind_VM_Mom 500;
BA_REL_ "GenSigTimeoutTime" BU_SG_REL_ BMS_Hybrid SG_ 157 MO_HYB_Zielzustand 500;
BA_REL_ "GenSigTimeoutTime" BU_SG_REL_ Getriebe_Derivate SG_ 157 MO_HYB_Zielzustand 500;
BA_REL_ "GenSigTimeoutTime" BU_SG_REL_ Getriebe_Derivate SG_ 157 MO_HYB_Startmodus 500;
BA_REL_ "GenSigTimeoutTime" BU_SG_REL_ Getriebe_Derivate SG_ 157 MO_HYB_VM_Mom_oE 500;
BA_REL_ "GenSigTimeoutTime" BU_SG_REL_ BMS_Hybrid SG_ 157 MO_HYB_VM_aktiv 500;
BA_REL_ "GenSigTimeoutTime" BU_SG_REL_ Getriebe_Derivate SG_ 157 MO_HYB_VM_aktiv 500;
BA_REL_ "GenSigTimeoutTime" BU_SG_REL_ GW_Routing_Derivate SG_ 157 MO_HYB_VM_aktiv 500;
BA_REL_ "GenSigTimeoutTime" BU_SG_REL_ Getriebe_Derivate SG_ 157 MO_HYB_Schaltverhinderung 500;
BA_REL_ "GenSigTimeoutTime" BU_SG_REL_ Getriebe_Derivate SG_ 157 MO_HYB_Selektor_Momverlauf_EM 500;
BA_REL_ "GenSigTimeoutTime" BU_SG_REL_ Getriebe_Derivate SG_ 157 MO_HYB_Momverlauf_Rek 500;
BA_REL_ "GenSigTimeoutTime" BU_SG_REL_ Getriebe_Derivate SG_ 157 MO_HYB_KnickDZ_Rek 500;
BA_REL_ "GenSigTimeoutTime" BU_SG_REL_ Getriebe_Derivate SG_ 157 MO_HYB_Momverlauf_EM 500;
BA_REL_ "GenSigTimeoutTime" BU_SG_REL_ Getriebe_Derivate SG_ 157 MO_HYB_KnickDZ_EM 500;
BA_REL_ "GenSigTimeoutTime" BU_SG_REL_ GW_Routing_Derivate SG_ 811 MO_FahrPr7_verfuegbar 500;
BA_REL_ "GenSigTimeoutTime" BU_SG_REL_ GW_Routing_Derivate SG_ 811 MO_FahrPr6_verfuegbar 500;
BA_REL_ "GenSigTimeoutTime" BU_SG_REL_ GW_Routing_Derivate SG_ 811 MO_FahrPr5_verfuegbar 500;
BA_REL_ "GenSigTimeoutTime" BU_SG_REL_ GW_Routing_Derivate SG_ 811 MO_FahrPr4_verfuegbar 500;
BA_REL_ "GenSigTimeoutTime" BU_SG_REL_ GW_Routing_Derivate SG_ 811 MO_FahrPr3_verfuegbar 500;
BA_REL_ "GenSigTimeoutTime" BU_SG_REL_ GW_Routing_Derivate SG_ 811 MO_FahrPr2_verfuegbar 500;
BA_REL_ "GenSigTimeoutTime" BU_SG_REL_ GW_Routing_Derivate SG_ 811 MO_FahrPr1_verfuegbar 500;
BA_REL_ "GenSigTimeoutTime" BU_SG_REL_ Getriebe_Derivate SG_ 811 MO_HYB_E_Faktor 500;
BA_REL_ "GenSigTimeoutTime" BU_SG_REL_ GW_Routing_Derivate SG_ 811 MO_HYB_E_Faktor 500;
BA_REL_ "GenSigTimeoutTime" BU_SG_REL_ Getriebe_Derivate SG_ 811 MO_HYB_Drehzahl_VM 500;
BA_REL_ "GenSigTimeoutTime" BU_SG_REL_ GW_Routing_Derivate SG_ 811 MO_HYB_Drehzahl_VM 500;
BA_REL_ "GenSigTimeoutTime" BU_SG_REL_ BMS_Hybrid SG_ 811 MO_HYB_Drehzahl_VM 500;
BA_REL_ "GenSigTimeoutTime" BU_SG_REL_ Getriebe_Derivate SG_ 811 MO_HYB_LowSpeedModus 500;
BA_REL_ "GenSigTimeoutTime" BU_SG_REL_ GW_Routing_Derivate SG_ 811 MO_HYB_LowSpeedModus 500;
BA_REL_ "GenSigTimeoutTime" BU_SG_REL_ GW_Routing_Derivate SG_ 933 MO_Overboost 1000;
BA_REL_ "GenSigTimeoutTime" BU_SG_REL_ GW_Routing_Derivate SG_ 933 Enrgfluss_State 1000;
BA_REL_ "GenSigTimeoutTime" BU_SG_REL_ GW_Routing_Derivate SG_ 933 Ladezustand 1000;
BA_REL_ "GenSigTimeoutTime" BU_SG_REL_ GW_Routing_Derivate SG_ 933 Energiefluss 1000;
BA_REL_ "GenSigTimeoutTime" BU_SG_REL_ GW_Routing_Derivate SG_ 933 Enrgrueckfluss 1000;
BA_REL_ "GenSigTimeoutTime" BU_SG_REL_ GW_Routing_Derivate SG_ 933 MO_Temp_MotRaum 1000;
BA_REL_ "GenSigTimeoutTime" BU_SG_REL_ GW_Routing_Derivate SG_ 933 MO_Oel_Temp_Radsatz 1000;
BA_REL_ "GenSigTimeoutTime" BU_SG_REL_ GW_Routing_Derivate SG_ 933 MO_LED_Abgasklappe 1000;
BA_REL_ "GenSigTimeoutTime" BU_SG_REL_ GW_Routing_Derivate SG_ 933 MO_Hoch_Anz_Nmax 1000;
BA_REL_ "GenSigTimeoutTime" BU_SG_REL_ GW_Routing_Derivate SG_ 933 MO_Hoch_Anz_Eco 1000;
BA_REL_ "GenSigTimeoutTime" BU_SG_REL_ GW_Routing_Derivate SG_ 933 MO_Fehler_MSpG 1000;
BA_REL_ "GenSigTimeoutTime" BU_SG_REL_ GW_Routing_Derivate SG_ 933 MO_Anf_Abgasklappe 1000;
BA_REL_ "GenSigTimeoutTime" BU_SG_REL_ Motor_EDC17_Pirol SG_ 1730 NMH_GE_Start_1 2000;
BA_REL_ "GenSigTimeoutTime" BU_SG_REL_ BMS_Hybrid SG_ 1730 NMH_GE_Start_1 2000;
BA_REL_ "GenSigTimeoutTime" BU_SG_REL_ LEH_Hybrid SG_ 1730 NMH_GE_Start_1 2000;
BA_REL_ "GenSigTimeoutTime" BU_SG_REL_ Ladegeraet_PAG_PF SG_ 1730 NMH_GE_Start_1 2000;
BA_REL_ "GenSigTimeoutTime" BU_SG_REL_ GW_Applikation_Derivate SG_ 1730 NMH_GE_Start_1 2000;
BA_REL_ "GenSigTimeoutTime" BU_SG_REL_ Motor_MED17_Hybrid SG_ 1730 NMH_GE_Start_1 2000;
BA_REL_ "GenSigTimeoutTime" BU_SG_REL_ GW_Applikation_Derivate SG_ 1730 NMH_GE_Start_2 2000;
BA_REL_ "GenSigTimeoutTime" BU_SG_REL_ GW_Applikation_Derivate SG_ 1730 NMH_GE_Normal_Mode_1 2000;
BA_REL_ "GenSigTimeoutTime" BU_SG_REL_ GW_Applikation_Derivate SG_ 1730 NMH_GE_Normal_Mode_2 2000;
BA_REL_ "GenSigTimeoutTime" BU_SG_REL_ BMS_Hybrid SG_ 1729 NMH_MO_Start_1 2000;
BA_REL_ "GenSigTimeoutTime" BU_SG_REL_ LEH_Hybrid SG_ 1729 NMH_MO_Start_1 2000;
BA_REL_ "GenSigTimeoutTime" BU_SG_REL_ Ladegeraet_PAG_PF SG_ 1729 NMH_MO_Start_1 2000;
BA_REL_ "GenSigTimeoutTime" BU_SG_REL_ GW_Applikation_Derivate SG_ 1729 NMH_MO_Start_1 2000;
BA_REL_ "GenSigTimeoutTime" BU_SG_REL_ Getriebe_Derivate SG_ 1729 NMH_MO_Start_1 2000;
BA_REL_ "GenSigTimeoutTime" BU_SG_REL_ GW_Applikation_Derivate SG_ 1729 NMH_MO_Start_2 2000;
BA_REL_ "GenSigTimeoutTime" BU_SG_REL_ GW_Applikation_Derivate SG_ 1729 NMH_MO_Normal_Mode_1 2000;
BA_REL_ "GenSigTimeoutTime" BU_SG_REL_ GW_Applikation_Derivate SG_ 1729 NMH_MO_Normal_Mode_2 2000;
BA_REL_ "GenSigTimeoutTime" BU_SG_REL_ BMS_Hybrid SG_ 913 OBD_Calc_Load_Val 1000;
BA_REL_ "GenSigTimeoutTime" BU_SG_REL_ Getriebe_Derivate SG_ 913 OBD_Calc_Load_Val 1000;
BA_REL_ "GenSigTimeoutTime" BU_SG_REL_ LEH_Hybrid SG_ 913 OBD_Calc_Load_Val 1000;
BA_REL_ "GenSigTimeoutTime" BU_SG_REL_ BMS_Hybrid SG_ 913 OBD_Eng_Cool_Temp 1000;
BA_REL_ "GenSigTimeoutTime" BU_SG_REL_ Getriebe_Derivate SG_ 913 OBD_Eng_Cool_Temp 1000;
BA_REL_ "GenSigTimeoutTime" BU_SG_REL_ LEH_Hybrid SG_ 913 OBD_Eng_Cool_Temp 1000;
BA_REL_ "GenSigTimeoutTime" BU_SG_REL_ BMS_Hybrid SG_ 913 OBD_Abs_Throttle_Pos 1000;
BA_REL_ "GenSigTimeoutTime" BU_SG_REL_ Getriebe_Derivate SG_ 913 OBD_Abs_Throttle_Pos 1000;
BA_REL_ "GenSigTimeoutTime" BU_SG_REL_ LEH_Hybrid SG_ 913 OBD_Abs_Throttle_Pos 1000;
BA_REL_ "GenSigTimeoutTime" BU_SG_REL_ BMS_Hybrid SG_ 913 OBD_Abs_Load_Val 1000;
BA_REL_ "GenSigTimeoutTime" BU_SG_REL_ Getriebe_Derivate SG_ 913 OBD_Abs_Load_Val 1000;
BA_REL_ "GenSigTimeoutTime" BU_SG_REL_ LEH_Hybrid SG_ 913 OBD_Abs_Load_Val 1000;
BA_REL_ "GenSigTimeoutTime" BU_SG_REL_ BMS_Hybrid SG_ 913 OBD_Abs_Pedal_Pos 1000;
BA_REL_ "GenSigTimeoutTime" BU_SG_REL_ Getriebe_Derivate SG_ 913 OBD_Abs_Pedal_Pos 1000;
BA_REL_ "GenSigTimeoutTime" BU_SG_REL_ LEH_Hybrid SG_ 913 OBD_Abs_Pedal_Pos 1000;
BA_REL_ "GenSigTimeoutTime" BU_SG_REL_ BMS_Hybrid SG_ 913 OBD_Driving_Cycle 1000;
BA_REL_ "GenSigTimeoutTime" BU_SG_REL_ Getriebe_Derivate SG_ 913 OBD_Driving_Cycle 1000;
BA_REL_ "GenSigTimeoutTime" BU_SG_REL_ LEH_Hybrid SG_ 913 OBD_Driving_Cycle 1000;
BA_REL_ "GenSigTimeoutTime" BU_SG_REL_ BMS_Hybrid SG_ 913 OBD_Warm_Up_Cycle 1000;
BA_REL_ "GenSigTimeoutTime" BU_SG_REL_ Getriebe_Derivate SG_ 913 OBD_Warm_Up_Cycle 1000;
BA_REL_ "GenSigTimeoutTime" BU_SG_REL_ LEH_Hybrid SG_ 913 OBD_Warm_Up_Cycle 1000;
BA_REL_ "GenSigTimeoutTime" BU_SG_REL_ GW_Applikation_Derivate SG_ 913 OBD_Warm_Up_Cycle 1000;
BA_REL_ "GenSigTimeoutTime" BU_SG_REL_ LEH_Hybrid SG_ 913 OBD_Normed_Trip 1000;
BA_REL_ "GenSigTimeoutTime" BU_SG_REL_ BMS_Hybrid SG_ 913 OBD_Normed_Trip 1000;
BA_REL_ "GenSigTimeoutTime" BU_SG_REL_ Getriebe_Derivate SG_ 913 OBD_Normed_Trip 1000;
BA_REL_ "GenSigTimeoutTime" BU_SG_REL_ BMS_Hybrid SG_ 913 OBD_Sperrung_IUMPR 1000;
BA_REL_ "GenSigTimeoutTime" BU_SG_REL_ LEH_Hybrid SG_ 913 OBD_Kaltstart_Denominator 1000;
BA_REL_ "GenSigTimeoutTime" BU_SG_REL_ BMS_Hybrid SG_ 913 OBD_Kaltstart_Denominator 1000;
BA_REL_ "GenSigTimeoutTime" BU_SG_REL_ LEH_Hybrid SG_ 913 OBD_Minimum_Trip 1000;
BA_REL_ "GenSigTimeoutTime" BU_SG_REL_ Getriebe_Derivate SG_ 913 OBD_Minimum_Trip 1000;
BA_REL_ "GenSigTimeoutTime" BU_SG_REL_ BMS_Hybrid SG_ 913 OBD_Minimum_Trip 1000;
BA_REL_ "GenSigTimeoutTime" BU_SG_REL_ Getriebe_Derivate SG_ 270 TSK_04_CHK 500;
BA_REL_ "GenSigTimeoutTime" BU_SG_REL_ Getriebe_Derivate SG_ 270 TSK_04_BZ 500;
BA_REL_ "GenSigTimeoutTime" BU_SG_REL_ Getriebe_Derivate SG_ 270 TSK_zul_Regelabw 500;
BA_REL_ "GenSigTimeoutTime" BU_SG_REL_ Getriebe_Derivate SG_ 270 TSK_ax_Getriebe 500;
BA_REL_ "GenSigTimeoutTime" BU_SG_REL_ Getriebe_Derivate SG_ 270 TSK_Limiter_aktiv 500;
BA_REL_ "GenSigTimeoutTime" BU_SG_REL_ Getriebe_Derivate SG_ 270 TSK_Status_GRA_ACC_02 500;
BA_REL_ "GenSigTimeoutTime" BU_SG_REL_ GW_Routing_Derivate SG_ 273 TSK_Fahrzeugmasse_02 500;
BA_REL_ "GenSigTimeoutTime" BU_SG_REL_ PSM_Ant_Derivate SG_ 273 TSK_05_CHK 500;
BA_REL_ "GenSigTimeoutTime" BU_SG_REL_ GW_Routing_Derivate SG_ 273 TSK_05_CHK 500;
BA_REL_ "GenSigTimeoutTime" BU_SG_REL_ Getriebe_Derivate SG_ 273 TSK_05_CHK 500;
BA_REL_ "GenSigTimeoutTime" BU_SG_REL_ PSM_Ant_Derivate SG_ 273 TSK_05_BZ 500;
BA_REL_ "GenSigTimeoutTime" BU_SG_REL_ GW_Routing_Derivate SG_ 273 TSK_05_BZ 500;
BA_REL_ "GenSigTimeoutTime" BU_SG_REL_ Getriebe_Derivate SG_ 273 TSK_05_BZ 500;
BA_REL_ "GenSigTimeoutTime" BU_SG_REL_ GW_Routing_Derivate SG_ 273 TSK_QBit_Steigung 500;
BA_REL_ "GenSigTimeoutTime" BU_SG_REL_ PSM_Ant_Derivate SG_ 273 TSK_Status_GRA_ACC_01 500;
BA_REL_ "GenSigTimeoutTime" BU_SG_REL_ GW_Routing_Derivate SG_ 273 TSK_Status_GRA_ACC_01 500;
BA_REL_ "GenSigTimeoutTime" BU_SG_REL_ Getriebe_Derivate SG_ 273 TSK_Fahrzeugmasse 500;
BA_REL_ "GenSigTimeoutTime" BU_SG_REL_ GW_Routing_Derivate SG_ 273 TSK_Fahrzeugmasse 500;
BA_REL_ "GenSigTimeoutTime" BU_SG_REL_ GW_Routing_Derivate SG_ 273 TSK_QBit_Fahrzeugmasse 500;
BA_REL_ "GenSigTimeoutTime" BU_SG_REL_ GW_Routing_Derivate SG_ 273 TSK_Steigung 500;
BA_REL_ "GenSigTimeoutTime" BU_SG_REL_ GW_Routing_Derivate SG_ 273 TSK_Getriebeinfo 500;
BA_REL_ "GenSigTimeoutTime" BU_SG_REL_ GW_Routing_Derivate SG_ 273 TSK_Codierung_ACC 500;
BA_REL_ "GenSigTimeoutTime" BU_SG_REL_ GW_Routing_Derivate SG_ 273 TSK_Zwangszusch_ESP 500;
BA_REL_ "GenSigTimeoutTime" BU_SG_REL_ GW_Routing_Derivate SG_ 273 TSK_Freig_Verzoeg_Anf 500;
BA_REL_ "GenSigTimeoutTime" BU_SG_REL_ GW_Routing_Derivate SG_ 273 TSK_Verzoeg_Anf_02 500;
BA_REL_ "GenSigTimeoutTime" BU_SG_REL_ GW_Routing_Derivate SG_ 915 GE_Tipschaltempf_verfuegbar 800;
BA_REL_ "GenSigTimeoutTime" BU_SG_REL_ GW_Routing_Derivate SG_ 915 GE_Sollgang 800;
BA_REL_ "GenSigTimeoutTime" BU_SG_REL_ GW_Routing_Derivate SG_ 915 WBA_GE_Zusatzwarnungen 800;
BA_REL_ "GenSigTimeoutTime" BU_SG_REL_ GW_Routing_Derivate SG_ 915 WBA_Effizienzmodus 800;
BA_REL_ "GenSigTimeoutTime" BU_SG_REL_ GW_Routing_Derivate SG_ 915 WBA_Sollgang 800;
BA_REL_ "GenSigTimeoutTime" BU_SG_REL_ GW_Routing_Derivate SG_ 915 WBA_02_BZ 800;
BA_REL_ "GenSigTimeoutTime" BU_SG_REL_ GW_Routing_Derivate SG_ 915 WBA_Senderkennung 800;
BA_REL_ "GenSigTimeoutTime" BU_SG_REL_ GW_Routing_Derivate SG_ 915 WBA_Lampe_Shift_Lock 800;
BA_REL_ "GenSigTimeoutTime" BU_SG_REL_ GW_Routing_Derivate SG_ 915 WBA_Blinken 800;
BA_REL_ "GenSigTimeoutTime" BU_SG_REL_ GW_Routing_Derivate SG_ 915 WBA_Getriebevariante 800;
BA_REL_ "GenSigTimeoutTime" BU_SG_REL_ GW_Routing_Derivate SG_ 915 WBA_GE_Warnung 800;
BA_REL_ "GenSigTimeoutTime" BU_SG_REL_ GW_Routing_Derivate SG_ 915 WBA_Fahrstufe 800;
BA_REL_ "GenSigTimeoutTime" BU_SG_REL_ GW_Routing_Derivate SG_ 915 WBA_Schaltempf_verfbar 800;
BA_REL_ "GenSigTimeoutTime" BU_SG_REL_ GW_Routing_Derivate SG_ 915 WBA_eing_Gang 800;
BA_REL_ "GenSigTimeoutTime" BU_SG_REL_ GW_Routing_Derivate SG_ 915 WBA_Istgang 800;
BA_REL_ "GenSigTimeoutTime" BU_SG_REL_ GW_Routing_Derivate SG_ 915 WBA_GE_Texte 800;
BA_REL_ "GenSigTimeoutTime" BU_SG_REL_ GW_Routing_Derivate SG_ 915 WBA_Schaltschema_Aktiv 800;
BA_REL_ "GenSigTimeoutTime" BU_SG_REL_ GW_Routing_Derivate SG_ 915 WH_Warnung 800;
BA_REL_ "GenSigTimeoutTime" BU_SG_REL_ GW_Routing_Derivate SG_ 915 WBA_02_CHK 800;
BA_REL_ "GenSigTimeoutTime" BU_SG_REL_ GW_Routing_Derivate SG_ 1602 WIV_Verschleissindex 5000;
BA_REL_ "GenSigTimeoutTime" BU_SG_REL_ GW_Routing_Derivate SG_ 1602 WIV_Russindex 5000;
BA_REL_ "GenSigTimeoutTime" BU_SG_REL_ GW_Routing_Derivate SG_ 1602 WIV_t_min 5000;
BA_REL_ "GenSigTimeoutTime" BU_SG_REL_ GW_Routing_Derivate SG_ 1602 WIV_t_max 5000;
BA_REL_ "GenSigTimeoutTime" BU_SG_REL_ GW_Routing_Derivate SG_ 1602 WIV_W_min 5000;
BA_REL_ "GenSigTimeoutTime" BU_SG_REL_ GW_Routing_Derivate SG_ 1602 WIV_W_max 5000;
BA_REL_ "GenSigTimeoutTime" BU_SG_REL_ BMS_Hybrid SG_ 1646 KL_Innen_Temp 5000;
BA_REL_ "GenSigTimeoutTime" BU_SG_REL_ BMS_Hybrid SG_ 1646 KL_AussenTemp_WK 5000;
BA_REL_ "GenSigTimeoutTime" BU_SG_REL_ BMS_Hybrid SG_ 1636 KL_Umluftklappe_Status 5000;
BA_REL_ "GenSigTimeoutTime" BU_SG_REL_ BMS_Hybrid SG_ 1636 KL_Geblaese_Status 5000;
BA_REL_ "GenSigTimeoutTime" BU_SG_REL_ Motor_EDC17_Pirol SG_ 959 KL_Vorwarn_Komp_ein 1000;
BA_REL_ "GenSigTimeoutTime" BU_SG_REL_ Motor_MED17_Hybrid SG_ 959 KL_Vorwarn_Komp_ein 1000;
BA_REL_ "GenSigTimeoutTime" BU_SG_REL_ BMS_Hybrid SG_ 959 KL_Zustand 1000;
BA_REL_ "GenSigTimeoutTime" BU_SG_REL_ Motor_EDC17_Pirol SG_ 959 KL_Zustand 1000;
BA_REL_ "GenSigTimeoutTime" BU_SG_REL_ Motor_MED17_Hybrid SG_ 959 KL_Zustand 1000;
BA_REL_ "GenSigTimeoutTime" BU_SG_REL_ Motor_EDC17_Pirol SG_ 959 KL_4_Zonen 1000;
BA_REL_ "GenSigTimeoutTime" BU_SG_REL_ Motor_MED17_Hybrid SG_ 959 KL_4_Zonen 1000;
BA_REL_ "GenSigTimeoutTime" BU_SG_REL_ Motor_EDC17_Pirol SG_ 959 KL_Thermomanagement 1000;
BA_REL_ "GenSigTimeoutTime" BU_SG_REL_ Motor_MED17_Hybrid SG_ 959 KL_Thermomanagement 1000;
BA_REL_ "GenSigTimeoutTime" BU_SG_REL_ Motor_EDC17_Pirol SG_ 959 KL_Vorwarn_HHS_ein 1000;
BA_REL_ "GenSigTimeoutTime" BU_SG_REL_ Motor_MED17_Hybrid SG_ 959 KL_Vorwarn_HHS_ein 1000;
BA_REL_ "GenSigTimeoutTime" BU_SG_REL_ Motor_EDC17_Pirol SG_ 959 KL_Vorwarn_HFS_ein 1000;
BA_REL_ "GenSigTimeoutTime" BU_SG_REL_ Motor_MED17_Hybrid SG_ 959 KL_Vorwarn_HFS_ein 1000;
BA_REL_ "GenSigTimeoutTime" BU_SG_REL_ Motor_EDC17_Pirol SG_ 959 KL_StartStopp_Info 1000;
BA_REL_ "GenSigTimeoutTime" BU_SG_REL_ Motor_MED17_Hybrid SG_ 959 KL_StartStopp_Info 1000;
BA_REL_ "GenSigTimeoutTime" BU_SG_REL_ Motor_EDC17_Pirol SG_ 959 KL_Drehz_Anh 1000;
BA_REL_ "GenSigTimeoutTime" BU_SG_REL_ Motor_MED17_Hybrid SG_ 959 KL_Drehz_Anh 1000;
BA_REL_ "GenSigTimeoutTime" BU_SG_REL_ Motor_EDC17_Pirol SG_ 959 KL_Anf_KL 1000;
BA_REL_ "GenSigTimeoutTime" BU_SG_REL_ Motor_MED17_Hybrid SG_ 959 KL_Anf_KL 1000;
BA_REL_ "GenSigTimeoutTime" BU_SG_REL_ Motor_EDC17_Pirol SG_ 959 KL_Last_Kompr 1000;
BA_REL_ "GenSigTimeoutTime" BU_SG_REL_ GW_Routing_Derivate SG_ 2041 Response_Airbag_Deployment 500;
BA_REL_ "GenSigTimeoutTime" BU_SG_REL_ Airbag SG_ 2033 Request_Airbag_Deployment 500;
BA_REL_ "GenSigTimeoutTime" BU_SG_REL_ Motor_MED17_Hybrid SG_ 1413 SI_QRS_Mode 5000;
BA_REL_ "GenSigTimeoutTime" BU_SG_REL_ Motor_EDC17_Pirol SG_ 1413 SI_QRS_Mode 5000;
BA_REL_ "GenSigTimeoutTime" BU_SG_REL_ Motor_EDC17_Pirol SG_ 1413 SI_T_Mode 5000;
BA_REL_ "GenSigTimeoutTime" BU_SG_REL_ Motor_MED17_Hybrid SG_ 1413 SI_T_Mode 5000;
BA_REL_ "GenSigTimeoutTime" BU_SG_REL_ Airbag SG_ 1413 SI_T_Mode 5000;
BA_REL_ "GenSigTimeoutTime" BU_SG_REL_ Motor_MED17_Hybrid SG_ 2616986624 CCP_MO_CRO_02_Data 500;
BA_REL_ "GenSigTimeoutTime" BU_SG_REL_ Motor_EDC17_Pirol SG_ 2616986624 CCP_MO_CRO_02_Data 500;
BA_REL_ "GenSigTimeoutTime" BU_SG_REL_ Motor_MED17_Hybrid SG_ 480 CCP_MO_CRO_01_Data 500;
BA_REL_ "GenSigTimeoutTime" BU_SG_REL_ Motor_EDC17_Pirol SG_ 480 CCP_MO_CRO_01_Data 500;
BA_REL_ "GenSigTimeoutTime" BU_SG_REL_ GW_Routing_Derivate SG_ 24 WFS_MSG4_IMS 500;
BA_REL_ "GenSigTimeoutTime" BU_SG_REL_ LEH_Hybrid SG_ 25 WFS_IMS_MSG4 500;
BA_REL_ "GenSigTimeoutTime" BU_SG_REL_ Motor_EDC17_Pirol SG_ 1603 KBI_Einheit_Streckenanz 5000;
BA_REL_ "GenSigTimeoutTime" BU_SG_REL_ Getriebe_Derivate SG_ 267 MFL_Tip_Up 1000;
BA_REL_ "GenSigTimeoutTime" BU_SG_REL_ Getriebe_Derivate SG_ 267 MFL_Tip_Down 1000;
BA_REL_ "GenSigTimeoutTime" BU_SG_REL_ Motor_EDC17_Pirol SG_ 267 LS_Typ_Hauptschalter 1000;
BA_REL_ "GenSigTimeoutTime" BU_SG_REL_ Motor_MED17_Hybrid SG_ 267 LS_Typ_Hauptschalter 1000;
BA_REL_ "GenSigTimeoutTime" BU_SG_REL_ Getriebe_Derivate SG_ 267 LS_Tiptronic_Fehler 1000;
BA_REL_ "GenSigTimeoutTime" BU_SG_REL_ Motor_EDC17_Pirol SG_ 267 LS_Tip_Wiederaufnahme 1000;
BA_REL_ "GenSigTimeoutTime" BU_SG_REL_ Motor_MED17_Hybrid SG_ 267 LS_Tip_Wiederaufnahme 1000;
BA_REL_ "GenSigTimeoutTime" BU_SG_REL_ Motor_EDC17_Pirol SG_ 267 LS_Tip_Setzen 1000;
BA_REL_ "GenSigTimeoutTime" BU_SG_REL_ Motor_MED17_Hybrid SG_ 267 LS_Tip_Setzen 1000;
BA_REL_ "GenSigTimeoutTime" BU_SG_REL_ Motor_EDC17_Pirol SG_ 267 LS_Tip_Runter 1000;
BA_REL_ "GenSigTimeoutTime" BU_SG_REL_ Motor_MED17_Hybrid SG_ 267 LS_Tip_Runter 1000;
BA_REL_ "GenSigTimeoutTime" BU_SG_REL_ Motor_EDC17_Pirol SG_ 267 LS_Tip_Hoch 1000;
BA_REL_ "GenSigTimeoutTime" BU_SG_REL_ Motor_MED17_Hybrid SG_ 267 LS_Tip_Hoch 1000;
BA_REL_ "GenSigTimeoutTime" BU_SG_REL_ Motor_EDC17_Pirol SG_ 267 LS_Limiter 1000;
BA_REL_ "GenSigTimeoutTime" BU_SG_REL_ Motor_MED17_Hybrid SG_ 267 LS_Limiter 1000;
BA_REL_ "GenSigTimeoutTime" BU_SG_REL_ Motor_EDC17_Pirol SG_ 267 LS_Hauptschalter 1000;
BA_REL_ "GenSigTimeoutTime" BU_SG_REL_ Motor_MED17_Hybrid SG_ 267 LS_Hauptschalter 1000;
BA_REL_ "GenSigTimeoutTime" BU_SG_REL_ Motor_EDC17_Pirol SG_ 267 LS_Fehler 1000;
BA_REL_ "GenSigTimeoutTime" BU_SG_REL_ Motor_MED17_Hybrid SG_ 267 LS_Fehler 1000;
BA_REL_ "GenSigTimeoutTime" BU_SG_REL_ Motor_EDC17_Pirol SG_ 267 LS_Codierung 1000;
BA_REL_ "GenSigTimeoutTime" BU_SG_REL_ Motor_MED17_Hybrid SG_ 267 LS_Codierung 1000;
BA_REL_ "GenSigTimeoutTime" BU_SG_REL_ Motor_EDC17_Pirol SG_ 267 LS_Abbrechen 1000;
BA_REL_ "GenSigTimeoutTime" BU_SG_REL_ Motor_MED17_Hybrid SG_ 267 LS_Abbrechen 1000;
BA_REL_ "GenSigTimeoutTime" BU_SG_REL_ Motor_EDC17_Pirol SG_ 267 LS_01_CHK 1000;
BA_REL_ "GenSigTimeoutTime" BU_SG_REL_ Motor_MED17_Hybrid SG_ 267 LS_01_CHK 1000;
BA_REL_ "GenSigTimeoutTime" BU_SG_REL_ Getriebe_Derivate SG_ 267 LS_01_CHK 1000;
BA_REL_ "GenSigTimeoutTime" BU_SG_REL_ Motor_EDC17_Pirol SG_ 267 LS_01_BZ 1000;
BA_REL_ "GenSigTimeoutTime" BU_SG_REL_ Motor_MED17_Hybrid SG_ 267 LS_01_BZ 1000;
BA_REL_ "GenSigTimeoutTime" BU_SG_REL_ Getriebe_Derivate SG_ 267 LS_01_BZ 1000;
BA_REL_ "GenSigTimeoutTime" BU_SG_REL_ Getriebe_Derivate SG_ 267 MFL_M_Taste 1000;
BA_REL_ "GenSigTimeoutTime" BU_SG_REL_ Motor_EDC17_Pirol SG_ 267 LS_Tip_Stufe_2 1000;
BA_REL_ "GenSigTimeoutTime" BU_SG_REL_ Motor_MED17_Hybrid SG_ 267 LS_Tip_Stufe_2 1000;
BA_REL_ "GenSigTimeoutTime" BU_SG_REL_ Motor_EDC17_Pirol SG_ 267 LS_GRA_ACC_2stufig 1000;
BA_REL_ "GenSigTimeoutTime" BU_SG_REL_ Motor_MED17_Hybrid SG_ 267 LS_GRA_ACC_2stufig 1000;
BA_REL_ "GenSigTimeoutTime" BU_SG_REL_ Motor_EDC17_Pirol SG_ 260 EPB_Pedalweg_Kuppl 500;
BA_REL_ "GenSigTimeoutTime" BU_SG_REL_ Motor_MED17_Hybrid SG_ 260 EPB_Pedalweg_Kuppl 500;
BA_REL_ "GenSigTimeoutTime" BU_SG_REL_ Motor_MED17_Hybrid SG_ 260 EPB_Fehlerstatus 500;
BA_REL_ "GenSigTimeoutTime" BU_SG_REL_ Motor_EDC17_Pirol SG_ 260 EPB_Schalterposition 500;
BA_REL_ "GenSigTimeoutTime" BU_SG_REL_ Motor_MED17_Hybrid SG_ 260 EPB_Schalterposition 500;
BA_REL_ "GenSigTimeoutTime" BU_SG_REL_ Motor_EDC17_Pirol SG_ 260 EPB_QBit_Schalterpos 500;
BA_REL_ "GenSigTimeoutTime" BU_SG_REL_ Motor_MED17_Hybrid SG_ 260 EPB_QBit_Schalterpos 500;
BA_REL_ "GenSigTimeoutTime" BU_SG_REL_ Motor_EDC17_Pirol SG_ 260 EPB_Status 500;
BA_REL_ "GenSigTimeoutTime" BU_SG_REL_ Getriebe_Derivate SG_ 260 EPB_Status 500;
BA_REL_ "GenSigTimeoutTime" BU_SG_REL_ Motor_MED17_Hybrid SG_ 260 EPB_Status 500;
BA_REL_ "GenSigTimeoutTime" BU_SG_REL_ Getriebe_Derivate SG_ 260 EPB_01_CHK 500;
BA_REL_ "GenSigTimeoutTime" BU_SG_REL_ Motor_EDC17_Pirol SG_ 260 EPB_01_CHK 500;
BA_REL_ "GenSigTimeoutTime" BU_SG_REL_ Motor_MED17_Hybrid SG_ 260 EPB_01_CHK 500;
BA_REL_ "GenSigTimeoutTime" BU_SG_REL_ Getriebe_Derivate SG_ 260 EPB_01_BZ 500;
BA_REL_ "GenSigTimeoutTime" BU_SG_REL_ Motor_EDC17_Pirol SG_ 260 EPB_01_BZ 500;
BA_REL_ "GenSigTimeoutTime" BU_SG_REL_ Motor_MED17_Hybrid SG_ 260 EPB_01_BZ 500;
BA_REL_ "GenSigTimeoutTime" BU_SG_REL_ Motor_EDC17_Pirol SG_ 260 EPB_QBit_Pedalweg_Kuppl 500;
BA_REL_ "GenSigTimeoutTime" BU_SG_REL_ Motor_MED17_Hybrid SG_ 260 EPB_QBit_Pedalweg_Kuppl 500;
BA_REL_ "GenSigTimeoutTime" BU_SG_REL_ Motor_EDC17_Pirol SG_ 260 EPB_Freig_Verzoeg_Anf 500;
BA_REL_ "GenSigTimeoutTime" BU_SG_REL_ Motor_MED17_Hybrid SG_ 260 EPB_Freig_Verzoeg_Anf 500;
BA_REL_ "GenSigTimeoutTime" BU_SG_REL_ GW_Routing_Derivate SG_ 64 AB_Deaktivierung_HV 500;
BA_REL_ "GenSigTimeoutTime" BU_SG_REL_ GW_Routing_Derivate SG_ 64 AB_RGS_Anst 500;
BA_REL_ "GenSigTimeoutTime" BU_SG_REL_ GW_Routing_Derivate SG_ 64 AB_Texte_AKS 500;
BA_REL_ "GenSigTimeoutTime" BU_SG_REL_ GW_Routing_Derivate SG_ 64 Airbag_01_CHK 500;
BA_REL_ "GenSigTimeoutTime" BU_SG_REL_ Motor_EDC17_Pirol SG_ 64 Airbag_01_CHK 500;
BA_REL_ "GenSigTimeoutTime" BU_SG_REL_ Getriebe_Derivate SG_ 64 Airbag_01_CHK 500;
BA_REL_ "GenSigTimeoutTime" BU_SG_REL_ Motor_MED17_Hybrid SG_ 64 Airbag_01_CHK 500;
BA_REL_ "GenSigTimeoutTime" BU_SG_REL_ LEH_Hybrid SG_ 64 Airbag_01_CHK 500;
BA_REL_ "GenSigTimeoutTime" BU_SG_REL_ BMS_Hybrid SG_ 64 Airbag_01_CHK 500;
BA_REL_ "GenSigTimeoutTime" BU_SG_REL_ GW_Routing_Derivate SG_ 64 Airbag_01_BZ 500;
BA_REL_ "GenSigTimeoutTime" BU_SG_REL_ Motor_EDC17_Pirol SG_ 64 Airbag_01_BZ 500;
BA_REL_ "GenSigTimeoutTime" BU_SG_REL_ Getriebe_Derivate SG_ 64 Airbag_01_BZ 500;
BA_REL_ "GenSigTimeoutTime" BU_SG_REL_ Motor_MED17_Hybrid SG_ 64 Airbag_01_BZ 500;
BA_REL_ "GenSigTimeoutTime" BU_SG_REL_ LEH_Hybrid SG_ 64 Airbag_01_BZ 500;
BA_REL_ "GenSigTimeoutTime" BU_SG_REL_ BMS_Hybrid SG_ 64 Airbag_01_BZ 500;
BA_REL_ "GenSigTimeoutTime" BU_SG_REL_ GW_Routing_Derivate SG_ 64 AB_Front_Crash 500;
BA_REL_ "GenSigTimeoutTime" BU_SG_REL_ GW_Applikation_Derivate SG_ 64 AB_Front_Crash 500;
BA_REL_ "GenSigTimeoutTime" BU_SG_REL_ GW_Routing_Derivate SG_ 64 AB_Heck_Crash 500;
BA_REL_ "GenSigTimeoutTime" BU_SG_REL_ GW_Applikation_Derivate SG_ 64 AB_Heck_Crash 500;
BA_REL_ "GenSigTimeoutTime" BU_SG_REL_ GW_Routing_Derivate SG_ 64 AB_SF_Crash 500;
BA_REL_ "GenSigTimeoutTime" BU_SG_REL_ GW_Applikation_Derivate SG_ 64 AB_SF_Crash 500;
BA_REL_ "GenSigTimeoutTime" BU_SG_REL_ GW_Routing_Derivate SG_ 64 AB_SB_Crash 500;
BA_REL_ "GenSigTimeoutTime" BU_SG_REL_ GW_Applikation_Derivate SG_ 64 AB_SB_Crash 500;
BA_REL_ "GenSigTimeoutTime" BU_SG_REL_ GW_Routing_Derivate SG_ 64 AB_Rollover_Crash 500;
BA_REL_ "GenSigTimeoutTime" BU_SG_REL_ GW_Applikation_Derivate SG_ 64 AB_Rollover_Crash 500;
BA_REL_ "GenSigTimeoutTime" BU_SG_REL_ GW_Routing_Derivate SG_ 64 AB_Crash_Int 500;
BA_REL_ "GenSigTimeoutTime" BU_SG_REL_ Motor_EDC17_Pirol SG_ 64 AB_Crash_Int 500;
BA_REL_ "GenSigTimeoutTime" BU_SG_REL_ Getriebe_Derivate SG_ 64 AB_Crash_Int 500;
BA_REL_ "GenSigTimeoutTime" BU_SG_REL_ Motor_MED17_Hybrid SG_ 64 AB_Crash_Int 500;
BA_REL_ "GenSigTimeoutTime" BU_SG_REL_ LEH_Hybrid SG_ 64 AB_Crash_Int 500;
BA_REL_ "GenSigTimeoutTime" BU_SG_REL_ BMS_Hybrid SG_ 64 AB_Crash_Int 500;
BA_REL_ "GenSigTimeoutTime" BU_SG_REL_ GW_Routing_Derivate SG_ 64 AB_Lampe 500;
BA_REL_ "GenSigTimeoutTime" BU_SG_REL_ GW_Routing_Derivate SG_ 64 AB_Deaktiviert 500;
BA_REL_ "GenSigTimeoutTime" BU_SG_REL_ GW_Routing_Derivate SG_ 64 AB_VB_deaktiviert 500;
BA_REL_ "GenSigTimeoutTime" BU_SG_REL_ GW_Routing_Derivate SG_ 64 AB_Systemfehler 500;
BA_REL_ "GenSigTimeoutTime" BU_SG_REL_ LEH_Hybrid SG_ 64 AB_Systemfehler 500;
BA_REL_ "GenSigTimeoutTime" BU_SG_REL_ BMS_Hybrid SG_ 64 AB_Systemfehler 500;
BA_REL_ "GenSigTimeoutTime" BU_SG_REL_ GW_Routing_Derivate SG_ 64 AB_Diagnose 500;
BA_REL_ "GenSigTimeoutTime" BU_SG_REL_ LEH_Hybrid SG_ 64 AB_Stellgliedtest 500;
BA_REL_ "GenSigTimeoutTime" BU_SG_REL_ GW_Routing_Derivate SG_ 64 AB_Stellgliedtest 500;
BA_REL_ "GenSigTimeoutTime" BU_SG_REL_ Motor_EDC17_Pirol SG_ 64 AB_Stellgliedtest 500;
BA_REL_ "GenSigTimeoutTime" BU_SG_REL_ BMS_Hybrid SG_ 64 AB_Stellgliedtest 500;
BA_REL_ "GenSigTimeoutTime" BU_SG_REL_ Motor_MED17_Hybrid SG_ 64 AB_Stellgliedtest 500;
BA_REL_ "GenSigTimeoutTime" BU_SG_REL_ GW_Routing_Derivate SG_ 64 AB_Erh_Auf_VB 500;
BA_REL_ "GenSigTimeoutTime" BU_SG_REL_ GW_Routing_Derivate SG_ 64 AB_Gurtwarn_VF 500;
BA_REL_ "GenSigTimeoutTime" BU_SG_REL_ GW_Routing_Derivate SG_ 64 AB_Gurtwarn_VB 500;
BA_REL_ "GenSigTimeoutTime" BU_SG_REL_ GW_Routing_Derivate SG_ 64 AB_Anzeige_Fussg 500;
BA_REL_ "GenSigTimeoutTime" BU_SG_REL_ GW_Routing_Derivate SG_ 64 AB_PAO_Leuchte_Anf 500;
BA_REL_ "GenSigTimeoutTime" BU_SG_REL_ GW_Routing_Derivate SG_ 64 void_Byte_02 500;
BA_REL_ "GenSigTimeoutTime" BU_SG_REL_ GW_Routing_Derivate SG_ 64 void_Byte_03 500;
BA_REL_ "GenSigTimeoutTime" BU_SG_REL_ GW_Routing_Derivate SG_ 64 AB_KD_Fehler 500;
BA_REL_ "GenSigTimeoutTime" BU_SG_REL_ GW_Applikation_Derivate SG_ 64 AB_KD_Fehler 500;
BA_REL_ "GenSigTimeoutTime" BU_SG_REL_ GW_Routing_Derivate SG_ 1312 AB_Gurtschloss_FA 2000;
BA_REL_ "GenSigTimeoutTime" BU_SG_REL_ Motor_EDC17_Pirol SG_ 1312 AB_Gurtschloss_FA 2000;
BA_REL_ "GenSigTimeoutTime" BU_SG_REL_ Motor_MED17_Hybrid SG_ 1312 AB_Gurtschloss_FA 2000;
BA_REL_ "GenSigTimeoutTime" BU_SG_REL_ Motor_EDC17_Pirol SG_ 777 BEM_01_CHK 500;
BA_REL_ "GenSigTimeoutTime" BU_SG_REL_ Motor_MED17_Hybrid SG_ 777 BEM_01_CHK 500;
BA_REL_ "GenSigTimeoutTime" BU_SG_REL_ Motor_EDC17_Pirol SG_ 777 BEM_01_BZ 500;
BA_REL_ "GenSigTimeoutTime" BU_SG_REL_ Motor_MED17_Hybrid SG_ 777 BEM_01_BZ 500;
BA_REL_ "GenSigTimeoutTime" BU_SG_REL_ Motor_EDC17_Pirol SG_ 777 BEM_P_Generator 500;
BA_REL_ "GenSigTimeoutTime" BU_SG_REL_ Motor_EDC17_Pirol SG_ 777 BEM_n_LLA 500;
BA_REL_ "GenSigTimeoutTime" BU_SG_REL_ Motor_EDC17_Pirol SG_ 777 BEM_Anf_KL 500;
BA_REL_ "GenSigTimeoutTime" BU_SG_REL_ Motor_MED17_Hybrid SG_ 777 BEM_Anf_KL 500;
BA_REL_ "GenSigTimeoutTime" BU_SG_REL_ Motor_EDC17_Pirol SG_ 777 BEM_StartStopp_Info 500;
BA_REL_ "GenSigTimeoutTime" BU_SG_REL_ Motor_MED17_Hybrid SG_ 777 BEM_StartStopp_Info 500;
BA_REL_ "GenSigTimeoutTime" BU_SG_REL_ Ladegeraet_PAG_PF SG_ 1714 UH_Jahr 5000;
BA_REL_ "GenSigTimeoutTime" BU_SG_REL_ Motor_EDC17_Pirol SG_ 1714 UH_Jahr 5000;
BA_REL_ "GenSigTimeoutTime" BU_SG_REL_ PSM_Ant_Derivate SG_ 1714 UH_Jahr 5000;
BA_REL_ "GenSigTimeoutTime" BU_SG_REL_ Waehlhebel SG_ 1714 UH_Jahr 5000;
BA_REL_ "GenSigTimeoutTime" BU_SG_REL_ Motor_MED17_Hybrid SG_ 1714 UH_Jahr 5000;
BA_REL_ "GenSigTimeoutTime" BU_SG_REL_ LEH_Hybrid SG_ 1714 UH_Jahr 5000;
BA_REL_ "GenSigTimeoutTime" BU_SG_REL_ Getriebe_Derivate SG_ 1714 UH_Jahr 5000;
BA_REL_ "GenSigTimeoutTime" BU_SG_REL_ BMS_Hybrid SG_ 1714 UH_Jahr 5000;
BA_REL_ "GenSigTimeoutTime" BU_SG_REL_ Airbag SG_ 1714 UH_Jahr 5000;
BA_REL_ "GenSigTimeoutTime" BU_SG_REL_ Ladegeraet_PAG_PF SG_ 1714 UH_Monat 5000;
BA_REL_ "GenSigTimeoutTime" BU_SG_REL_ Motor_EDC17_Pirol SG_ 1714 UH_Monat 5000;
BA_REL_ "GenSigTimeoutTime" BU_SG_REL_ PSM_Ant_Derivate SG_ 1714 UH_Monat 5000;
BA_REL_ "GenSigTimeoutTime" BU_SG_REL_ Waehlhebel SG_ 1714 UH_Monat 5000;
BA_REL_ "GenSigTimeoutTime" BU_SG_REL_ Getriebe_Derivate SG_ 1714 UH_Monat 5000;
BA_REL_ "GenSigTimeoutTime" BU_SG_REL_ Motor_MED17_Hybrid SG_ 1714 UH_Monat 5000;
BA_REL_ "GenSigTimeoutTime" BU_SG_REL_ LEH_Hybrid SG_ 1714 UH_Monat 5000;
BA_REL_ "GenSigTimeoutTime" BU_SG_REL_ BMS_Hybrid SG_ 1714 UH_Monat 5000;
BA_REL_ "GenSigTimeoutTime" BU_SG_REL_ Airbag SG_ 1714 UH_Monat 5000;
BA_REL_ "GenSigTimeoutTime" BU_SG_REL_ Ladegeraet_PAG_PF SG_ 1714 UH_Tag 5000;
BA_REL_ "GenSigTimeoutTime" BU_SG_REL_ Motor_EDC17_Pirol SG_ 1714 UH_Tag 5000;
BA_REL_ "GenSigTimeoutTime" BU_SG_REL_ PSM_Ant_Derivate SG_ 1714 UH_Tag 5000;
BA_REL_ "GenSigTimeoutTime" BU_SG_REL_ Waehlhebel SG_ 1714 UH_Tag 5000;
BA_REL_ "GenSigTimeoutTime" BU_SG_REL_ Getriebe_Derivate SG_ 1714 UH_Tag 5000;
BA_REL_ "GenSigTimeoutTime" BU_SG_REL_ Motor_MED17_Hybrid SG_ 1714 UH_Tag 5000;
BA_REL_ "GenSigTimeoutTime" BU_SG_REL_ LEH_Hybrid SG_ 1714 UH_Tag 5000;
BA_REL_ "GenSigTimeoutTime" BU_SG_REL_ BMS_Hybrid SG_ 1714 UH_Tag 5000;
BA_REL_ "GenSigTimeoutTime" BU_SG_REL_ Airbag SG_ 1714 UH_Tag 5000;
BA_REL_ "GenSigTimeoutTime" BU_SG_REL_ Ladegeraet_PAG_PF SG_ 1714 UH_Stunde 5000;
BA_REL_ "GenSigTimeoutTime" BU_SG_REL_ Motor_EDC17_Pirol SG_ 1714 UH_Stunde 5000;
BA_REL_ "GenSigTimeoutTime" BU_SG_REL_ PSM_Ant_Derivate SG_ 1714 UH_Stunde 5000;
BA_REL_ "GenSigTimeoutTime" BU_SG_REL_ Waehlhebel SG_ 1714 UH_Stunde 5000;
BA_REL_ "GenSigTimeoutTime" BU_SG_REL_ Getriebe_Derivate SG_ 1714 UH_Stunde 5000;
BA_REL_ "GenSigTimeoutTime" BU_SG_REL_ Motor_MED17_Hybrid SG_ 1714 UH_Stunde 5000;
BA_REL_ "GenSigTimeoutTime" BU_SG_REL_ LEH_Hybrid SG_ 1714 UH_Stunde 5000;
BA_REL_ "GenSigTimeoutTime" BU_SG_REL_ BMS_Hybrid SG_ 1714 UH_Stunde 5000;
BA_REL_ "GenSigTimeoutTime" BU_SG_REL_ Airbag SG_ 1714 UH_Stunde 5000;
BA_REL_ "GenSigTimeoutTime" BU_SG_REL_ Ladegeraet_PAG_PF SG_ 1714 UH_Minute 5000;
BA_REL_ "GenSigTimeoutTime" BU_SG_REL_ Motor_EDC17_Pirol SG_ 1714 UH_Minute 5000;
BA_REL_ "GenSigTimeoutTime" BU_SG_REL_ PSM_Ant_Derivate SG_ 1714 UH_Minute 5000;
BA_REL_ "GenSigTimeoutTime" BU_SG_REL_ Waehlhebel SG_ 1714 UH_Minute 5000;
BA_REL_ "GenSigTimeoutTime" BU_SG_REL_ Getriebe_Derivate SG_ 1714 UH_Minute 5000;
BA_REL_ "GenSigTimeoutTime" BU_SG_REL_ Motor_MED17_Hybrid SG_ 1714 UH_Minute 5000;
BA_REL_ "GenSigTimeoutTime" BU_SG_REL_ LEH_Hybrid SG_ 1714 UH_Minute 5000;
BA_REL_ "GenSigTimeoutTime" BU_SG_REL_ BMS_Hybrid SG_ 1714 UH_Minute 5000;
BA_REL_ "GenSigTimeoutTime" BU_SG_REL_ Airbag SG_ 1714 UH_Minute 5000;
BA_REL_ "GenSigTimeoutTime" BU_SG_REL_ Airbag SG_ 1714 Kombi_02_alt 5000;
BA_REL_ "GenSigTimeoutTime" BU_SG_REL_ BMS_Hybrid SG_ 1714 Kombi_02_alt 5000;
BA_REL_ "GenSigTimeoutTime" BU_SG_REL_ LEH_Hybrid SG_ 1714 Kombi_02_alt 5000;
BA_REL_ "GenSigTimeoutTime" BU_SG_REL_ Waehlhebel SG_ 1714 Kombi_02_alt 5000;
BA_REL_ "GenSigTimeoutTime" BU_SG_REL_ Ladegeraet_PAG_PF SG_ 1714 UH_Sekunde 5000;
BA_REL_ "GenSigTimeoutTime" BU_SG_REL_ Motor_EDC17_Pirol SG_ 1714 UH_Sekunde 5000;
BA_REL_ "GenSigTimeoutTime" BU_SG_REL_ PSM_Ant_Derivate SG_ 1714 UH_Sekunde 5000;
BA_REL_ "GenSigTimeoutTime" BU_SG_REL_ Waehlhebel SG_ 1714 UH_Sekunde 5000;
BA_REL_ "GenSigTimeoutTime" BU_SG_REL_ Getriebe_Derivate SG_ 1714 UH_Sekunde 5000;
BA_REL_ "GenSigTimeoutTime" BU_SG_REL_ Motor_MED17_Hybrid SG_ 1714 UH_Sekunde 5000;
BA_REL_ "GenSigTimeoutTime" BU_SG_REL_ LEH_Hybrid SG_ 1714 UH_Sekunde 5000;
BA_REL_ "GenSigTimeoutTime" BU_SG_REL_ BMS_Hybrid SG_ 1714 UH_Sekunde 5000;
BA_REL_ "GenSigTimeoutTime" BU_SG_REL_ Airbag SG_ 1714 UH_Sekunde 5000;
BA_REL_ "GenSigTimeoutTime" BU_SG_REL_ Ladegeraet_PAG_PF SG_ 1714 DGN_Verlernzaehler 5000;
BA_REL_ "GenSigTimeoutTime" BU_SG_REL_ Waehlhebel SG_ 1714 DGN_Verlernzaehler 5000;
BA_REL_ "GenSigTimeoutTime" BU_SG_REL_ LEH_Hybrid SG_ 1714 DGN_Verlernzaehler 5000;
BA_REL_ "GenSigTimeoutTime" BU_SG_REL_ BMS_Hybrid SG_ 1714 DGN_Verlernzaehler 5000;
BA_REL_ "GenSigTimeoutTime" BU_SG_REL_ Airbag SG_ 1714 DGN_Verlernzaehler 5000;
BA_REL_ "GenSigTimeoutTime" BU_SG_REL_ Ladegeraet_PAG_PF SG_ 1714 KBI_Kilometerstand 5000;
BA_REL_ "GenSigTimeoutTime" BU_SG_REL_ Motor_EDC17_Pirol SG_ 1714 KBI_Kilometerstand 5000;
BA_REL_ "GenSigTimeoutTime" BU_SG_REL_ PSM_Ant_Derivate SG_ 1714 KBI_Kilometerstand 5000;
BA_REL_ "GenSigTimeoutTime" BU_SG_REL_ Waehlhebel SG_ 1714 KBI_Kilometerstand 5000;
BA_REL_ "GenSigTimeoutTime" BU_SG_REL_ Motor_MED17_Hybrid SG_ 1714 KBI_Kilometerstand 5000;
BA_REL_ "GenSigTimeoutTime" BU_SG_REL_ LEH_Hybrid SG_ 1714 KBI_Kilometerstand 5000;
BA_REL_ "GenSigTimeoutTime" BU_SG_REL_ BMS_Hybrid SG_ 1714 KBI_Kilometerstand 5000;
BA_REL_ "GenSigTimeoutTime" BU_SG_REL_ Getriebe_Derivate SG_ 1714 KBI_Kilometerstand 5000;
BA_REL_ "GenSigTimeoutTime" BU_SG_REL_ Airbag SG_ 1714 KBI_Kilometerstand 5000;
BA_REL_ "GenSigTimeoutTime" BU_SG_REL_ PSM_Ant_Derivate SG_ 1714 Uhrzeit_01_alt 5000;
BA_REL_ "GenSigTimeoutTime" BU_SG_REL_ Airbag SG_ 1714 Uhrzeit_01_alt 5000;
BA_REL_ "GenSigTimeoutTime" BU_SG_REL_ BMS_Hybrid SG_ 1714 Uhrzeit_01_alt 5000;
BA_REL_ "GenSigTimeoutTime" BU_SG_REL_ LEH_Hybrid SG_ 1714 Uhrzeit_01_alt 5000;
BA_REL_ "GenSigTimeoutTime" BU_SG_REL_ Waehlhebel SG_ 1714 Uhrzeit_01_alt 5000;
BA_REL_ "GenSigTimeoutTime" BU_SG_REL_ Ladegeraet_PAG_PF SG_ 1714 Uhrzeit_01_alt 5000;
BA_REL_ "GenSigTimeoutTime" BU_SG_REL_ Motor_EDC17_Pirol SG_ 1313 STH_LED 2000;
BA_REL_ "GenSigTimeoutTime" BU_SG_REL_ Motor_EDC17_Pirol SG_ 1313 STH_EKP_Anst 2000;
BA_REL_ "GenSigTimeoutTime" BU_SG_REL_ Motor_EDC17_Pirol SG_ 1313 STH_Motorvorwaermung 2000;
BA_REL_ "GenSigTimeoutTime" BU_SG_REL_ Motor_EDC17_Pirol SG_ 1313 STH_war_aktiv 2000;
BA_REL_ "GenSigTimeoutTime" BU_SG_REL_ Motor_EDC17_Pirol SG_ 134 LWI_01_CHK 500;
BA_REL_ "GenSigTimeoutTime" BU_SG_REL_ Motor_MED17_Hybrid SG_ 134 LWI_01_CHK 500;
BA_REL_ "GenSigTimeoutTime" BU_SG_REL_ Motor_EDC17_Pirol SG_ 134 LWI_01_BZ 500;
BA_REL_ "GenSigTimeoutTime" BU_SG_REL_ Motor_MED17_Hybrid SG_ 134 LWI_01_BZ 500;
BA_REL_ "GenSigTimeoutTime" BU_SG_REL_ Motor_EDC17_Pirol SG_ 134 LWI_Sensorstatus 500;
BA_REL_ "GenSigTimeoutTime" BU_SG_REL_ Motor_MED17_Hybrid SG_ 134 LWI_Sensorstatus 500;
BA_REL_ "GenSigTimeoutTime" BU_SG_REL_ Motor_EDC17_Pirol SG_ 134 LWI_QBit_Lenkradwinkel 500;
BA_REL_ "GenSigTimeoutTime" BU_SG_REL_ Motor_MED17_Hybrid SG_ 134 LWI_QBit_Lenkradwinkel 500;
BA_REL_ "GenSigTimeoutTime" BU_SG_REL_ Motor_EDC17_Pirol SG_ 134 LWI_Lenkradwinkel 500;
BA_REL_ "GenSigTimeoutTime" BU_SG_REL_ Motor_MED17_Hybrid SG_ 134 LWI_Lenkradwinkel 500;
BA_REL_ "GenSigTimeoutTime" BU_SG_REL_ Motor_EDC17_Pirol SG_ 134 LWI_VZ_Lenkradwinkel 500;
BA_REL_ "GenSigTimeoutTime" BU_SG_REL_ Motor_MED17_Hybrid SG_ 134 LWI_VZ_Lenkradwinkel 500;
BA_REL_ "GenSigTimeoutTime" BU_SG_REL_ Motor_EDC17_Pirol SG_ 1633 AAG_BZ 1000;
BA_REL_ "GenSigTimeoutTime" BU_SG_REL_ Motor_MED17_Hybrid SG_ 1633 AAG_BZ 1000;
BA_REL_ "GenSigTimeoutTime" BU_SG_REL_ Motor_EDC17_Pirol SG_ 1633 AAG_Bremsl_durch_ECD 1000;
BA_REL_ "GenSigTimeoutTime" BU_SG_REL_ Motor_MED17_Hybrid SG_ 1633 AAG_Bremsl_durch_ECD 1000;
BA_REL_ "GenSigTimeoutTime" BU_SG_REL_ Motor_EDC17_Pirol SG_ 1633 AAG_Anhaenger_erkannt 1000;
BA_REL_ "GenSigTimeoutTime" BU_SG_REL_ Motor_MED17_Hybrid SG_ 1633 AAG_Anhaenger_erkannt 1000;
BA_REL_ "GenSigTimeoutTime" BU_SG_REL_ Motor_EDC17_Pirol SG_ 1633 AAG_Bremslicht_H_def 1000;
BA_REL_ "GenSigTimeoutTime" BU_SG_REL_ Motor_MED17_Hybrid SG_ 1633 AAG_Bremslicht_H_def 1000;
BA_REL_ "GenSigTimeoutTime" BU_SG_REL_ Getriebe_Derivate SG_ 780 ACC_02_CHK 500;
BA_REL_ "GenSigTimeoutTime" BU_SG_REL_ Getriebe_Derivate SG_ 780 ACC_02_BZ 500;
BA_REL_ "GenSigTimeoutTime" BU_SG_REL_ Getriebe_Derivate SG_ 780 ACC_Wunschgeschw 500;
BA_REL_ "GenSigTimeoutTime" BU_SG_REL_ Getriebe_Derivate SG_ 1743 NMH_EM_Start_1 2000;
BA_REL_ "GenSigTimeoutTime" BU_SG_REL_ BMS_Hybrid SG_ 1743 NMH_EM_Start_1 2000;
BA_REL_ "GenSigTimeoutTime" BU_SG_REL_ Motor_MED17_Hybrid SG_ 1743 NMH_EM_Start_1 2000;
BA_REL_ "GenSigTimeoutTime" BU_SG_REL_ Ladegeraet_PAG_PF SG_ 1743 NMH_EM_Start_1 2000;
BA_REL_ "GenSigTimeoutTime" BU_SG_REL_ GW_Routing_Derivate SG_ 786 TSK_03_CHK 500;
BA_REL_ "GenSigTimeoutTime" BU_SG_REL_ Getriebe_Derivate SG_ 786 TSK_03_CHK 500;
BA_REL_ "GenSigTimeoutTime" BU_SG_REL_ GW_Routing_Derivate SG_ 786 TSK_03_BZ 500;
BA_REL_ "GenSigTimeoutTime" BU_SG_REL_ Getriebe_Derivate SG_ 786 TSK_03_BZ 500;
BA_REL_ "GenSigTimeoutTime" BU_SG_REL_ GW_Routing_Derivate SG_ 786 FAS_Wunschgeschw 500;
BA_REL_ "GenSigTimeoutTime" BU_SG_REL_ Getriebe_Derivate SG_ 786 FAS_Wunschgeschw 500;
BA_REL_ "GenSigTimeoutTime" BU_SG_REL_ GW_Routing_Derivate SG_ 786 FAS_Texte_Primaeranz 500;
BA_REL_ "GenSigTimeoutTime" BU_SG_REL_ GW_Routing_Derivate SG_ 786 FAS_Status_Prim_Anz 500;
BA_REL_ "GenSigTimeoutTime" BU_SG_REL_ GW_Routing_Derivate SG_ 786 FAS_Status_Anzeige 500;
BA_REL_ "GenSigTimeoutTime" BU_SG_REL_ GW_Routing_Derivate SG_ 16 WFS_MSG1_IMS 500;
BA_REL_ "GenSigTimeoutTime" BU_SG_REL_ Motor_EDC17_Pirol SG_ 17 WFS_IMS_MSG1 500;
BA_REL_ "GenSigTimeoutTime" BU_SG_REL_ Motor_MED17_Hybrid SG_ 17 WFS_IMS_MSG1 500;
BA_REL_ "HYB_Tx_Baureihe" BU_BO_REL_ GW_Routing_Derivate 1646 2;
BA_REL_ "HYB_Tx_Baureihe" BU_BO_REL_ GW_Routing_Derivate 1636 2;
BA_REL_ "HYB_Tx_Baureihe" BU_BO_REL_ GW_Routing_Derivate 959 2;
BA_REL_ "HYB_Tx_Baureihe" BU_BO_REL_ GW_Routing_Derivate 2033 2;
BA_REL_ "HYB_Tx_Baureihe" BU_BO_REL_ GW_Routing_Derivate 901 2;
BA_REL_ "HYB_Tx_Baureihe" BU_BO_REL_ GW_Routing_Derivate 25 2;
BA_REL_ "HYB_Tx_Baureihe" BU_BO_REL_ GW_Routing_Derivate 1603 2;
BA_REL_ "HYB_Tx_Verwendung" BU_BO_REL_ GW_Routing_Derivate 267 1;
BA_REL_ "HYB_Tx_Baureihe" BU_BO_REL_ GW_Routing_Derivate 267 2;
BA_REL_ "HYB_Tx_Baureihe" BU_BO_REL_ GW_Routing_Derivate 260 2;
BA_REL_ "HYB_Tx_Baureihe" BU_BO_REL_ GW_Routing_Derivate 1313 2;
BA_REL_ "HYB_Tx_Baureihe" BU_BO_REL_ GW_Routing_Derivate 134 2;
BA_REL_ "HYB_Tx_Baureihe" BU_BO_REL_ GW_Routing_Derivate 1633 2;
BA_REL_ "HYB_Tx_Baureihe" BU_BO_REL_ GW_Routing_Derivate 780 2;
BA_REL_ "HYB_Tx_Baureihe" BU_BO_REL_ GW_Routing_Derivate 17 2;
VAL_ 157 MO_HYB_EMode_Info 0 "Normal_Mode" 1 "Depleting_Mode" 2 "Charge_Mode" 3 "Sonder_Schaltprogramm" ;
VAL_ 157 MO_HYB_IstStatusK0 3 "Fehler" 2 "zu" 1 "Uebergang" 0 "auf" ;
VAL_ 157 MO_HYB_max_ind_VM_Mom 1022 "Init" 1023 "Fehler" ;
VAL_ 157 MO_HYB_Zielzustand 0 "Init" 1 "Leerlauf_VM" 2 "hybridisch_Fahren" 3 "Fahren_EM" 4 "Fahrbereitschaft_EM" 5 "Fahrbereitschaft_VM" 7 "Fehler" ;
VAL_ 157 MO_HYB_Startmodus 0 "Drag_Start" 1 "slip_start_comf" 2 "slip_start_trq" 3 "slip_start_pwr" 4 "anger_comf" 5 "anger_trq" 6 "anger_pwr" 7 "Impulsstart" ;
VAL_ 157 MO_HYB_Startmodus_PQ3x 0 "Impulsstart" 1 "Direktstart" ;
VAL_ 157 MO_HYB_Stoppmodus 0 "Softstopp" 1 "Dynamikstopp" ;
VAL_ 157 MO_HYB_VM_Mom_oE 1023 "Fehler" ;
VAL_ 157 MO_HYB_VM_aktiv 0 "VM_nicht_aktiv" 1 "VM_aktiv" ;
VAL_ 157 MO_HYB_Schaltverhinderung 0 "keine_Schaltverhinderung" 1 "Schaltverhinderung" ;
VAL_ 157 MO_HYB_Selektor_Momverlauf_EM 0 "keine_Werte" 1 "max_Rekup_Moment" 2 "KnickDZ_Rekup_Kurve" 3 "max_pos_EM_Moment" 4 "KnickDZ_EM_Kurve" ;
VAL_ 811 MO_FahrPr7_verfuegbar 0 "Fahrprogramm_nicht_verfuegbar" 1 "Fahrprogramm_verfuegbar" ;
VAL_ 811 MO_FahrPr6_verfuegbar 0 "Fahrprogramm_nicht_verfuegbar" 1 "Fahrprogramm_verfuegbar" ;
VAL_ 811 MO_FahrPr5_verfuegbar 0 "Fahrprogramm_nicht_verfuegbar" 1 "Fahrprogramm_verfuegbar" ;
VAL_ 811 MO_FahrPr4_verfuegbar 0 "Fahrprogramm_nicht_verfuegbar" 1 "Fahrprogramm_verfuegbar" ;
VAL_ 811 MO_FahrPr3_verfuegbar 0 "Fahrprogramm_nicht_verfuegbar" 1 "Fahrprogramm_verfuegbar" ;
VAL_ 811 MO_FahrPr2_verfuegbar 0 "Fahrprogramm_nicht_verfuegbar" 1 "Fahrprogramm_verfuegbar" ;
VAL_ 811 MO_FahrPr1_verfuegbar 0 "Fahrprogramm_nicht_verfuegbar" 1 "Fahrprogramm_verfuegbar" ;
VAL_ 811 MO_HYB_E_Faktor 0 "null" 1 "plus_1" 2 "plus_2" 3 "plus_3" 4 "plus_4" 5 "plus_5" 6 "plus_6" 7 "plus_7" 8 "minus_8" 9 "minus_7" 10 "minus_6" 11 "minus_5" 12 "minus_4" 13 "minus_3" 14 "minus_2" 15 "minus_1" ;
VAL_ 811 MO_HYB_Drehzahl_VM 65280 "Fehler" ;
VAL_ 811 MO_HYB_LowSpeedModus 0 "LowSpeed_mit_LLDZ" 1 "LowSpeed_ohne_LLDZ" ;
VAL_ 933 MO_Overboost 0 "inaktiv" 1 "aktiv" ;
VAL_ 933 Enrgfluss_State 1 "no_torques" 2 "pos_tor_EE" 3 "pos_tor_ICE" 4 "pos_tor_ICE_bat_charge" 5 "pos_tor_EE_ICE" 6 "neg_tor_EE_bar_charge" 7 "neg_tor_EE_bat_discharge" 8 "neg_tor_EE" 9 "ICE_charge_bat" 10 "neg_tor_EE_and_ICE" 11 "no_tor_sailing" 12 "no_tor_sailing_and_ICE" 255 "Fehler" ;
VAL_ 933 Ladezustand 255 "Fehler" ;
VAL_ 933 Energiefluss 255 "Fehler" ;
VAL_ 933 Enrgrueckfluss 255 "Fehler" ;
VAL_ 933 MO_Temp_MotRaum 63 "Fehler" ;
VAL_ 933 MO_Oel_Temp_Radsatz 255 "Fehler" ;
VAL_ 933 MO_LED_Abgasklappe 0 "LED aus" 1 "LED ein" ;
VAL_ 933 MO_Hoch_Anz_Nmax 0 "inaktiv" 1 "aktiv" ;
VAL_ 933 MO_Hoch_Anz_Eco 0 "inaktiv" 1 "aktiv" ;
VAL_ 933 MO_Fehler_MSpG 0 "i.O." 1 "Gebläse defekt oder Motorraumtemp. zu hoch" ;
VAL_ 933 MO_Anf_Abgasklappe 0 "nicht angesteuert" 1 "angesteuert" ;
VAL_ 1730 NMH_GE_N_Haltephase 1 "N_Haltephase_aktiv" 0 "keine_N_Haltephase" ;
VAL_ 1729 NMH_MO_NM_aktiv_HV_Abschaltung 1 "Abschaltung_aktiv" 0 "kein_Nachlauf" ;
VAL_ 913 OBD_Driving_Cycle 0 "kein Driving Cycle erkannt" 1 "DC erkannt" ;
VAL_ 913 OBD_Warm_Up_Cycle 0 "kein Warm Up Cycle erkannt" 1 "Warm Up Cycle erkannt" ;
VAL_ 913 OBD_Normed_Trip 0 "kein Normed Trip" 1 "Normed Trip erfüllt" ;
VAL_ 913 OBD_Sperrung_IUMPR 0 "IUMPR_Berechnung_freigegeben" 1 "IUMPR_Berechnung_gesperrt" ;
VAL_ 913 OBD_Kaltstart_Denominator 0 "Denominator_nicht_hochzaehlen" 1 "Bedingungen_zum_Inkr_des_Kaltstart_Denom_erf" ;
VAL_ 913 OBD_Minimum_Trip 0 "kein_Min_Normed_Trip" 1 "Min_Normed_Trip" ;
VAL_ 270 TSK_ax_Getriebe 511 "nicht definiert" ;
VAL_ 270 TSK_Freig_WU 0 "TSK_Uebersetzungswunsch nicht freigegeben" 1 "TSK_Uebersetzungswunsch freigegeben" ;
VAL_ 270 TSK_Limiter_aktiv 0 "Speed Limiter ist nicht aktiv" 1 "Speed Limiter aktiv und regelt" ;
VAL_ 270 TSK_Status_GRA_ACC_02 0 "nicht verbaut / kein ACC zulässig" 1 "GRA / ACC aktiv " 2 "GRA / ACC vom Fahrer übersteuert" 3 "Fehler, GRA/ACC nicht möglich " ;
VAL_ 273 TSK_Fahrzeugmasse_02 255 "Fehler" ;
VAL_ 273 TSK_QBit_Steigung 0 "gueltiger_Wert" 1 "Ersatz_Init_oder_Fehlerwert" ;
VAL_ 273 TSK_Status_GRA_ACC_01 0 "nicht_verbaut_kein_ACC_zulaessig" 1 "GRA_ACC_aktiv" 2 "GRA_ACC_vom_Fahrer_uebersteuert" 3 "Fehler_GRA_ACC_nicht_moeglich" ;
VAL_ 273 TSK_Fahrzeugmasse 31 "Fehler" ;
VAL_ 273 TSK_QBit_Fahrzeugmasse 0 "gueltiger_Wert" 1 "Ersatz_Init_oder_Fehlerwert" ;
VAL_ 273 TSK_Steigung 255 "Fehler" ;
VAL_ 273 TSK_Getriebeinfo 0 "Handschalter" 1 "AL_AQ_Getriebe" 2 "DL_DQ_Getriebe" 3 "CVT_Getriebe" ;
VAL_ 273 TSK_Codierung_ACC 0 "TSK_korrekt_auf_kein_ACC_codiert_oder_TSK_falsch_codiert" 1 "TSK_korrekt_auf_ACC_codiert" ;
VAL_ 273 TSK_Zwangszusch_ESP 0 "keine_ESP_ASR_Beeinflussung" 1 "ESP_ASR_Beeinflussung" ;
VAL_ 273 TSK_Freig_Verzoeg_Anf 0 "Verzoegerungsanforderung_nicht_freigegeben" 1 "Verzoegerungsanforderung_freigegeben" ;
VAL_ 915 GE_Tipschaltempf_verfuegbar 0 "nicht_verfuegbar" 1 "verfuegbar" ;
VAL_ 915 GE_Sollgang 0 "keine_Empfehlung" 1 "Gang_1" 2 "Gang_2" 3 "Gang_3" 4 "Gang_4" 5 "Gang_5" 6 "Gang_6" 7 "Gang_7" 8 "Gang_8" 9 "Gang_9" ;
VAL_ 915 WBA_GE_Zusatzwarnungen 0 "keine_Anzeige" 1 "Getriebeueberhitzung_Warnstufe_I" 2 "Getriebeueberhitzung_Warnstufe_II" 3 "Getriebefehler_Bitte_anhalten_und_P_einlegen" ;
VAL_ 915 WBA_Effizienzmodus 0 "nicht_im_Effizienz_Modus" 1 "Effizienz_Modus" ;
VAL_ 915 WBA_Sollgang 0 "keine Empfehlung" 1 "1.Gang" 2 "2.Gang" 3 "3.Gang" 4 "4.Gang" 5 "5.Gang" 6 "6.Gang" ;
VAL_ 915 WBA_Senderkennung 1 "Motor" 0 "Getriebe" ;
VAL_ 915 WBA_Lampe_Shift_Lock 1 "SL_Lampe_ein" 0 "SL_Lampe_aus" ;
VAL_ 915 WBA_Blinken 1 "WBA_Blinken" 0 "kein_WBA_Blinken" ;
VAL_ 915 WBA_Getriebevariante 15 "9 Gang Automat Tiptronic" 14 "8 Gang Automat Tiptronic" 13 "7 Gang Automat Tiptronic" 12 "6 Gang Automat Tiptronic" 11 "5 Gang Automat Tiptronic" 10 "tbd." 9 "tbd." 8 "2x3 shift_by_wire" 7 "tbd." 6 "Automat PRNDS" 5 "tbd." 4 "Vorhalt für ASG (Selespeed)" 3 "tbd." 2 "tbd." 1 "Automat PRND" ;
VAL_ 915 WBA_GE_Warnung 7 "Kupplung ueberhitzt, Fahrzeug Stopp (+ rotes Getriebefehlersymbol)" 6 "Kupplung ueberhitzt, Fahrzeug Stopp (+ gelbes Getriebefehlersymbol)" 5 "Wegrollgefahr! P nicht möglich" 4 "Getriebefehler, Weiterfahrt nur in D moeglich, P bei Motor aus" 3 "nur DL-Getriebe: Weiterfahrt nur eingeschränkt möglich. Kein R-Gang" 2 "Weiterfahrt nur eingeschränkt möglich (+ gelbes Getriebefehlersymbol)" 1 "Weiterfahrt möglich (+ gelbes Getriebefehlersymbol)" 0 "keine Anzeige" ;
VAL_ 915 WBA_Schaltempf_verfbar 0 "nicht verfügbar" 1 "verfügbar" ;
VAL_ 915 WBA_eing_Gang 10 "9.Gang" 9 "8.Gang" 8 "7.Gang" 7 "6.Gang" 6 "5.Gang" 5 "4.Gang" 4 "3.Gang" 3 "2.Gang" 2 "1.Gang" 1 "Init" 0 "kein Gang eingelegt / kein Gang empfohlen" ;
VAL_ 915 WBA_Istgang 0 "kein Gang eingelegt" 1 "1.Gang" 2 "2.Gang" 3 "3.Gang" 4 "4.Gang" 5 "5.Gang" 6 "6.Gang" ;
VAL_ 915 WBA_GE_Texte 4 "Achtung_Zeitueberschreitung_P_wird_eingelegt" 3 "Wegrollgefahr_bitte_P_einlegen" 2 "zum_Einlegen_von_R,N,D_Fussbremse_betaetigen_und_Motor_starten" 1 "zum_Einlegen_einer_Fahrstufe_Fussbremse_betaetigen__ShiftLock_Information" 0 "keine Anzeige" ;
VAL_ 915 WBA_Schaltschema_Aktiv 1 "Schaltschema_anzeigen" 0 "keine_Anzeige" ;
VAL_ 915 WH_Warnung 1 "Waehlhebelfehler_Fahrstufenwechsel_moeglich_(gelbes_Getriebesymbol)" 0 "keine_Anzeige" ;
VAL_ 1602 WIV_Verschleissindex 65535 "Fehler" ;
VAL_ 1602 WIV_Russindex 65535 "Fehler" ;
VAL_ 1646 KL_STL_aktiv 1 "Aktiv" 0 "Inaktiv" ;
VAL_ 1646 KL_STH_Ansteuerung 3 "Heizleistung reduziert" 2 "Ein mit Motorvorwaermung" 1 "Ein" 0 "Aus" ;
VAL_ 1646 KL_STH_aktiv 1 "Aktiv" 0 "Inaktiv" ;
VAL_ 1646 KL_Magnetventil 1 "Wasserventil geschlossen" 0 "Wasserventil geoeffnet" ;
VAL_ 1646 KL_AussenTemp_WK 253 "nicht verbaut" 254 "Init Wert, nicht verfuegbar" 255 "Fehler" ;
VAL_ 1646 KL_MSG_valid 1 "Message valid" 0 "Message not valid" ;
VAL_ 1646 KL_Solarluefter_aktiv 1 "Aktiv" 0 "Inaktiv" ;
VAL_ 1636 KL_I_Geblaese 255 "Fehler" ;
VAL_ 1636 KL_Beschlagsgefahr 0 "keine_Beschlagsgefahr" 1 "Beschlagsgefahr" ;
VAL_ 1636 KL_Umluftklappe_Status 2 "Teilumluft 20%" 5 "Teilumluft 50%" 7 "Teilumluft 70%" 9 "Teilumluft 90% " 0 "Frischluft" 4 "Teilumluft 40%" 1 "Teilumluft 10%" 10 "Umluft" 6 "Teilumluft 60%" 8 "Teilumluft 80%" 3 "Teilumluft 30%" 15 "Fehler" ;
VAL_ 1636 KL_HSH_Taktung 1 "Aktiv" 0 "Inaktiv" ;
VAL_ 1636 KL_Zuheizer_Freigabe 1 "Zuheizerfreigabe" 0 "keine Freigabe Zuheizer" ;
VAL_ 1636 KL_Geblaese_Status 15 "Fehler" 14 "Init" 10 "Geblaese Stufe 100%" 9 "Geblaese Stufe 90%" 8 "Geblaese Stufe 80%" 7 "Geblaese Stufe 70%" 6 "Geblaese Stufe 60%" 5 "Geblaese Stufe 50%" 4 "Geblaese Stufe 40%" 3 "Geblaese Stufe 30%" 2 "Geblaese Stufe 20%" 1 "Geblaese Stufe 10%" 0 "Geblaese aus" ;
VAL_ 959 KL_Zustand 1 "ein" 0 "aus" ;
VAL_ 959 KL_4_Zonen 1 "4_Zonen_Klimaanlage" 0 "2_Zonen_Klimaanlage" ;
VAL_ 959 KL_Thermomanagement 3 "volle Freigabe TMM (kein Heizbedarf)" 2 "mittlere Freigabe TMM" 1 "kleine Freigabe TMM" 0 "keine Freigabe TMM (max. Heizbedarf)" ;
VAL_ 959 KL_StartStopp_Info 3 "Systemfehler" 2 "Motoranlauf zwingend notwendig (Startanforderung)" 1 "Motoranlauf nicht zwingend notwendig (Stoppverbot, keine Startanforderung, evtl. Komforteinbussen)" 0 "Motorlauf langfristig nicht notwendig (Stoppfreigabe)" ;
VAL_ 959 KL_KD_Fehler 1 "mind. ein KD-Fehler vorhanden" 0 "kein KD-Fehler" ;
VAL_ 959 KL_Last_Kompr 255 "Fehler" ;
VAL_ 1413 GW_KD_Fehler 1 "mind. ein KD-Fehler vorhanden" 0 "kein KD-Fehler" ;
VAL_ 1413 SI_QRS_Mode 0 "QRS_Messmodus_nicht_aktiv" 1 "QRS_Messmodus_aktiv" ;
VAL_ 1413 SI_NWDF_gueltig 1 "NWDF_wird_unterstuetzt" 0 "NWDF_wird_nicht_unterstuetzt" ;
VAL_ 1413 SI_NWDF 1 "Ueberwachung_freigeben" 0 "Ueberwachung_nicht_freigeben" ;
VAL_ 1413 SI_Fahrwerk_Sleep 1 "Busruhe" 0 "keine Busruhe" ;
VAL_ 1413 SI_CAN_Crash_Sleep 1 "Busruhe" 0 "keine Busruhe" ;
VAL_ 1413 SI_CAN_Antrieb_Sleep 1 "Busruhe" 0 "keine Busruhe" ;
VAL_ 1413 SI_CAN_MMI_Sleep 1 "Busruhe" 0 "keine Busruhe" ;
VAL_ 1413 SI_CAN_Komfort_Sleep 1 "Busruhe" 0 "keine Busruhe" ;
VAL_ 1413 SI_T_Mode 1 "Transportmode aktiv" 0 "Transportmode nicht aktiv" ;
VAL_ 901 CHA_Systemstatus 1 "reserviert" 3 "reserviert" 0 "Status in Ordnung" 2 "reserviert" ;
VAL_ 901 CHA_Ziel_FahrPr_MO 4 "FahrPr_4" 0 "nicht_belegt" 2 "FahrPr_2" 1 "FahrPr_1" 3 "FahrPr_3" 6 "FahrPr_6" 5 "FahrPr_5" 7 "FahrPr_7" ;
VAL_ 901 CHA_Ziel_FahrPr_GE 4 "FahrPr_4" 0 "nicht_belegt" 2 "FahrPr_2" 1 "FahrPr_1" 3 "FahrPr_3" 6 "FahrPr_6" 5 "FahrPr_5" 7 "FahrPr_7" ;
VAL_ 901 CHA_Ziel_FahrPr_ST 4 "FahrPr_4" 0 "nicht_belegt" 2 "FahrPr_2" 1 "FahrPr_1" 3 "FahrPr_3" 6 "FahrPr_6" 5 "FahrPr_5" 7 "FahrPr_7" ;
VAL_ 901 CHA_Ziel_FahrPr_SCU 4 "FahrPr_4" 0 "nicht_belegt" 2 "FahrPr_2" 1 "FahrPr_1" 3 "FahrPr_3" 6 "FahrPr_6" 5 "FahrPr_5" 7 "FahrPr_7" ;
VAL_ 901 CHA_Ziel_FahrPr_DR 4 "FahrPr_4" 0 "nicht_belegt" 2 "FahrPr_2" 1 "FahrPr_1" 3 "FahrPr_3" 6 "FahrPr_6" 5 "FahrPr_5" 7 "FahrPr_7" ;
VAL_ 901 CHA_Ziel_FahrPr_QS 4 "FahrPr_4" 0 "nicht_belegt" 2 "FahrPr_2" 1 "FahrPr_1" 3 "FahrPr_3" 6 "FahrPr_6" 5 "FahrPr_5" 7 "FahrPr_7" ;
VAL_ 901 CHA_Ziel_FahrPr_AFS 4 "FahrPr_4" 0 "nicht_belegt" 2 "FahrPr_2" 1 "FahrPr_1" 3 "FahrPr_3" 6 "FahrPr_6" 5 "FahrPr_5" 7 "FahrPr_7" ;
VAL_ 901 CHA_Ziel_FahrPr_RGS 4 "FahrPr_4" 0 "nicht_belegt" 2 "FahrPr_2" 1 "FahrPr_1" 3 "FahrPr_3" 6 "FahrPr_6" 5 "FahrPr_5" 7 "FahrPr_7" ;
VAL_ 901 CHA_Ziel_FahrPr_EPS 4 "FahrPr_4" 0 "nicht_belegt" 2 "FahrPr_2" 1 "FahrPr_1" 3 "FahrPr_3" 6 "FahrPr_6" 5 "FahrPr_5" 7 "FahrPr_7" ;
VAL_ 901 CHA_Ziel_FahrPr_ACC 0 "nicht_belegt" 1 "FahrPr_1" 2 "FahrPr_2" 3 "FahrPr_3" 4 "FahrPr_4" 5 "FahrPr_5" 6 "FahrPr_6" 7 "FahrPr_7" ;
VAL_ 1603 KBI_Einheit_Verbrauch_elektr 0 "kWh_pro_100km" 1 "kWh_pro_100mls" 2 "km_pro_kWh" 3 "mls_pro_kWh" 4 "MPGe" ;
VAL_ 1603 KBI_Einheit_Datum 3 "reserviert" 2 "Jahr/Monat/Tag" 1 "Monat/Tag/Jahr" 0 "Tag/Monat/Jahr" ;
VAL_ 1603 KBI_Einheit_Streckenanz 0 "Kilometer" 1 "Meilen" ;
VAL_ 1603 KBI_Einheit_Temp 1 "Grad Fahrenheit °F" 0 "Grad Celsius °C" ;
VAL_ 1603 KBI_Einheit_Uhrzeit 1 "12h AM/PM" 0 "24h" ;
VAL_ 1603 KBI_Einheit_Sprache 255 "Fehler" 13 "Russisch" 12 "Portugiesisch" 11 "Türkisch" 10 "Schwedisch" 9 "Dänisch" 8 "Holländisch" 7 "Chinesisch (Simplified Chinese)" 6 "Japanisch (Katakana)" 5 "Italienisch" 4 "Spanisch" 3 "Französisch" 2 "US-Englisch" 1 "Englisch" 0 "Deutsch" ;
VAL_ 1603 KBI_Einheit_Volumen 3 "reserviert" 0 "Liter" 1 "Gallonen_UK" 2 "Gallonen_USA" ;
VAL_ 1603 KBI_Einheit_Verbrauch 1 "mpg USA" 2 "Liter/100km" 0 "mpg UK" 3 "km/Liter" ;
VAL_ 1603 KBI_MFA_v_Einheit_02 1 "mph" 0 "kmh" ;
VAL_ 1603 KBI_Einheit_Druck 3 "tbd" 2 "Druckangabe in kPa" 1 "Druckangabe in psi" 0 "Druckangabe in bar" ;
VAL_ 267 MFL_Tip_Up 1 "betätigt" 0 "nicht betätigt" ;
VAL_ 267 MFL_Tip_Down 1 "betätigt" 0 "nicht betätigt" ;
VAL_ 267 LS_Tiptronic_Fehler 1 "Fehler" 0 "kein Fehler" ;
VAL_ 267 LS_Tip_Wiederaufnahme 1 "Tippschalter betaetigt" 0 "Tippschalter nicht betaetigt" ;
VAL_ 267 LS_Tip_Setzen 1 "Tippschalter betaetigt" 0 "Tippschalter nicht betaetigt" ;
VAL_ 267 LS_Tip_Runter 1 "Tippschalter betaetigt" 0 "Tippschalter nicht betaetigt" ;
VAL_ 267 LS_Tip_Hoch 1 "Tippschalter betaetigt" 0 "Tippschalter nicht betaetigt" ;
VAL_ 267 LS_Limiter 1 "ein" 0 "aus" ;
VAL_ 267 LS_Hauptschalter 1 "Ein" 0 "Gerastet Aus" ;
VAL_ 267 LS_Fehler 1 "Fehler Bedienteil" 0 "in Ordnung" ;
VAL_ 267 LS_Codierung 7 "nicht verwendet" 6 "nicht verwendet" 5 "ACC Hebel, Tiptronic am Lenkrad" 4 "ACC Hebel, keine Tiptronic am Lenkrad" 3 "GRA Hebel, Tiptronic am Lenkrad" 2 "GRA Hebel, keine Tiptronic am Lenkrad" 1 "kein Hebel, Tiptronic am Lenkrad" 0 "kein Hebel, keine Tiptronic am Lenkrad" ;
VAL_ 267 LS_Abbrechen 1 "Tippschalter betätigt" 0 "Tippschalter nicht betätigt" ;
VAL_ 267 MFL_M_Taste 1 "Taster betätigt" 0 "Taster nicht betätigt" ;
VAL_ 267 LS_Tip_Stufe_2 0 "Hebelbetaetigung_in_erster_Tipstufe__Keine_Hebelbetaetigung" 1 "Hebelbetaetigung_in_der_zweiten_Tipstufe" ;
VAL_ 267 LS_GRA_ACC_2stufig 0 "kein_zweistufiger_Hebel_verbaut" 1 "zweistufiger_Hebel_verbaut" ;
VAL_ 260 EPB_Konsistenz_ACC 1 "Fehler" 0 "kein Fehler" ;
VAL_ 260 EPB_Anfahrwunsch_erkannt 1 "Anfahrwunsch erkannt" 0 "kein Anfahrwunsch erkannt" ;
VAL_ 260 EPB_Pedalweg_Kuppl 0 "Init" 255 "Fehler" ;
VAL_ 260 EPB_Fehlerstatus 2 "EPB temporär nicht verfügbar - Spannen nicht möglich da Fzg. in Fahrt" 1 "EPB temporär nicht verfügbar - AVH darf nicht aktiv werden, sondern muss bei AVH-Anforderung warnen" 3 "Fehler in EPB - AVH darf von ESP nicht ausgeführt werden" 0 "kein Fehler in EPB - AVH darf von ESP ausgeführt werden" ;
VAL_ 260 EPB_Schalterposition 2 "Fahreranforderung_Schliessen" 0 "keine_Fahreranforderung" 1 "Fahreranforderung_Oeffnen" 3 "Schalterfehler" ;
VAL_ 260 EPB_QBit_Schalterpos 1 "Ersatz-, Init- oder Fehlerwert (Schalter ausser Funktion)" 0 "gültiger Wert (volle Funktion)" ;
VAL_ 260 EPB_Spannkraft 30 "Init" 31 "Fehler" ;
VAL_ 260 EPB_Status 3 "unbekannt" 2 "Aktuator im Lauf" 0 "Bremse_geoeffnet" 1 "Bremse_geschlossen" ;
VAL_ 260 EPB_KD_Fehler 1 "mind. ein KD-Fehler vorhanden" 0 "kein KD-Fehler" ;
VAL_ 260 EPB_QBit_Laengsbeschleunigung 1 "Ersatz-, Init- oder Fehlerwert" 0 "gueltiger_Wert" ;
VAL_ 260 EPB_QBit_Pedalweg_Kuppl 1 "Ersatz_Init_Fehlerwert" 0 "gueltiger_Wert" ;
VAL_ 260 EPB_BCM2_Motor_Wakeup 1 "Anforderung an BCM2 Wakeupleitung zum Motor hochzuziehen aufgrund von Car-Wakeup" 0 "keine Anforderung" ;
VAL_ 260 EPB_Freig_Verzoeg_Anf 0 "Verzögerungsanforderung nicht freigegeben" 1 "Verzögerungsanforderung freigegeben" ;
VAL_ 260 EPB_Laengsbeschleunigung 255 "Fehler" 0 "Init" ;
VAL_ 64 AB_Deaktivierung_HV 0 "keine_Deaktivierung" 1 "Deaktivierung_1" 2 "Deaktivierung_2" 3 "Deaktivierung_3" 4 "Deaktivierung_4" 5 "Deaktivierung_5" 6 "Deaktivierung_6" 7 "Deaktivierung_7" ;
VAL_ 64 AB_RGS_Anst 8 "deaktiviert" 7 "aktiv_Niveau_4" 6 "aktiv_Niveau_3" 5 "aktiv_Niveau_2" 4 "aktiv_Niveau_1" ;
VAL_ 64 AB_Texte_AKS 2 "AKS_Systemfehler" 1 "AKS_ausgeloest" 0 "keine_AKS_Ausloesung" ;
VAL_ 64 AB_Front_Crash 1 "Front_Crash" 0 "kein_Front_Crash" ;
VAL_ 64 AB_Heck_Crash 1 "Heck_Crash" 0 "kein_Heck_Crash" ;
VAL_ 64 AB_SF_Crash 0 "kein_Seiten_Crash_Fahrer" 1 "Seiten_Crash_Fahrer" ;
VAL_ 64 AB_SB_Crash 0 "kein_Seiten_Crash_Beifahrer" 1 "Seiten_Crash_Beifahrer" ;
VAL_ 64 AB_Rollover_Crash 0 "kein_Rollover" 1 "Rollover" ;
VAL_ 64 AB_Crash_Int 5 "Crash_Intensität_3 (nur historisch PAG)" 3 "Crash_Intensität_2 (nur D4, C7, Colorado_NF, PAG; Crash B8, Q5)" 0 "kein Crash" 4 "Crash_Intensität_3 (nur Stellgliedtest B8, Q5; historisch VW/Audi)" 2 "Crash_Intensität_2 (nur Stellgliedtest B8, Q5)" 1 "Crash_Intensität_1" 7 "Crash_Intensität_3" ;
VAL_ 64 AB_Lampe 1 "Lampe_an" 0 "Lampe_aus" ;
VAL_ 64 AB_Deaktiviert 0 "Airbag_aktiv" 1 "Airbag_deaktiviert" ;
VAL_ 64 AB_VB_deaktiviert 1 "Beifahrerairbag_deaktiviert" 0 "Beifahrerairbag_aktiv" ;
VAL_ 64 AB_Systemfehler 0 "kein_Fehler" 1 "Systemfehler" ;
VAL_ 64 AB_Diagnose 1 "Airbag_in_Diagnose" 0 "Airbag_nicht_in_Diagnose" ;
VAL_ 64 AB_Stellgliedtest 0 "Airbag_nicht_im_Stellgliedtest" 1 "Airbag_im_Stellgliedtest" ;
VAL_ 64 AB_Erh_Auf_VB 2 "BF_Airbag_aktiviert" 1 "BF_Airbag_deaktiviert" 3 "nicht_benutzt" 0 "keine_Beschreibung" ;
VAL_ 64 AB_Gurtwarn_VF 1 "Warnung_ausloesen" 0 "keine_Warnung" ;
VAL_ 64 AB_Gurtwarn_VB 1 "Warnung_ausloesen" 0 "keine_Warnung" ;
VAL_ 64 AB_Anzeige_Fussg 2 "Systemfehler" 1 "Motorhaube_offen" 0 "keine_Anzeige" ;
VAL_ 64 AB_PAO_Leuchte_Anf 1 "an" 0 "aus" ;
VAL_ 64 AB_KD_Fehler 1 "mind. ein KD-Fehler vorhanden" 0 "kein KD-Fehler" ;
VAL_ 1312 AB_Sitzpos_Sens_BF 3 "Sitz vorne" 2 "Sitz nicht vorne" 1 "Fehler" 0 "nicht verfügbar" ;
VAL_ 1312 AB_Sitzpos_Sens_FA 3 "Sitz vorne" 2 "Sitz nicht vorne" 1 "Fehler" 0 "nicht verfügbar" ;
VAL_ 1312 AB_Gurtschloss_Reihe3_MI 3 "gesteckt" 2 "nicht_gesteckt" 1 "nicht_verfügbar (Fehler oder Init)" 0 "nicht_verbaut" ;
VAL_ 1312 AB_Gurtschloss_Reihe3_FA 3 "gesteckt" 2 "nicht_gesteckt" 1 "nicht_verfügbar (Fehler oder Init)" 0 "nicht_verbaut" ;
VAL_ 1312 AB_Gurtschloss_Reihe3_BF 3 "gesteckt" 2 "nicht_gesteckt" 1 "nicht_verfügbar (Fehler oder Init)" 0 "nicht_verbaut" ;
VAL_ 1312 AB_Gurtschloss_Reihe2_BF 3 "gesteckt" 2 "nicht_gesteckt" 1 "nicht_verfügbar (Fehler oder Init)" 0 "nicht_verbaut" ;
VAL_ 1312 AB_Gurtschloss_Reihe2_MI 3 "gesteckt" 2 "nicht_gesteckt" 1 "nicht_verfügbar (Fehler oder Init)" 0 "nicht_verbaut" ;
VAL_ 1312 AB_Gurtschloss_Reihe2_FA 3 "gesteckt" 2 "nicht_gesteckt" 1 "nicht_verfügbar (Fehler oder Init)" 0 "nicht_verbaut" ;
VAL_ 1312 AB_Gurtschloss_BF 3 "gesteckt" 2 "nicht_gesteckt" 1 "nicht_verfügbar (Fehler oder Init)" 0 "nicht_verbaut" ;
VAL_ 1312 AB_Gurtschloss_FA 3 "gesteckt" 2 "nicht_gesteckt" 1 "nicht_verfügbar (Fehler oder Init)" 0 "nicht_verbaut" ;
VAL_ 1312 AB_Belegung_VB 1 "Fehler" 0 "Nicht_verfuegbar" 3 "Belegt" 2 "Nicht_belegt" ;
VAL_ 777 BEM_Segel_Info 0 "keine_Anforderung" 1 "Mindestdrehzahl_1" 2 "Mindestdrehzahl_2" 3 "Segelveto" ;
VAL_ 777 BEM_n_LLA 3 "Stufe 3" 2 "Stufe 2" 1 "Stufe 1" 0 "keine Erhöhung" ;
VAL_ 777 BEM_Anf_KL 1 "KL_Anf" 0 "keine_Anf" ;
VAL_ 777 BEM_StartStopp_Info 3 "Systemfehler" 2 "Motoranlauf zwingend notwendig (Startanforderung)" 1 "Motoranlauf nicht zwingend notwendig (Stoppverbot, keine Startanforderung, evtl. Komforteinbussen)" 0 "Motorlauf langfristig nicht notwendig (Stoppfreigabe)" ;
VAL_ 1714 Kombi_02_alt 1 "veraltet" 0 "aktuell" ;
VAL_ 1714 DGN_Verlernzaehler 255 "ungültiger Zählerstand oder kein gültiger Fahrzyklus" ;
VAL_ 1714 KBI_Kilometerstand 1048575 "Fehlerwert" 1048574 "Initwert" ;
VAL_ 1714 Uhrzeit_01_alt 0 "aktuell" 1 "veraltet" ;
VAL_ 1313 STH_Zusatzheizung 1 "Zuheizer ein" 0 "Zuheizer aus" ;
VAL_ 1313 STH_EKP_Anst 1 "EKP ansteuern" 0 "EKP nicht ansteuern" ;
VAL_ 1313 STH_Fehlerstatus 2 "Fuel_Low" 0 "kein_Fehler" 1 "Batterie_Low" 3 "Hardware_defekt" 4 "Heizgeraet_verriegelt" ;
VAL_ 1313 STH_Wassertemp 255 "Fehler" 254 "Init" ;
VAL_ 1313 STH_war_aktiv 0 "war_inaktiv" 1 "war_aktiv" ;
VAL_ 134 LWI_QBit_Sub_Daten 0 "Subinfo_real" 1 "Subinfo_simuliert" ;
VAL_ 134 LWI_QBit_Lenkradwinkel 1 "ausserhalb_Spezifikation" 0 "gueltiger_Wert" ;
VAL_ 134 LWI_Lenkradwinkel 8191 "Fehlerwert" 8190 "Initwert" ;
VAL_ 134 LWI_VZ_Lenkradwinkel 0 "positiv_links_von_der_Nullstellung" 1 "negativ" ;
VAL_ 1633 AAG_Bremsl_durch_ECD 1 "Bremslicht durch ECD aktiv" 0 "Bremslicht ist aus" ;
VAL_ 1633 AAG_Anhaenger_abgesteckt 1 "Anhaenger wurde bei Kl. 15 aus abgesteckt" ;
VAL_ 1633 AAG_NSL_aktiv 1 "Anhaenger Nebelschlusslicht aktiv" ;
VAL_ 1633 AAG_Anhaenger_erkannt 0 "kein Anhänger erkannt" 1 "AAG Anhänger erkannt" ;
VAL_ 1633 AAG_Blinker_H_aktiv 1 "Anhaenger Blinker aktiv" ;
VAL_ 1633 AAG_Blinker_HL_def 1 "Anhaenger Blinker links defekt" ;
VAL_ 1633 AAG_Blinker_HR_def 1 "Anhaenger Blinker rechts defekt" ;
VAL_ 1633 AAG_Bremslicht_H_def 1 "Anhaenger Bremslicht defekt" ;
VAL_ 1633 AAG_Schlusslicht_HL_def 1 "Anhaenger Schlußlicht links defekt" ;
VAL_ 1633 AAG_Schlusslicht_HR_def 1 "Anhaenger Schlußlicht rechts defekt" ;
VAL_ 1633 AAG_KD_Fehler 1 "mind. ein KD-Fehler vorhanden" 0 "kein KD-Fehler" ;
VAL_ 1633 AAG_AVS_Fehler 2 "n.i.O. + Fahrzeugstopp erforderlich" 3 "t.b.d." 0 "i.O." 1 "n.i.O." ;
VAL_ 1633 AAG_AVS_Stati 1 "Endlage Ausgefahren erreicht" 3 "Einfahren Automatik" 2 "Ausfahren Automatik" 5 "Einfahren Manuell" 6 "Zwischenposition" 7 "nicht initialisiert" 0 "Endlage Eingefahren erreicht" 4 "Ausfahren Manuell" ;
VAL_ 780 ACC_Wunschgeschw_erreicht 0 "Wunschgeschwindigkeit_nicht_erreicht" 1 "Wunschgeschwindigkeit_erreicht" ;
VAL_ 780 ACC_Abstandsindex 1023 "Sonderanzeige_Fahrbahn_mit_gruenem_roten_Bereich" 1022 "Sonderanzeige_graue_Fahrbahn" 0 "Sonderanzeige_graue_Fahrbahn" ;
VAL_ 780 ACC_Display_Prio 1 "mittlere_Prio" 0 "hoechste_Prio" 3 "keine_Prio" 2 "geringe_Prio" ;
VAL_ 780 ACC_Relevantes_Objekt 0 "Symbol_nicht_beleuchtet" 1 "Farbe_1" 3 "Farbe_3" 2 "Farbe_2 - nur bei Porsche gilt fuer '2' Warnaufforderung (Kritikalitaet > Schwelle )" ;
VAL_ 780 ACC_Texte_Primaeranz 21 "VDA ACC-Symbol YYY km/h / mph" 7 "Auto_ _Auto_ _ Gong (durchgestrichen)" 2 "Auto_Auto_ _ _" 17 "Herunterschalten" 13 "ACC nicht verfuegbar" 5 "Auto_ _ _ _Auto" 9 "Auto_ _ _ _Auto Gong (durchgestrichen)" 44 "HDC aktiv" 3 "Auto_ _Auto_ _" 1 "ACC nicht verfuegbar !" 8 "Auto_ _ _Auto_ Gong (durchgestrichen)" 6 "Auto_Auto_ _ _ Gong (durchgestrichen)" 18 "Parkbremse !" 20 "Waehlhebelposition !" 14 "o  o  o" 16 "ESP Eingriff" 4 "Auto_ _ _Auto_" 10 "ACC bereit" 12 "ACC Sensor Sicht !" 15 "Hochschalten" 19 "Geschwindigkeitsgrenze" 0 "keine Anzeige " 11 "keine Abstandsregelung" 27 "--- km/h / mph" 38 "Kurvenassistent aus" 39 "Tempolimit aus" 42 "Ortsende XXX km/h / mph" 25 "Symbol 'Eieruhr'" 45 "braking guard Bremsruck" 35 "Fahrer Gurtschloss offen !" 24 "ACC Abschaltung" 28 "XXX km/h / mph (Schriftart 2)" 36 "Schalthebelposition !" 23 "Kurve XXX km/h / mph" 34 "Tuer offen !" 40 "Abbiegeassistent" 31 "Fahrzeug verloren" 29 "Lenkradwinkel" 33 "Ungueltiger Anfahrbefehl" 46 "braking guard aus " 47 "braking guard aus" 41 "Ortsanfang XXX km/h / mph" 26 "!" 32 "Im Stand nicht moeglich" 43 "Tempolimit Ende XXX km/h / mph" 22 "Tempolimit XXX km/h / mph" 30 "Anfahren bestaetigen" 57 "ACC haelt an !" 52 "SET / 'GRA Symbol' xxx km/h / mph" 66 "ESP PASSIV !" 61 "LIM AKTIV " 60 "LIM AUS" 50 "Stehendes Objekt voraus" 58 "Bremse betaetigen !" 62 "LIM PASSIV" 65 "Bremse haelt !" 51 "SET / 'GRA Symbol'___xxx km/h / mph" 63 "LIM FEHLER" 49 "Steigung zu gross" 48 "Uebernehmen !" 54 "ACC startet" 37 "Drehzahl !" 59 "Kupplung betaetigt" 64 "Bremse ueberhitzt !" 53 "ACC aus" 56 "ACC Fehler" 55 "ACC reinigen" ;
VAL_ 780 ACC_Status_Anzeige 0 "ACC_OFF" 2 "ACC_STANDBY" 1 "ACC_INIT" 7 "ACC_FEHLER_IRREVERS" 3 "ACC_AKTIV" 4 "ACC_OVERRIDE" 6 "ACC_FEHLER_REVERS" ;
VAL_ 1743 NMH_EM_keine_HV_Entl 0 "kein_Nachlauf" 1 "HV_Entladung_nicht_moeglich" ;
VAL_ 1743 NMH_EM_Start_1 1 "Zustand Start (<--Sleep)" ;
VAL_ 1743 NMH_EM_Start_2 1 "Zustand Start (<--Prepare to Sleep)" ;
VAL_ 1743 NMH_EM_Normal_Mode_1 1 "Zustand Normal Mode (<-- Start)" ;
VAL_ 1743 NMH_EM_Normal_Mode_2 1 "Zustand Normal Mode (<-- Ready to Sleep)" ;
VAL_ 1743 NMH_EM_Car_WakeUp 1 "Car Wake Up" ;
VAL_ 1743 NMH_EM_Per_WakeUp 3 "KL_15_Hardware_falls_vorhanden" 2 "P_WakeUp_Ursache_unbekannt" 0 "Funktions-WakeUp" 1 "CAN" ;
VAL_ 1743 NMH_EM_Fkt_WakeUp 0 "Peripheriewakeup" ;
VAL_ 1743 NMH_EM_Klemme_15 1 "Klemme 15 ein" ;
VAL_ 1743 NMH_EM_Diagnose 1 "Diagnose bei Kl 15 aus" ;
VAL_ 1743 NMH_EM_MindestAktivZeit 1 "aktiv" ;
VAL_ 1743 NMH_EM_NL_Datem_EEPROM 0 "kein_Nachlauf" 1 "EEPROM_schreibzugriff" ;
VAL_ 1743 NMH_EM_Signalfehler 1 "Aktiver_Signalfehler_eingetragen" ;
VAL_ 1743 NMH_EM_TimeOut_Fehler 1 "Aktiver Timeout Fehlerspeichereintrag" ;
VAL_ 1743 NMH_EM_CAN_Diag_deaktiv 1 "CAN Bus bezogene Eigendiagnose deaktiviert" ;
VAL_ 1743 NMH_EM_KompSchutz 1 "KS aktiv" ;
VAL_ 1743 NMH_EM_Mute_Mode 1 "Mute Mode aktiv" ;
VAL_ 1743 NMH_EM_Transport_Mode 1 "Transportmodus aktiv" ;
VAL_ 1743 NMH_EM_Abschaltstufe_aktiv 1 "Funktionsabschaltung wegen Abschaltschaltstufe" ;
VAL_ 1743 NMH_EM_Busfehler 1 "Busfehler" ;
VAL_ 1743 NMH_EM_Lokalaktiv 0 "war_nicht_lokal_aktiv" 1 "war_lokal_aktiv" ;
VAL_ 1743 NMH_EM_Subsystemaktiv 1 "war Lokalaktiv" 0 "Subsystem war nicht lokalaktiv" ;
VAL_ 786 FAS_Wunschgeschw 1023 "nicht definiert" 1022 "keine Anzeige" ;
VAL_ 786 FAS_Texte_Primaeranz 66 "ESP PASSIV !" 65 "Bremse haelt !" 64 "Bremse ueberhitzt !" 63 "LIM FEHLER" 62 "LIM PASSIV" 61 "LIM AKTIV " 60 "LIM AUS" 59 "Kupplung betaetigt" 58 "Bremse betaetigen !" 57 "ACC haelt an !" 56 "ACC Fehler" 55 "ACC reinigen" 54 "ACC startet" 53 "ACC aus" 52 "SET / 'GRA Symbol' xxx km/h / mph" 51 "SET / 'GRA Symbol'___xxx km/h / mph" 50 "Stehendes Objekt voraus" 49 "Steigung zu gross" 48 "Uebernehmen !" 47 "braking guard aus" 46 "braking guard aus " 45 "braking guard Bremsruck" 44 "HDC aktiv" 43 "Tempolimit Ende XXX km/h / mph" 42 "Ortsende XXX km/h / mph" 41 "Ortsanfang XXX km/h / mph" 40 "Abbiegeassistent" 39 "Tempolimit aus" 38 "Kurvenassistent aus" 37 "Drehzahl !" 36 "Schalthebelposition !" 35 "Fahrer Gurtschloss offen !" 34 "Tuer offen !" 33 "Ungueltiger Anfahrbefehl" 32 "Im Stand nicht moeglich" 31 "Fahrzeug verloren" 30 "Anfahren bestaetigen" 29 "Lenkradwinkel" 28 "XXX km/h / mph (Schriftart 2)" 27 "--- km/h / mph" 26 "!" 25 "Symbol 'Eieruhr'" 24 "ACC Abschaltung" 23 "Kurve XXX km/h / mph" 22 "Tempolimit XXX km/h / mph" 21 "VDA ACC-Symbol YYY km/h / mph" 20 "Waehlhebelposition !" 19 "Geschwindigkeitsgrenze" 18 "Parkbremse !" 17 "Herunterschalten" 16 "ESP Eingriff" 15 "Hochschalten" 14 "o  o  o" 13 "ACC nicht verfuegbar" 12 "ACC Sensor Sicht !" 11 "keine Abstandsregelung" 10 "ACC bereit" 9 "Auto_ _ _ _Auto Gong (durchgestrichen)" 8 "Auto_ _ _Auto_ Gong (durchgestrichen)" 7 "Auto_ _Auto_ _ Gong (durchgestrichen)" 6 "Auto_Auto_ _ _ Gong (durchgestrichen)" 5 "Auto_ _ _ _Auto" 4 "Auto_ _ _Auto_" 3 "Auto_ _Auto_ _" 2 "Auto_Auto_ _ _" 1 "ACC nicht verfuegbar !" 0 "keine Anzeige " ;
VAL_ 786 FAS_Status_Prim_Anz 3 "Farbe 3 (typisch 'gelb')" 2 "Farbe 2 (typisch 'rot')" 1 "Farbe 1 (typisch 'grün')" 0 "Symbol nicht beleuchtet" ;
VAL_ 786 FAS_Status_Anzeige 7 "ACC/GRA irreversibel aus" 6 "ACC reversibel aus (nicht bei GRA)" 5 "frei" 4 "ACC/GRA im Hintergrund (übertreten)" 3 "ACCGRA aktiv" 2 "ACC/GRA passiv" 1 "ACC in Init (nicht bei GRA)" 0 "ACC/GRA Hauptschalter aus" ;
